VERSION ""

NS_ :

BS_:

BU_: ZCUR HDBI HDBM CID ZCUF ZCUT HDBT HDBA ZCUL

BO_ 913 ZCUR_VB1_7: 32 ZCUR
 SG_ ZCUR_HSDPowerOff1_Req : 96|24@1+ (1,0) [0|0] ""  ZCUF,HDBM,CID
 SG_ ZCUR_RRDrStpRsn_St : 68|4@1+ (1,0) [0|15] ""  HDBM
 SG_ ZCUR_FRDrLth_Err : 3|3@1+ (1,0) [0|7] ""  HDBM
 SG_ ZCUR_RExMirCtrl_Rsp : 36|1@1+ (1,0) [0|1] ""  HDBM
 SG_ ZCUR_RRDrLth_Err : 59|3@1+ (1,0) [0|7] ""  HDBM
 SG_ ZCUR_FRSeatAdj_Req : 30|2@1+ (1,0) [0|3] ""  HDBM
 SG_ ZCUR_FRSeatBackrestAdj_Req : 37|2@1+ (1,0) [0|3] ""  HDBM
 SG_ ZCUR_SFRTnLtErr_St : 80|1@1+ (1,0) [0|1] ""  HDBM
 SG_ ZCUR_FRSeatHgtAdj_Req : 28|2@1+ (1,0) [0|3] ""  HDBM
 SG_ ZCUR_FRSeatCshnAngAdj_Req : 40|2@1+ (1,0) [0|3] ""  HDBM
 SG_ ZCUR_FRHdlFrz_St : 7|1@1+ (1,0) [0|1] ""  HDBM
 SG_ ZCUR_FRWdwSw_St : 16|3@1+ (1,0) [0|7] ""  HDBM
 SG_ ZCUR_FRWdwMov_St : 24|2@1+ (1,0) [0|3] ""  HDBM
 SG_ ZCUR_RRWdwMov_St : 76|2@1+ (1,0) [0|3] ""  HDBM
 SG_ ZCUR_FRHdlStpRsn_St : 19|4@1+ (1,0) [0|15] ""  HDBM
 SG_ ZCUR_RRHdlStpRsn_St : 32|4@1+ (1,0) [0|15] ""  HDBM
 SG_ ZCUR_FRLthAjar_St : 26|1@1+ (1,0) [0|1] ""  HDBM
 SG_ ZCUR_RRLthAjar_St : 72|1@1+ (1,0) [0|1] ""  HDBM
 SG_ ZCUR_FRLthHlfLck_St : 27|1@1+ (1,0) [0|1] ""  HDBM
 SG_ ZCUR_RRLthHlfLck_St : 74|1@1+ (1,0) [0|1] ""  HDBM
 SG_ ZCUR_FRLthPawl_St : 15|1@1+ (1,0) [0|1] ""  HDBM
 SG_ ZCUR_RRLthPawl_St : 63|1@1+ (1,0) [0|1] ""  HDBM
 SG_ ZCUR_FRLthHome_St : 75|1@1+ (1,0) [0|1] ""  HDBM
 SG_ ZCUR_RRLthHome_St : 73|1@1+ (1,0) [0|1] ""  HDBM
 SG_ ZCUR_FRDrLth_St : 0|3@1+ (1,0) [0|7] ""  HDBI,HDBM
 SG_ ZCUR_FRHdlClsPstSW_St : 6|1@1+ (1,0) [0|1] ""  HDBM
 SG_ ZCUR_RRDrLth_St : 56|3@1+ (1,0) [0|7] ""  HDBI,HDBM
 SG_ ZCUR_RRHdlClsPstSW_St : 62|1@1+ (1,0) [0|1] ""  HDBM
 SG_ ZCUR_FRDrLthWrk_St : 8|3@1+ (1,0) [0|7] ""  HDBM
 SG_ ZCUR_FRHdlOpnPstSW_St : 23|1@1+ (1,0) [0|1] ""  HDBM
 SG_ ZCUR_RRDrLthWrk_St : 64|3@1+ (1,0) [0|7] ""  HDBM
 SG_ ZCUR_RRHdlOpnPstSW_St : 78|1@1+ (1,0) [0|1] ""  HDBM
 SG_ ZCUR_FRDrStpRsn_St : 11|4@1+ (1,0) [0|15] ""  HDBM
 SG_ ZCUR_RRHdlFrz_St : 79|1@1+ (1,0) [0|1] ""  HDBM
 SG_ ZCUR_FRSeatLegAngCshnExtAdj_Req : 42|2@1+ (1,0) [0|3] ""  HDBM
 SG_ ZCUR_RRWdwSw_St : 81|3@1+ (1,0) [0|7] ""  HDBM
 SG_ ZCUR_RRDrStpRsn2_St : 84|4@1+ (1,0) [0|15] ""  HDBM
 SG_ ZCUR_FRDrStpRsn2_St : 44|4@1+ (1,0) [0|15] ""  HDBM
 SG_ ZCUR_RRDrLthWrk2_St : 88|3@1+ (1,0) [0|7] ""  HDBM
 SG_ ZCUR_FRDrLthWrk2_St : 48|3@1+ (1,0) [0|7] ""  HDBM
 SG_ ZCUR_FRSunshadeSW_St : 95|1@1+ (1,0) [0|1] ""  HDBM
 SG_ ZCUR_FRLumbSuppFBAdj_Req : 93|2@1+ (1,0) [0|3] ""  HDBM
 SG_ ZCUR_FRLumbSuppUDAdj_Req : 91|2@1+ (1,0) [0|3] ""  HDBM
 SG_ ZCUR_FRDrLth2_Err : 120|3@1+ (1,0) [0|7] ""  HDBM
 SG_ ZCUR_RRDrLth2_Err : 123|3@1+ (1,0) [0|7] ""  HDBM
 SG_ ZCUR_RExMirLRMv_St : 192|2@1+ (1,0) [0|3] ""  HDBM
 SG_ ZCUR_RExMirUDStpRsn_St : 164|4@1+ (1,0) [0|15] ""  HDBM
 SG_ ZCUR_RExMirUDStp_Req : 131|3@1+ (1,0) [0|7] ""  HDBM
 SG_ ZCUR_RExMirLRStpRsn_St : 160|4@1+ (1,0) [0|15] ""  HDBM
 SG_ ZCUR_RExMirLRStp_Req : 128|3@1+ (1,0) [0|7] ""  HDBM
 SG_ ZCUR_RExMirUDMv_St : 194|2@1+ (1,0) [0|3] ""  HDBM
 SG_ ZCUR_FRSeatFBMv_St : 198|2@1+ (1,0) [0|3] ""  HDBM
 SG_ ZCUR_FRSeatBackrestMv_St : 200|2@1+ (1,0) [0|3] ""  HDBM
 SG_ ZCUR_FRSeatHgtMv_St : 202|2@1+ (1,0) [0|3] ""  HDBM
 SG_ ZCUR_FRSeatCshnAngMv_St : 204|2@1+ (1,0) [0|3] ""  HDBM
 SG_ ZCUR_FRLegAngCshnExtMv_St : 206|2@1+ (1,0) [0|3] ""  HDBM
 SG_ ZCUR_FRSeatFBStpRsn_St : 172|4@1+ (1,0) [0|15] ""  HDBM
 SG_ ZCUR_FRSeatFBStp_Req : 139|3@1+ (1,0) [0|7] ""  HDBM
 SG_ ZCUR_FRLegAngCshnExtStp_Req : 155|3@1+ (1,0) [0|7] ""  HDBM
 SG_ ZCUR_FRSeatBackrestStpRsn_St : 176|4@1+ (1,0) [0|15] ""  HDBM
 SG_ ZCUR_FRSeatBackrestStp_Req : 144|3@1+ (1,0) [0|7] ""  HDBM
 SG_ ZCUR_FRSeatHgtStpRsn_St : 180|4@1+ (1,0) [0|15] ""  HDBM
 SG_ ZCUR_FRSeatHgtStp_Req : 147|3@1+ (1,0) [0|7] ""  HDBM
 SG_ ZCUR_FRSeatCshnAngStpRsn_St : 184|4@1+ (1,0) [0|15] ""  HDBM
 SG_ ZCUR_FRSeatCshnAngStp_Req : 152|3@1+ (1,0) [0|7] ""  HDBM
 SG_ ZCUR_FRLegAngCshnExtStpRsn_St : 188|4@1+ (1,0) [0|15] ""  HDBM
 SG_ ZCUR_FRHdlDbOprt_St : 126|2@1+ (1,0) [0|3] ""  HDBM
 SG_ ZCUR_RRHdlDbOprt_St : 134|2@1+ (1,0) [0|3] ""  HDBM
 SG_ ZCUR_RExMirCtrlStp_Req : 136|3@1+ (1,0) [0|7] ""  HDBM
 SG_ ZCUR_RExMirCtrlMv_St : 196|2@1+ (1,0) [0|3] ""  HDBM
 SG_ ZCUR_RExMirCtrlStpRsn_St : 168|4@1+ (1,0) [0|15] ""  HDBM
 SG_ ZCUR_FRSeatBelt_St : 39|1@1+ (1,0) [0|1] ""  HDBM

BO_ 96 ZCUF_VB1_1: 16 ZCUF
 SG_ ZCUF_ActlGearVaild_St : 35|1@1+ (1,0) [0|1] ""  HDBI,HDBM,HDBT
 SG_ ZCUF_ActlGear_St : 32|3@1+ (1,0) [0|7] ""  ZCUT,HDBM,HDBA,HDBT
 SG_ ZCUF_VehicleSpeed_Val : 16|13@1+ (0.05625,0) [0|300] "km/h"  ZCUT,HDBM
 SG_ ZCUF_VehicleSpeedValid_St : 15|1@1+ (1,0) [0|1] ""  ZCUT,HDBM
 SG_ ZCUF_FLTnLgt_St : 81|1@1+ (1,0) [0|1] ""  HDBM
 SG_ ZCUF_FRTnLgt_St : 77|1@1+ (1,0) [0|1] ""  HDBM
 SG_ ZCUF_Checksum4 : 0|8@1+ (1,0) [0|255] ""  ZCUT,HDBI,HDBM
 SG_ ZCUF_RollingCounter4 : 8|4@1+ (1,0) [0|15] ""  ZCUT,HDBI,HDBM
 SG_ ZCUF_LimpHomeRmnd_St : 36|1@1+ (1,0) [0|1] ""  HDBI,HDBM

BO_ 1441 ZCUF_VB1_7: 8 ZCUF
 SG_ ZCUF_HSDPowerOff1_Req : 16|24@1+ (1,0) [0|16777215] ""  HDBM

BO_ 352 HDBI_VB1_1: 32 HDBI
 SG_ HDBI_LowSpdVoi_Req : 160|2@1+ (1,0) [0|3] ""  HDBM
 SG_ HDBI_LowSpdVoiTyp_Req : 162|3@1+ (1,0) [0|7] ""  HDBM
 SG_ HDBI_NFCLockUnlock_Req : 126|2@1+ (1,0) [0|3] ""  HDBM
 SG_ HDBI_RLDoorBtn_Req : 100|2@1+ (1,0) [0|3] ""  HDBM
 SG_ HDBI_RearFogBm_Req : 110|2@1+ (1,0) [0|3] ""  HDBM
 SG_ HDBI_EtnlLgt_Req : 107|3@1+ (1,0) [0|7] ""  HDBM
 SG_ HDBI_CheckSum1 : 80|8@1+ (1,0) [0|255] ""  HDBM
 SG_ HDBI_RollingCounter1 : 88|4@1+ (1,0) [0|15] ""  HDBM

BO_ 272 HDBM_VB1_1: 32 HDBM
 SG_ HDBM_FLDoor_St : 16|2@1+ (1,0) [0|3] ""  HDBI,ZCUF
 SG_ HDBM_LeftTurnLgt_Req : 40|1@1+ (1,0) [0|1] ""  ZCUT,HDBI,ZCUF,ZCUL
 SG_ HDBM_RgtTurnLgt_Req : 41|1@1+ (1,0) [0|1] ""  ZCUT,HDBI,ZCUF,ZCUR
 SG_ HDBM_PowerMode_St : 32|3@1+ (1,0) [0|7] ""  ZCUT,HDBI,ZCUL,ZCUR,HDBT,ZCUF,HDBA
 SG_ HDBM_FRDoor_St : 18|2@1+ (1,0) [0|3] ""  HDBA
 SG_ HDBM_RLDoor_St : 20|2@1+ (1,0) [0|3] ""  HDBI
 SG_ HDBM_RRDoor_St : 22|2@1+ (1,0) [0|3] ""  HDBI
 SG_ HDBM_CheckSum1 : 0|8@1+ (1,0) [0|255] ""  ZCUT,ZCUF,ZCUL,HDBA,ZCUR
 SG_ HDBM_RollingCounter1 : 8|4@1+ (1,0) [0|15] ""  ZCUT,ZCUF,ZCUL,HDBA,ZCUR
 SG_ HDBM_TargCoastRegen_Req : 104|8@1+ (0.5,0) [0|100] "％"  ZCUF
 SG_ HDBM_DMSPTModeChg_Req : 80|4@1+ (1,0) [0|15] ""  ZCUF
 SG_ HDBM_DMSEPSModeChg_Req : 84|4@1+ (1,0) [0|15] "" Vector__XXX
 SG_ HDBM_DMSESCModeChg_Req : 88|4@1+ (1,0) [0|15] "" Vector__XXX
 SG_ HDBM_ChrgCap_St : 24|2@1+ (1,0) [0|3] ""  ZCUT

BO_ 689 HDBM_VB1_2: 32 HDBM
 SG_ HDBM_TCMACSOV_Req : 0|2@1+ (1,0) [0|3] "" Vector__XXX
 SG_ HDBM_TCMHPLowPressSOV_Req : 14|2@1+ (1,0) [0|3] "" Vector__XXX
 SG_ HDBM_TCMHPHighPressSOV_Req : 12|2@1+ (1,0) [0|3] "" Vector__XXX
 SG_ HDBM_HEXVInit_Req : 3|1@1+ (1,0) [0|1] "" Vector__XXX
 SG_ HDBM_CHVHTrgtPwr_Req : 32|8@1+ (50,0) [0|12000] "" Vector__XXX
 SG_ HDBM_CHVHHvCooltHeatEn_Req : 4|1@1+ (1,0) [0|1] "" Vector__XXX
 SG_ HDBM_HEXVSet_Req : 104|16@1+ (1,0) [0|576] "" Vector__XXX
 SG_ HDBM_V3WHeatEnb_Req : 6|1@1+ (1,0) [0|1] "" Vector__XXX
 SG_ HDBM_V3WHeatTargetPst_Req : 40|8@1+ (1,0) [0|100] "" Vector__XXX
 SG_ HDBM_HeatPumpEnb_Req : 7|1@1+ (1,0) [0|1] "" Vector__XXX
 SG_ HDBM_HeatPumpTargetSpdPct_Req : 48|8@1+ (1,0) [0|100] "" Vector__XXX
 SG_ HDBM_OHXEXVMoveEn_Req : 17|1@1+ (1,0) [0|1] "" Vector__XXX
 SG_ HDBM_CHLEXVMoveEn_Req : 16|1@1+ (1,0) [0|1] "" Vector__XXX
 SG_ HDBM_OHXEXVSet_Req : 72|16@1+ (1,0) [0|576] "" Vector__XXX
 SG_ HDBM_CHLEXVSet_Req : 56|16@1+ (1,0) [0|576] "" Vector__XXX
 SG_ HDBM_ComprActlPwr_Val : 88|8@1+ (100,0) [0|13000] ""  ZCUF
 SG_ HDBM_DMSVehMode_St : 168|4@1+ (1,0) [0|15] ""  ZCUF
 SG_ HDBM_CHVHActlPwr_Val : 96|8@1+ (100,0) [0|13000] ""  ZCUF
 SG_ HDBM_ACSysTotPwr_Req : 120|10@1+ (100,0) [0|40000] ""  ZCUF
 SG_ HDBM_DMSPTMode_St : 160|3@1+ (1,0) [0|7] ""  HDBI,ZCUF
 SG_ HDBM_DMSEPSModeInfo_St : 163|3@1+ (1,0) [0|7] ""  HDBI
 SG_ HDBM_ACHVTotoaPower_Req : 130|10@1+ (100,0) [0|40000] ""  ZCUF
 SG_ HDBM_SRRSBR_Req : 147|1@1+ (1,0) [0|1] ""  HDBI
 SG_ HDBM_SBRSound_Req : 148|1@1+ (1,0) [0|1] ""  HDBI
 SG_ HDBM_FLSBR_Req : 144|1@1+ (1,0) [0|1] ""  HDBI
 SG_ HDBM_FRSBR_Req : 145|1@1+ (1,0) [0|1] ""  HDBI
 SG_ HDBM_SRLSBR_Req : 146|1@1+ (1,0) [0|1] ""  HDBI
 SG_ HDBM_SRMSBR_Req : 149|1@1+ (1,0) [0|1] ""  HDBI
 SG_ HDBM_V3WHeatCalEnb_Req : 11|1@1+ (1,0) [0|1] "" Vector__XXX
 SG_ HDBM_OHXEXVInit_Req : 8|3@1+ (1,0) [0|7] "" Vector__XXX
 SG_ HDBM_CHLEXVInit_Req : 19|3@1+ (3,0) [0|7] "" Vector__XXX
 SG_ HDBM_CHVHTrgtTemp_Req : 24|8@1+ (1,-40) [-40|215] "℃" Vector__XXX
 SG_ HDBM_HEXVMoveEnb_Req : 18|1@1+ (1,0) [0|1] "" Vector__XXX
 SG_ HDBM_ACCMPwrLmt_Req : 216|8@1+ (100,0) [0|25400] "" Vector__XXX
 SG_ HDBM_ACCMErrorClean_Req : 210|2@1+ (1,0) [0|3] "" Vector__XXX
 SG_ HDBM_ACCMEnable_Req : 212|2@1+ (1,0) [0|3] "" Vector__XXX
 SG_ HDBM_ACCMSpdCtrl_Req : 200|10@1+ (15,0) [0|1022] "" Vector__XXX
 SG_ HDBM_CmpmtInAirPmDnsty_Val : 184|10@1+ (1,0) [0|1023] ""  HDBI
 SG_ HDBM_CmpmtInAirPmAQI_St : 194|3@1+ (1,0) [0|7] ""  HDBI

BO_ 1488 HDBM_VB1_3: 32 HDBM
 SG_ HDBM_FLTpmsPress_Val : 0|8@1+ (1.373,0) [0|350] "Kpa"  HDBI,ZCUF,HDBA
 SG_ HDBM_EnvirTemp_Val : 208|8@1+ (0.5,-40) [-40|80] "℃"  HDBI,ZCUF
 SG_ HDBM_ComprWork_St : 142|2@1+ (1,0) [0|3] ""  ZCUF
 SG_ HDBM_FragChannel3Life_Val : 160|9@1+ (1,0) [0|360] "h"  HDBI
 SG_ HDBM_FLTpmsTemp_Val : 32|8@1+ (1,-40) [-40|214] "°C"  HDBI
 SG_ HDBM_FragCh1Type_Spec : 172|4@1+ (1,0) [0|15] ""  HDBI
 SG_ HDBM_EnSvLtCtrl_Req : 120|2@1+ (1,0) [0|3] ""  ZCUT,ZCUL,ZCUR
 SG_ HDBM_FragChannel2Life_Val : 176|9@1+ (1,0) [0|360] "h"  HDBI
 SG_ HDBM_FragChannel3Life_St : 192|9@1+ (1,0) [0|360] "h"  HDBI
 SG_ HDBM_FragCh2Type_Spec : 188|4@1+ (1,0) [0|15] ""  HDBI
 SG_ HDBM_FragCh3Type_Spec : 204|4@1+ (1,0) [0|15] ""  HDBI
 SG_ HDBM_RACCoolOrHeatOrVent_St : 136|2@1+ (1,0) [0|3] ""  ZCUF
 SG_ HDBM_FRTpmsPress_Val : 8|8@1+ (1.373,0) [0|350] "Kpa"  HDBI,ZCUF,HDBA
 SG_ HDBM_RLTpmsPress_Val : 16|8@1+ (1.373,0) [0|350] "Kpa"  HDBI,ZCUF,HDBA
 SG_ HDBM_RRTpmsPress_Val : 24|8@1+ (1.373,0) [0|350] "Kpa"  HDBI,ZCUF,HDBA
 SG_ HDBM_FRTpmsTemp_Val : 40|8@1+ (1,-40) [-40|214] "°C"  HDBI,HDBA
 SG_ HDBM_InFilterLifeRemind : 148|4@1+ (1,0) [0|15] ""  HDBI
 SG_ HDBM_RLTpmsTemp_Val : 48|8@1+ (1,-40) [-40|214] "°C"  HDBI,HDBA
 SG_ HDBM_RRTpmsTemp_Val : 56|8@1+ (1,-40) [-40|214] "°C"  HDBI,HDBA
 SG_ HDBM_FrtDeiceDefog_St : 140|2@1+ (1,0) [0|3] ""  HDBI,ZCUF
 SG_ HDBM_CampingMode_Rsp : 128|2@1+ (1,0) [0|3] "" Vector__XXX
 SG_ HDBM_CarMode_St : 216|3@1+ (1,0) [0|7] ""  ZCUT,HDBI,ZCUF,HDBA,HDBT
 SG_ HDBM_CHVHWork_St : 144|2@1+ (1,0) [0|3] ""  ZCUF
 SG_ HDBM_FLHdlBrkCnt_Val : 104|3@1+ (1,0) [0|7] ""  ZCUL
 SG_ HDBM_RLHdlBrkCnt_Val : 72|3@1+ (1,0) [0|7] ""  ZCUL
 SG_ HDBM_FRHdlBrkCnt_Val : 107|3@1+ (1,0) [0|7] ""  ZCUR
 SG_ HDBM_RRHdlBrkCnt_Val : 75|3@1+ (1,0) [0|7] ""  ZCUR

BO_ 421 HDBM_VB1_4: 32 HDBM
 SG_ HDBM_FLTpmsTempWarn_St : 24|1@1+ (1,0) [0|1] ""  HDBI,HDBA
 SG_ HDBM_FRTpmsTempWarn_St : 25|1@1+ (1,0) [0|1] ""  HDBI,HDBA
 SG_ HDBM_FLTpmsLeakWarn_St : 28|1@1+ (1,0) [0|1] ""  HDBI
 SG_ HDBM_FRTpmsLeakWarn_St : 29|1@1+ (1,0) [0|1] ""  HDBI
 SG_ HDBM_RLTpmsLeakWarn_St : 30|1@1+ (1,0) [0|1] ""  HDBI
 SG_ HDBM_RRTpmsLeakWarn_St : 31|1@1+ (1,0) [0|1] ""  HDBI
 SG_ HDBM_RemFDefrostTime_Rsp : 112|6@1+ (1,0) [0|40] "min"  HDBT
 SG_ HDBM_RemVentilateRefine_Rsp : 118|2@1+ (1,0) [0|3] ""  HDBT
 SG_ HDBM_RemVentilateRefineTime_Rsp : 120|6@1+ (1,0) [0|40] "min"  HDBT
 SG_ HDBM_RemAppointActive_Rsp : 128|2@1+ (1,0) [0|3] ""  HDBT
 SG_ HDBM_RemACUnavailRsn_Spec : 132|3@1+ (1,0) [0|7] ""  HDBT
 SG_ HDBM_RLTpmsTempWarn_St : 26|1@1+ (1,0) [0|1] ""  HDBI,HDBA
 SG_ HDBM_RRTpmsTempWarn_St : 27|1@1+ (1,0) [0|1] ""  HDBI,HDBA
 SG_ HDBM_RLTpmsPressWarn_St : 20|2@1+ (1,0) [0|3] ""  HDBI,HDBA
 SG_ HDBM_RRTpmsPressWarn_St : 22|2@1+ (1,0) [0|3] ""  HDBI,HDBA
 SG_ HDBM_FLTpmsPressWarn_St : 16|2@1+ (1,0) [0|3] ""  HDBI,HDBA
 SG_ HDBM_FRTpmsPressWarn_St : 18|2@1+ (1,0) [0|3] ""  HDBI,HDBA
 SG_ HDBM_CheckSum2 : 0|8@1+ (1,0) [0|255] "" Vector__XXX
 SG_ HDBM_RollingCounter2 : 8|4@1+ (1,0) [0|15] "" Vector__XXX
 SG_ HDBM_RRTpmsBattle_St : 35|1@1+ (1,0) [0|1] ""  HDBI
 SG_ HDBM_FLTpmsSensorFailure_St : 36|1@1+ (1,0) [0|1] ""  HDBI
 SG_ HDBM_FRTpmsSensorFailure_St : 37|1@1+ (1,0) [0|1] ""  HDBI
 SG_ HDBM_RLTpmsSensorFailure_St : 38|1@1+ (1,0) [0|1] ""  HDBI
 SG_ HDBM_RRTpmsSensorFailure_St : 39|1@1+ (1,0) [0|1] ""  HDBI
 SG_ HDBM_FLTpmsBattle_St : 32|1@1+ (1,0) [0|1] ""  HDBI
 SG_ HDBM_FRTpmsBattle_St : 33|1@1+ (1,0) [0|1] ""  HDBI
 SG_ HDBM_RLTpmsBattle_St : 34|1@1+ (1,0) [0|1] ""  HDBI

BO_ 816 HDBM_VB1_5: 32 HDBM
 SG_ HDBM_BckLtBrtDes_Req : 180|4@1+ (1,0) [0|15] ""  ZCUL,ZCUR
 SG_ HDBM_FLTpLtBrtDes_Req : 216|4@1+ (1,0) [0|15] ""  ZCUL
 SG_ HDBM_RLTpLtBrtDes_Req : 228|4@1+ (1,0) [0|15] ""  ZCUL
 SG_ HDBM_HoodLatch_St : 150|2@1+ (1,0) [0|3] ""  HDBI,ZCUF,HDBA
 SG_ HDBM_FRTpLtBrtDes_Req : 220|4@1+ (1,0) [0|15] ""  ZCUL
 SG_ HDBM_RRTpLtBrtDes_Req : 224|4@1+ (1,0) [0|15] ""  ZCUL
 SG_ HDBM_EtnlLgt_Rsp : 186|2@1+ (1,0) [0|3] ""  HDBI
 SG_ HDBM_CenterLock_St : 154|2@1+ (1,0) [0|3] ""  ZCUT,HDBI
 SG_ HDBM_LwLgt_Req : 119|1@1+ (1,0) [0|1] ""  HDBI,ZCUF
 SG_ HDBM_ACFaultLevel_St : 192|3@1+ (1,0) [0|7] ""  ZCUF
 SG_ HDBM_FLPstnLgt_Req : 112|1@1+ (1,0) [0|1] ""  HDBI,ZCUF
 SG_ HDBM_FRPstnLgt_Req : 113|1@1+ (1,0) [0|1] ""  HDBI,ZCUF
 SG_ HDBM_HighLgt_Req : 118|1@1+ (1,0) [0|1] ""  HDBI,ZCUF
 SG_ HDBM_OtkLgt_Req : 163|1@1+ (1,0) [0|1] ""  HDBI,ZCUF
 SG_ HDBM_FLWdwCtl_Req : 24|3@1+ (1,0) [0|7] ""  ZCUL
 SG_ HDBM_FRWdwCtl_Req : 28|3@1+ (1,0) [0|7] ""  ZCUR
 SG_ HDBM_SteerTiltAdj_Req : 40|2@1+ (1,0) [0|3] ""  ZCUL
 SG_ HDBM_RLWdwCtl_Req : 32|3@1+ (1,0) [0|7] ""  ZCUL
 SG_ HDBM_SteerTeleAdj_Req : 42|2@1+ (1,0) [0|3] ""  ZCUL
 SG_ HDBM_FWiperCtrl_Req : 92|3@1+ (1,0) [0|7] ""  ZCUF
 SG_ HDBM_FWiperWashCtrl_Req : 95|1@1+ (1,0) [0|1] ""  ZCUF
 SG_ HDBM_FLHdlCtrl_Req : 8|3@1+ (1,0) [0|7] ""  ZCUL
 SG_ HDBM_RLHdlCtrl_Req : 16|3@1+ (1,0) [0|7] ""  ZCUL
 SG_ HDBM_FRHdlCtrl_Req : 11|3@1+ (1,0) [0|7] ""  ZCUR
 SG_ HDBM_TpLtClrDes_Req : 184|2@1+ (1,0) [0|1] "" Vector__XXX
 SG_ HDBM_RRHdlCtrl_Req : 19|3@1+ (1,0) [0|7] ""  ZCUR
 SG_ HDBM_RLPstnLgt_Req : 114|1@1+ (1,0) [0|1] ""  ZCUT,HDBI
 SG_ HDBM_RRPstnLgt_Req : 115|1@1+ (1,0) [0|1] ""  ZCUT,HDBI
 SG_ HDBM_RearFogBm_Req : 177|1@1+ (1,0) [0|1] ""  ZCUT
 SG_ HDBM_RRWdwCtl_Req : 36|3@1+ (1,0) [0|7] ""  ZCUR
 SG_ HDBM_RsLgt_Req : 195|1@1+ (1,0) [0|1] ""  ZCUT
 SG_ HDBM_TrkLtCtrl_Req : 161|2@1+ (1,0) [0|3] ""  ZCUT
 SG_ HDBM_RollingCounter3 : 72|4@1+ (1,0) [0|15] ""  ZCUT
 SG_ HDBM_CheckSum3 : 64|8@1+ (1,0) [0|255] ""  ZCUT
 SG_ HDBM_FRHdlLearn_Req : 234|2@1+ (1,0) [0|3] ""  ZCUR
 SG_ HDBM_RRHdlLearn_Req : 238|2@1+ (1,0) [0|3] ""  ZCUR
 SG_ HDBM_FLHdlLearn_Req : 232|2@1+ (1,0) [0|3] ""  ZCUL
 SG_ HDBM_RLHdlLearn_Req : 236|2@1+ (1,0) [0|3] ""  ZCUL
 SG_ HDBM_FLTpLtClrDes_Req : 188|2@1+ (1,0) [0|3] ""  ZCUL
 SG_ HDBM_RLTpLtClrDes_Req : 196|2@1+ (1,0) [0|3] ""  ZCUL
 SG_ HDBM_FRTpLtClrDes_Req : 190|2@1+ (1,0) [0|3] ""  ZCUL
 SG_ HDBM_RRTpLtClrDes_Req : 198|2@1+ (1,0) [0|3] ""  ZCUL
 SG_ HDBM_SteerTiltSpd_Req : 59|5@1+ (5,0) [0|100] ""  ZCUL
 SG_ HDBM_SteerTeleSpd_Req : 51|5@1+ (5,0) [0|100] ""  ZCUL
 SG_ HDBM_SteerLn_Req : 50|1@1+ (1,0) [0|1] ""  ZCUL
 SG_ HDBM_ParkingSwitch_Req : 88|2@1+ (1,0) [0|3] "" Vector__XXX
 SG_ HDBM_EHBMBrkModeSet_Req : 104|3@1+ (1,0) [0|7] "" Vector__XXX
 SG_ HDBM_TCSSw_Req : 90|2@1+ (1,0) [0|3] "" Vector__XXX
 SG_ HDBM_AVHSw_Req : 96|2@1+ (1,0) [0|3] "" Vector__XXX
 SG_ HDBM_HDCSw_Req : 98|2@1+ (1,0) [0|3] "" Vector__XXX
 SG_ HDBM_CSTSw_Req : 100|2@1+ (1,0) [0|3] "" Vector__XXX
 SG_ HDBM_ESCSw_Req : 102|2@1+ (1,0) [0|3] "" Vector__XXX

BO_ 1489 HDBM_VB1_6: 32 HDBM
 SG_ HDBM_FragSwitchEn_Rsp : 16|2@1+ (1,0) [0|3] ""  HDBI
 SG_ HDBM_FragCh1Sw_St : 18|2@1+ (1,0) [0|3] ""  HDBI
 SG_ HDBM_FragCh2Sw_St : 20|2@1+ (1,0) [0|3] ""  HDBI
 SG_ HDBM_FragCh3Sw_St : 22|2@1+ (1,0) [0|3] ""  HDBI
 SG_ HDBM_FragConcLvl_Rsp : 24|3@1+ (1,0) [0|7] ""  HDBI
 SG_ HDBM_AQSAirQuality_Val : 28|4@1+ (1,0) [0|15] ""  HDBI
 SG_ HDBM_PM25Set_St : 40|2@1+ (1,0) [0|3] ""  HDBI
 SG_ HDBM_PM25Trigger_St : 42|2@1+ (1,0) [0|3] ""  HDBI
 SG_ HDBM_FDeiceDefrost_Rsp : 44|2@1+ (1,0) [0|3] ""  HDBI,ZCUF,HDBT
 SG_ HDBM_AutoDefogSensDectect_St : 46|2@1+ (1,0) [0|3] ""  HDBI
 SG_ HDBM_AutoDefrostSet_St : 48|2@1+ (1,0) [0|3] ""  HDBI
 SG_ HDBM_AutoDefrostTrigger_St : 50|2@1+ (1,0) [0|3] ""  HDBI
 SG_ HDBM_IONSet_St : 52|2@1+ (1,0) [0|3] ""  HDBI
 SG_ HDBM_ACSwtich_St : 64|2@1+ (1,0) [0|3] ""  HDBI
 SG_ HDBM_FACSwitch_Rsp : 66|2@1+ (1,0) [0|3] ""  HDBI,HDBT
 SG_ HDBM_FACAirFlowLevel_St : 68|4@1+ (1,0) [0|15] ""  HDBI
 SG_ HDBM_FAcCoolOrHeatOrVent_St : 72|2@1+ (1,0) [0|3] ""  HDBI,ZCUF
 SG_ HDBM_FLeftTempSet_St : 74|6@1+ (1,0) [0|63] ""  HDBI
 SG_ HDBM_FRightTempSet_St : 88|6@1+ (1,0) [0|63] ""  HDBI
 SG_ HDBM_FTempAreaSync_St : 94|2@1+ (1,0) [0|3] ""  HDBI
 SG_ HDBM_HvOnACM_Req : 96|1@1+ (1,0) [0|1] ""  ZCUF
 SG_ HDBM_HVWork_Req : 97|1@1+ (1,0) [0|1] ""  ZCUF
 SG_ HDBM_RESSCoolFault_St : 98|2@1+ (1,0) [0|3] ""  ZCUF
 SG_ HDBM_FACAirFlowLevelAuto_St : 100|2@1+ (1,0) [0|3] ""  HDBI
 SG_ HDBM_FACAirFlowModeAuto_St : 102|2@1+ (1,0) [0|3] ""  HDBI
 SG_ HDBM_FACCoolOrHeatOrVentAuto_St : 104|2@1+ (1,0) [0|3] ""  HDBI
 SG_ HDBM_TDrDegDes_Req : 160|8@1+ (0.5,0) [0|100] ""  ZCUT
 SG_ HDBM_TDrDegSet_Rsp : 168|8@1+ (0.5,0) [0|100] "" Vector__XXX
 SG_ HDBM_LDRLgt_Req : 216|1@1+ (1,0) [0|1] ""  ZCUF
 SG_ HDBM_RDRLgt_Req : 217|1@1+ (1,0) [0|0] ""  ZCUF
 SG_ HDBM_FLDrPdlLtCtrl_Req : 224|2@1+ (1,0) [3|3] ""  ZCUL
 SG_ HDBM_FRDrPdlLtCtrl_Req : 226|2@1+ (1,0) [0|3] ""  ZCUR
 SG_ HDBM_RLDrPdlLtCtrl_Req : 228|2@1+ (1,0) [0|3] ""  ZCUL
 SG_ HDBM_RRDrPdlLtCtrl_Req : 230|2@1+ (1,0) [0|3] ""  ZCUR
 SG_ HDBM_FLDrCtrl_Req : 192|2@1+ (1,0) [0|3] ""  ZCUL
 SG_ HDBM_FRDrCtrl_Req : 194|2@1+ (1,0) [0|3] ""  ZCUR
 SG_ HDBM_RLDrCtrl_Req : 196|2@1+ (1,0) [0|3] ""  ZCUL
 SG_ HDBM_RRDrCtrl_Req : 198|2@1+ (1,0) [0|3] ""  ZCUR
 SG_ HDBM_FLDrLthCinch_Req : 200|3@1+ (1,0) [0|7] ""  ZCUL
 SG_ HDBM_TDrSpdDes_Req : 235|3@1+ (1,0) [0|7] ""  ZCUT
 SG_ HDBM_TDrCtrl_Req : 232|3@1+ (1,0) [0|7] ""  ZCUT
 SG_ HDBM_TDrLthCinch_Req : 218|3@1+ (1,0) [0|7] ""  ZCUT
 SG_ HDBM_RLDrLthCinch_Req : 208|3@1+ (1,0) [0|7] ""  ZCUL
 SG_ HDBM_FRDrLthCinch_Req : 203|3@1+ (1,0) [0|7] ""  ZCUR
 SG_ HDBM_RRDrLthCinch_Req : 211|3@1+ (1,0) [0|7] ""  ZCUR
 SG_ HDBM_RLDrLthRls_Req : 120|3@1+ (1,0) [0|7] ""  ZCUL
 SG_ HDBM_FRDrLthRls_Req : 115|3@1+ (1,0) [0|7] ""  ZCUR
 SG_ HDBM_RRDrLthRls_Req : 123|3@1+ (1,0) [0|7] ""  ZCUR
 SG_ HDBM_FLDrLthRls_Req : 112|3@1+ (1,0) [0|7] ""  ZCUL
 SG_ HDBM_RESSCoolPwrLim_St : 111|1@1+ (1,0) [0|1] ""  ZCUF
 SG_ HDBM_RESSHeatFault_St : 106|2@1+ (1,0) [0|3] ""  ZCUF
 SG_ HDBM_ACMWork_St : 80|2@1+ (1,0) [0|3] ""  ZCUF
 SG_ HDBM_HeatRecycle_Req : 32|1@1+ (1,0) [0|1] ""  ZCUF
 SG_ HDBM_DeiceDefog_Req : 34|2@1+ (1,0) [0|3] ""  ZCUF
 SG_ HDBM_HeatRecycleDisable_St : 33|1@1+ (1,0) [0|1] ""  ZCUF
 SG_ HDBM_ChrgCapCtrl_Req : 238|2@1+ (1,0) [0|3] ""  ZCUT
 SG_ HDBM_TDrLthRls_Req : 240|3@1+ (1,0) [0|7] ""  ZCUT
 SG_ HDBM_RRDrLthCinchFbd_Req : 254|2@1+ (1,0) [0|3] ""  ZCUR
 SG_ HDBM_FLDrLthCinchFbd_Req : 248|2@1+ (1,0) [0|3] ""  ZCUL
 SG_ HDBM_RLDrLthCinchFbd_Req : 252|2@1+ (1,0) [0|3] ""  ZCUL
 SG_ HDBM_FRDrLthCinchFbd_Req : 250|2@1+ (1,0) [0|3] ""  ZCUR
 SG_ HDBM_ChrgCapLearn_Req : 246|2@1+ (1,0) [0|3] ""  ZCUT
 SG_ HDBM_IONSwitch_Req : 36|2@1+ (1,0) [0|3] ""  ZCUR
 SG_ HDBM_InPm25SnsrActn_Req : 38|2@1+ (1,0) [0|3] ""  ZCUR
 SG_ HDBM_TDrLthCinchFbd_Req : 244|2@1+ (1,0) [0|3] ""  ZCUT

BO_ 210 EGSM_MCAN1_1: 8 HDBM

BO_ 1500 HDBM_VB1_NMIndication: 32 HDBM
 SG_ HDBM_VB1_NetworkReqCondition0 : 0|8@1+ (1,0) [0|255] "" Vector__XXX
 SG_ HDBM_VB1_NetworkReqCondition1 : 8|8@1+ (1,0) [0|255] "" Vector__XXX
 SG_ HDBM_VB1_NetworkReqCondition2 : 16|8@1+ (1,0) [0|255] "" Vector__XXX
 SG_ HDBM_VB1_NetworkReqCondition3 : 24|8@1+ (1,0) [0|255] "" Vector__XXX
 SG_ HDBM_VB1_NetworkReqCondition4 : 32|8@1+ (1,0) [0|255] "" Vector__XXX
 SG_ HDBM_VB1_NetworkReqCondition5 : 40|8@1+ (1,0) [0|255] "" Vector__XXX
 SG_ HDBM_VB1_NetworkReqCondition6 : 48|8@1+ (1,0) [0|255] "" Vector__XXX
 SG_ HDBM_VB1_NetworkReqCondition7 : 56|8@1+ (1,0) [0|255] "" Vector__XXX
 SG_ HDBM_VB1_NetworkReqCondition8 : 64|8@1+ (1,0) [0|255] "" Vector__XXX
 SG_ HDBM_VB1_NetworkReqCondition9 : 72|8@1+ (1,0) [0|255] "" Vector__XXX
 SG_ HDBM_VB1_NetworkReqCondition10 : 80|8@1+ (1,0) [0|255] "" Vector__XXX
 SG_ HDBM_VB1_NetworkReqCondition11 : 88|8@1+ (1,0) [0|255] "" Vector__XXX
 SG_ HDBM_VB1_NetworkReqCondition12 : 96|8@1+ (1,0) [0|255] "" Vector__XXX
 SG_ HDBM_VB1_NetworkReqCondition13 : 104|8@1+ (1,0) [0|255] "" Vector__XXX
 SG_ HDBM_VB1_NetworkReqCondition14 : 112|8@1+ (1,0) [0|255] "" Vector__XXX
 SG_ HDBM_VB1_NetworkReqCondition15 : 120|8@1+ (1,0) [0|255] "" Vector__XXX
 SG_ HDBM_VB1_NetworkReqCondition16 : 128|8@1+ (1,0) [0|255] "" Vector__XXX
 SG_ HDBM_VB1_NetworkReqCondition17 : 136|8@1+ (1,0) [0|255] "" Vector__XXX
 SG_ HDBM_VB1_NetworkReqCondition18 : 144|8@1+ (1,0) [0|255] "" Vector__XXX
 SG_ HDBM_VB1_NetworkReqCondition19 : 152|8@1+ (1,0) [0|255] "" Vector__XXX
 SG_ HDBM_VB1_NetworkReqCondition20 : 160|8@1+ (1,0) [0|255] "" Vector__XXX
 SG_ HDBM_VB1_NetworkReqCondition21 : 168|8@1+ (1,0) [0|255] "" Vector__XXX
 SG_ HDBM_VB1_NetworkReqCondition22 : 176|8@1+ (1,0) [0|255] "" Vector__XXX
 SG_ HDBM_VB1_NetworkReqCondition23 : 184|8@1+ (1,0) [0|255] "" Vector__XXX
 SG_ HDBM_VB1_NetworkReqCondition24 : 192|8@1+ (1,0) [0|255] "" Vector__XXX
 SG_ HDBM_VB1_NetworkReqCondition25 : 200|8@1+ (1,0) [0|255] "" Vector__XXX
 SG_ HDBM_VB1_NetworkReqCondition26 : 208|8@1+ (1,0) [0|255] "" Vector__XXX
 SG_ HDBM_VB1_NetworkReqCondition27 : 216|8@1+ (1,0) [0|255] "" Vector__XXX
 SG_ HDBM_VB1_NetworkReqCondition28 : 224|8@1+ (1,0) [0|255] "" Vector__XXX
 SG_ HDBM_VB1_NetworkReqCondition29 : 232|8@1+ (1,0) [0|255] "" Vector__XXX
 SG_ HDBM_VB1_NetworkReqCondition30 : 240|8@1+ (1,0) [0|255] "" Vector__XXX
 SG_ HDBM_VB1_NetworkReqCondition31 : 248|8@1+ (1,0) [0|255] "" Vector__XXX

BO_ 1409 HDBM_NMWakeup: 32 HDBM
 SG_ HDBM_WakeupReq_HDBT : 0|1@1+ (1,0) [0|1] ""  HDBT
 SG_ HDBM_WakeupReq_HDBI : 8|8@1+ (1,0) [0|255] ""  HDBI
 SG_ HDBM_WakeupReq_HDBA : 16|8@1+ (1,0) [0|255] ""  HDBA
 SG_ HDBM_WakeupReq_HDBM : 24|8@1+ (1,0) [0|255] "" Vector__XXX
 SG_ HDBM_WakeupReq_ZCUF : 32|56@1+ (1,0) [0|0] ""  ZCUF
 SG_ HDBM_WakeupReq_ZCUL : 88|56@1+ (1,0) [0|0] ""  ZCUL
 SG_ HDBM_WakeupReq_ZCUR : 144|56@1+ (1,0) [0|0] ""  ZCUR
 SG_ HDBM_WakeupReq_ZCUT : 200|56@1+ (1,0) [0|0] ""  ZCUT

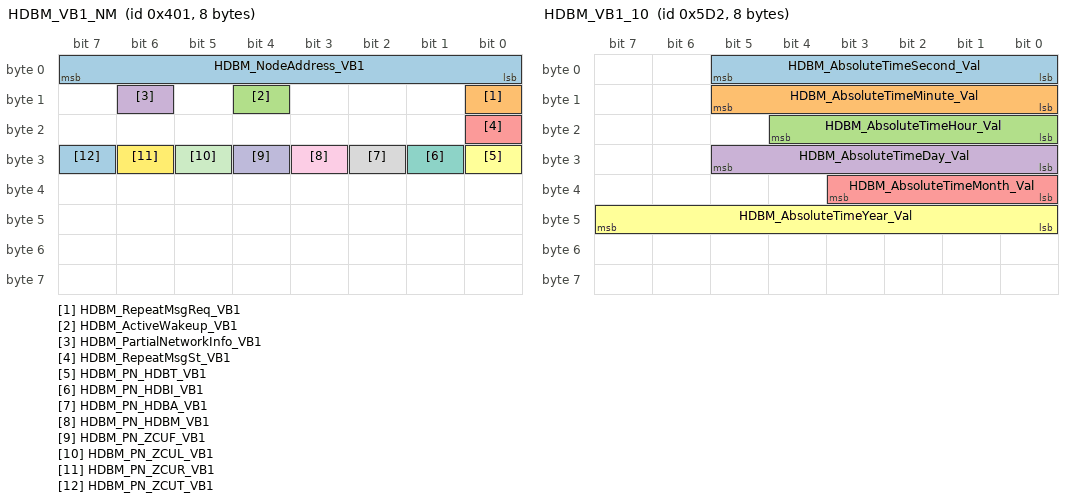
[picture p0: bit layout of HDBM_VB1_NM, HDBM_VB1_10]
BO_ 1025 HDBM_VB1_NM: 8 HDBM
 SG_ HDBM_NodeAddress_VB1 : 0|8@1+ (1,0) [0|255] ""  HDBI,ZCUF,ZCUL,HDBA,HDBT,ZCUR
 SG_ HDBM_RepeatMsgReq_VB1 : 8|1@1+ (1,0) [0|1] ""  ZCUT,HDBI,ZCUF,ZCUL,HDBA,HDBT,ZCUR
 SG_ HDBM_ActiveWakeup_VB1 : 12|1@1+ (1,0) [0|1] ""  ZCUT,HDBI,ZCUF,ZCUL,HDBA,HDBT,ZCUR
 SG_ HDBM_PartialNetworkInfo_VB1 : 14|1@1+ (1,0) [0|1] ""  ZCUT,HDBI,ZCUF,ZCUL,HDBA,HDBT,ZCUR
 SG_ HDBM_RepeatMsgSt_VB1 : 16|1@1+ (1,0) [0|1] ""  ZCUT,HDBI,ZCUF,ZCUL,HDBA,HDBT,ZCUR
 SG_ HDBM_PN_HDBT_VB1 : 24|1@1+ (1,0) [0|1] ""  ZCUT,HDBI,ZCUF,ZCUL,HDBA,HDBT,ZCUR
 SG_ HDBM_PN_HDBI_VB1 : 25|1@1+ (1,0) [0|1] ""  ZCUT,HDBI,ZCUF,ZCUL,HDBA,HDBT,ZCUR
 SG_ HDBM_PN_HDBA_VB1 : 26|1@1+ (1,0) [0|1] ""  ZCUT,HDBI,ZCUF,ZCUL,HDBA,HDBT,ZCUR
 SG_ HDBM_PN_HDBM_VB1 : 27|1@1+ (1,0) [0|1] ""  ZCUT,HDBI,ZCUF,ZCUL,HDBA,HDBT,ZCUR
 SG_ HDBM_PN_ZCUF_VB1 : 28|1@1+ (1,0) [0|1] ""  ZCUT,HDBI,ZCUF,ZCUL,HDBA,HDBT,ZCUR
 SG_ HDBM_PN_ZCUL_VB1 : 29|1@1+ (1,0) [0|1] ""  ZCUT,HDBI,ZCUF,ZCUL,HDBA,HDBT,ZCUR
 SG_ HDBM_PN_ZCUR_VB1 : 30|1@1+ (1,0) [0|1] ""  ZCUT,HDBI,ZCUF,ZCUL,HDBA,ZCUR,HDBT
 SG_ HDBM_PN_ZCUT_VB1 : 31|1@1+ (1,0) [0|1] ""  ZCUT,HDBI,ZCUF,ZCUL,HDBA,HDBT,ZCUR

BO_ 690 HDBM_VB1_7: 32 HDBM
 SG_ HDBM_BrkLgt_Req : 16|1@1+ (1,0) [0|1] ""  ZCUT
 SG_ HDBM_Horn_Req : 17|1@1+ (1,0) [0|1] ""  ZCUF
 SG_ HDBM_KeyResearch_Req : 18|2@1+ (1,0) [0|3] ""  HDBI
 SG_ HDBM_HHChrgPileRecognize_St : 72|1@1+ (1,0) [0|1] ""  ZCUT
 SG_ HDBM_AGSEn_Req : 152|1@1+ (1,0) [0|1] ""  ZCUF
 SG_ HDBM_AGSPosition_Req : 160|8@1+ (1,0) [0|255] ""  ZCUF
 SG_ HDBM_ECFEn_Req : 153|1@1+ (1,0) [0|1] ""  ZCUF
 SG_ HDBM_ECFSpdPercent_Req : 168|8@1+ (1,0) [0|100] ""  ZCUF
 SG_ HDBM_FHVACLeftMixPos_Req : 80|10@1+ (1,0) [0|1000] "千分比" Vector__XXX
 SG_ HDBM_FHVACRigtMixPos_Req : 90|10@1+ (1,0) [0|1000] "千分比"  ZCUR
 SG_ HDBM_FHVACModePos_Req : 100|10@1+ (1,0) [0|1000] "千分比" Vector__XXX
 SG_ HDBM_FHVACCyclePos_Req : 110|10@1+ (1,0) [0|1000] ""  ZCUR
 SG_ HDBM_FHVACBypassPos_Req : 130|10@1+ (1,0) [0|1000] "千分比"  ZCUR
 SG_ HDBM_FHVACDefrostPos_Req : 140|10@1+ (1,0) [0|1000] "千分比"  ZCUR
 SG_ HDBM_FHVACBLWPWM_Req : 120|10@1+ (1,0) [0|1000] "千分比" Vector__XXX
 SG_ HDBM_FHVACBLWRelay_Req : 40|2@1+ (1,0) [0|3] ""  ZCUR
 SG_ HDBM_OTAMode_St : 42|3@1+ (1,0) [0|7] ""  ZCUF

BO_ 422 HDBM_VB1_8: 32 HDBM
 SG_ HDBM_FRSeatMsgStrth_Req : 109|3@1+ (1,0) [0|7] ""  ZCUR
 SG_ HDBM_SRLSeatHt_Req : 128|5@1+ (5,0) [0|100] ""  ZCUT
 SG_ HDBM_SRLSeatVtlt_Req : 136|5@1+ (5,0) [0|100] ""  ZCUT
 SG_ HDBM_SRRSeatHt_Req : 144|5@1+ (5,0) [0|100] ""  ZCUT
 SG_ HDBM_SRRSeatVtlt_Req : 152|5@1+ (5,0) [0|100] ""  ZCUT
 SG_ HDBM_SteerHt_Req : 160|5@1+ (5,0) [0|100] ""  ZCUL
 SG_ HDBM_ExMirHt_Req : 168|5@1+ (5,0) [0|100] ""  ZCUL,ZCUR
 SG_ HDBM_FLSeatHt_Req : 80|5@1+ (5,0) [0|100] ""  ZCUL
 SG_ HDBM_FLSeatVtlt_Req : 88|5@1+ (5,0) [0|100] ""  ZCUL
 SG_ HDBM_FLSeatMsg_Req : 96|2@1+ (1,0) [0|3] ""  ZCUL
 SG_ HDBM_FLSeatMsgMode_Req : 98|4@1+ (1,0) [0|15] ""  ZCUL
 SG_ HDBM_FLSeatMsgStrth_Req : 85|3@1+ (1,0) [0|7] ""  ZCUL
 SG_ HDBM_FRSeatHt_Req : 104|5@1+ (5,0) [0|100] ""  ZCUR
 SG_ HDBM_FRSeatVtlt_Req : 112|5@1+ (5,0) [0|100] ""  ZCUR
 SG_ HDBM_FRSeatMsg_Req : 120|2@1+ (1,0) [0|3] ""  ZCUR
 SG_ HDBM_FRSeatMsgMode_Req : 122|4@1+ (1,0) [0|15] ""  ZCUR

BO_ 423 HDBM_VB1_9: 32 HDBM
 SG_ HDBM_FLSeatHgtAdj_Req : 46|2@1+ (1,0) [0|3] ""  ZCUL
 SG_ HDBM_FRLegAngCshnExtAdj_Req : 78|2@1+ (1,0) [0|3] ""  ZCUR
 SG_ HDBM_FLSeatFBAdjSpd_Req : 16|5@1+ (5,0) [0|100] ""  ZCUL
 SG_ HDBM_FLLegAngCshnExtAdj_Req : 38|2@1+ (1,0) [0|3] ""  ZCUL
 SG_ HDBM_FLSeatBackrestAdjSpd_Req : 24|5@1+ (5,0) [0|100] ""  ZCUL
 SG_ HDBM_FLSeatHgtAdjSpd_Req : 32|5@1+ (5,0) [0|100] ""  ZCUL
 SG_ HDBM_FLSeatCshnAngAdjSpd_Req : 40|5@1+ (5,0) [0|100] ""  ZCUL
 SG_ HDBM_FLLegAngCshnExtAdjSpd_Req : 48|5@1+ (5,0) [0|100] ""  ZCUL
 SG_ HDBM_FRSeatFBAdjSpd_Req : 56|5@1+ (5,0) [0|100] ""  ZCUR
 SG_ HDBM_FRSeatBackrestAdjSpd_Req : 64|5@1+ (5,0) [0|100] ""  ZCUR
 SG_ HDBM_FRSeatHgtAdjSpd_Req : 72|5@1+ (5,0) [0|100] ""  ZCUR
 SG_ HDBM_FRSeatCshnAngAdjSpd_Req : 80|5@1+ (5,0) [0|100] ""  ZCUR
 SG_ HDBM_FRLegAngCshnExtAdjSpd_Req : 88|5@1+ (5,0) [0|100] ""  ZCUR
 SG_ HDBM_FLLumbSuppFBAdj_Req : 22|2@1+ (1,0) [0|3] ""  ZCUL
 SG_ HDBM_FLLumbSuppUDAdj_Req : 30|2@1+ (1,0) [0|3] ""  ZCUL
 SG_ HDBM_FRLumbSuppFBAdj_Req : 70|2@1+ (1,0) [0|3] ""  ZCUR
 SG_ HDBM_FRLumbSuppUDAdj_Req : 62|2@1+ (1,0) [0|3] ""  ZCUR
 SG_ HDBM_FLSeatCshnAngAdj_Req : 144|2@1+ (1,0) [0|3] ""  ZCUL
 SG_ HDBM_FLSeatFBAdj_Req : 146|2@1+ (1,0) [0|3] ""  ZCUL
 SG_ HDBM_FLSeatBackrestAdj_Req : 148|2@1+ (1,0) [0|3] ""  ZCUL
 SG_ HDBM_FRSeatHgtAdj_Req : 86|2@1+ (1,0) [0|3] ""  ZCUR
 SG_ HDBM_FRSeatFBAdj_Req : 98|2@1+ (1,0) [0|3] ""  ZCUR
 SG_ HDBM_FRSeatBackrestAdj_Req : 100|2@1+ (1,0) [0|3] ""  ZCUR
 SG_ HDBM_FRSeatCshnAngAdj_Req : 96|2@1+ (1,0) [0|3] ""  ZCUR
 SG_ HDBM_RExMirUDAdj_Req : 124|2@1+ (1,0) [0|3] ""  ZCUR
 SG_ HDBM_RExMirLRAdj_Req : 126|2@1+ (1,0) [0|3] ""  ZCUR
 SG_ HDBM_LExMirUDAdj_Req : 120|2@1+ (1,0) [0|3] ""  ZCUL
 SG_ HDBM_LExMirLRAdj_Req : 122|2@1+ (1,0) [0|3] ""  ZCUL
 SG_ HDBM_RollingCounter4 : 136|4@1+ (1,0) [0|15] ""  ZCUL,ZCUR
 SG_ HDBM_CheckSum4 : 128|8@1+ (1,0) [0|255] ""  ZCUL,ZCUR
 SG_ HDBM_LExMirCtrl_Req : 109|2@1+ (1,0) [0|3] ""  ZCUL
 SG_ HDBM_RExMirCtrl_Req : 117|2@1+ (1,0) [0|3] ""  ZCUR
 SG_ HDBM_LExMirCtrlSpd_Req : 104|5@1+ (5,0) [0|100] ""  ZCUL
 SG_ HDBM_RExMirCtrlSpd_Req : 112|5@1+ (5,0) [0|100] ""  ZCUR
 SG_ HDBM_RExMirLRAdjSpd_Req : 200|5@1+ (5,0) [0|100] ""  ZCUR
 SG_ HDBM_LExMirUDAdjSpd_Req : 192|5@1+ (5,0) [0|100] ""  ZCUL
 SG_ HDBM_LExMirLRAdjSpd_Req : 184|5@1+ (5,0) [0|100] ""  ZCUL
 SG_ HDBM_RExMirUDAdjSpd_Req : 208|5@1+ (5,0) [0|100] ""  ZCUR

BO_ 1490 HDBM_VB1_10: 8 HDBM
 SG_ HDBM_AbsoluteTimeSecond_Val : 0|6@1+ (1,0) [0|59] "Second"  ZCUT,ZCUF
 SG_ HDBM_AbsoluteTimeMinute_Val : 8|6@1+ (1,0) [0|59] "Minute"  ZCUT,ZCUF
 SG_ HDBM_AbsoluteTimeHour_Val : 16|5@1+ (1,0) [0|23] "Hour"  ZCUT,ZCUF
 SG_ HDBM_AbsoluteTimeDay_Val : 24|6@1+ (1,0) [1|31] "Day"  ZCUT
 SG_ HDBM_AbsoluteTimeMonth_Val : 32|4@1+ (1,0) [1|12] "Month"  ZCUT,ZCUF
 SG_ HDBM_AbsoluteTimeYear_Val : 40|8@1+ (1,1970) [1970|2100] "Year"  ZCUT,ZCUF

BO_ 817 HDBM_VB1_11: 32 HDBM
 SG_ HDBM_RemCtrlACDuration_Req : 16|6@1+ (1,0) [0|40] "min" Vector__XXX
 SG_ HDBM_RemCtrlACRevnActive_Req : 22|2@1+ (1,0) [0|3] "" Vector__XXX
 SG_ HDBM_RemCtrlThmlMag_Req : 26|2@1+ (1,0) [0|3] ""  ZCUF
 SG_ HDBM_RemCtrlFACAuto_Req : 28|2@1+ (1,0) [0|3] "" Vector__XXX
 SG_ HDBM_RemCtrlThmlMagDurn_Req : 32|10@1+ (1,0) [0|1000] "min" Vector__XXX
 SG_ HDBM_RemCtrlFACDfrDef_Req : 42|2@1+ (1,0) [0|3] "" Vector__XXX
 SG_ HDBM_RemCtrlAirClean_Req : 44|2@1+ (1,0) [0|3] "" Vector__XXX
 SG_ HDBM_RemCtrlAirCleanDurn_Req : 48|6@1+ (1,0) [0|40] "min" Vector__XXX
 SG_ HDBM_FLBckupDoorCtrl_Req : 136|2@1+ (1,0) [0|3] "" Vector__XXX
 SG_ HDBM_FRBckupDoorCtrl_Req : 138|2@1+ (1,0) [0|3] "" Vector__XXX
 SG_ HDBM_RLBckupDoorCtrl_Req : 140|2@1+ (1,0) [0|3] "" Vector__XXX
 SG_ HDBM_RRBckupDoorCtrl_Req : 142|2@1+ (1,0) [0|3] "" Vector__XXX
 SG_ HDBM_Whitelistsync_Req : 64|4@1+ (1,0) [0|7] ""  HDBI
 SG_ HDBM_RollingCounter6 : 128|4@1+ (1,0) [0|15] "" Vector__XXX
 SG_ HDBM_CheckSum6 : 120|8@1+ (1,0) [0|255] "" Vector__XXX

BO_ 353 HDBM_VB1_12: 32 HDBM
 SG_ HDBM_PowertrainRestrict_Req : 80|2@1+ (1,0) [0|3] ""  ZCUF
 SG_ HDBM_ChargeCutOffSOC_Req : 24|8@1+ (0.5,0) [0|100] ""  ZCUT

BO_ 128 HBDM_VB1_13: 32 HDBM
 SG_ HDBM_AmLtTarget1_Req : 0|8@1+ (1,0) [0|255] ""  ZCUL
 SG_ HDBM_AmLtTarget2_Req : 8|8@1+ (1,0) [0|255] ""  ZCUR
 SG_ HDBM_AmLtTarget3_Req : 16|8@1+ (1,0) [0|255] ""  ZCUL
 SG_ HDBM_AmLtBrt_Req : 32|8@1+ (1,0) [0|255] ""  ZCUL,ZCUR
 SG_ HDBM_AmLtRedVal_Req : 40|8@1+ (1,0) [0|255] ""  ZCUL,ZCUR
 SG_ HDBM_AmLtGreenVal_Req : 48|8@1+ (1,0) [0|255] ""  ZCUL,ZCUR
 SG_ HDBM_AmLtBlueVal_Req : 56|8@1+ (1,0) [0|255] ""  ZCUL,ZCUR
 SG_ HDBM_AmLtSpd_Req : 64|4@1+ (1,0) [0|15] ""  ZCUL,ZCUR
 SG_ HDBM_AmLtHornClrMd_Req : 68|2@1+ (1,0) [0|3] ""  ZCUL,ZCUR
 SG_ HDBM_AmLtHornWrkMd_Req : 70|2@1+ (1,0) [0|3] ""  ZCUL,ZCUR

BO_ 80 ZCUT_VB1_1: 32 ZCUT
 SG_ ZCUT_BatteryVolt_Val : 154|12@1+ (0.25,0) [0|1023.25] "V"  HDBI,ZCUF,HDBM

BO_ 81 ZCUT_VB1_2: 32 ZCUT
 SG_ ZCUT_DCCharge_St : 200|4@1+ (1,0) [0|15] ""  HDBI,ZCUF,HDBM
 SG_ ZCUT_ACCharge_St : 204|4@1+ (1,0) [0|15] ""  HDBI,ZCUF,HDBM
 SG_ ZCUT_CellOverTemp_St : 38|1@1+ (1,0) [0|1] ""  HDBI,ZCUF,HDBM
 SG_ ZCUT_RLBrkLgt_St : 128|1@1+ (1,0) [0|1] ""  HDBM
 SG_ ZCUT_HighBrkLgt_St : 129|1@1+ (1,0) [0|1] ""  HDBM
 SG_ ZCUT_RRBrkLgt_St : 130|1@1+ (1,0) [0|1] ""  HDBM
 SG_ ZCUT_State_St : 208|4@1+ (1,0) [0|15] ""  ZCUF,HDBM
 SG_ ZCUT_FastChrgCnctor_St : 22|2@1+ (1,0) [0|3] ""  HDBI,ZCUF,HDBM
 SG_ ZCUT_Current_Val : 168|16@1+ (0.1,-1500) [-1500|2500] "A"  HDBI,ZCUF,HDBM
 SG_ ZCUT_SOCDisplay_Val : 136|10@1+ (0.1,0) [0|100] "%"  HDBI,ZCUF,HDBM
 SG_ ZCUT_FaultLevel_Err : 24|4@1+ (1,0) [0|15] ""  ZCUF,HDBM

BO_ 208 ZCUT_VB1_3: 16 ZCUT
 SG_ ZCUT_RLTnLgt_St : 16|1@1+ (1,0) [0|1] ""  HDBM
 SG_ ZCUT_RRTnLgt_St : 17|1@1+ (1,0) [0|1] ""  HDBM
 SG_ ZCUT_ChrgCapSW_St : 32|3@1+ (1,0) [0|7] ""  HDBM

BO_ 544 ZCUT_VB1_4: 32 ZCUT
 SG_ ZCUT_ChrgDischrgCnct_St : 12|3@1+ (1,0) [0|7] ""  HDBI,ZCUF,HDBM,CID
 SG_ ZCUT_TrkLtWrk_St : 67|2@1+ (1,0) [0|3] ""  HDBM
 SG_ ZCUT_RLPstnLgt_St : 69|1@1+ (1,0) [0|1] ""  HDBM
 SG_ ZCUT_RRPstnLgt_St : 65|1@1+ (1,0) [0|1] ""  HDBM
 SG_ ZCUT_RLTnLgtErr_St : 24|1@1+ (1,0) [0|1] ""  HDBM
 SG_ ZCUT_RRTnLgtErr_St : 25|1@1+ (1,0) [0|1] ""  HDBM
 SG_ ZCUT_SRLSeatOcp_St : 26|2@1+ (1,0) [0|3] ""  HDBM
 SG_ ZCUT_SRRSeatOcp_St : 28|2@1+ (1,0) [0|3] ""  HDBM
 SG_ ZCUT_SRMSeatOcp_St : 30|2@1+ (1,0) [0|3] ""  HDBM
 SG_ ZCUT_TempModuMax_Val : 16|8@1+ (1,-40) [-40|120] "℃"  ZCUF,HDBM
 SG_ ZCUT_TRLSeatOcp_St : 74|2@1+ (1,0) [0|3] ""  HDBM
 SG_ ZCUT_TRRSeatOcp_St : 72|2@1+ (1,0) [0|3] ""  HDBM
 SG_ ZCUT_TempModuMin_Val : 88|8@1+ (1,-40) [-40|120] "℃"  ZCUF,HDBM
 SG_ ZCUT_SOCReal_Val : 160|10@1+ (0.1,0) [0|100] "%"  ZCUF,HDBM
 SG_ ZCUT_Checksum4 : 0|8@1+ (1,0) [0|255] ""  ZCUF,HDBM
 SG_ ZCUT_RollingCounter4 : 8|4@1+ (1,0) [0|15] ""  ZCUF,HDBM
 SG_ ZCUT_RearMirLtWrk_St : 40|2@1+ (1,0) [0|3] ""  HDBM
 SG_ ZCUT_RLRsLgt_St : 85|1@1+ (1,0) [0|1] ""  HDBM
 SG_ ZCUT_RRRsLgt_St : 84|1@1+ (1,0) [0|1] ""  HDBM
 SG_ ZCUT_ChrgCutOffSOCSetVal_Rsp : 208|8@1+ (0.5,0) [0|100] ""  HDBI,ZCUF,HDBM,HDBT
 SG_ ZCUT_HHchrgPileCnct_St : 111|1@1+ (1,0) [0|1] ""  HDBI,HDBM
 SG_ ZCUT_TRLSeatBelt_St : 70|1@1+ (1,0) [0|1] ""  HDBM
 SG_ ZCUT_TRRSeatBelt_St : 71|1@1+ (1,0) [0|1] ""  HDBM
 SG_ ZCUT_SRLSeatBelt_St : 76|1@1+ (1,0) [0|1] ""  HDBM
 SG_ ZCUT_SRMSeatBelt_St : 77|1@1+ (1,0) [0|1] ""  HDBM
 SG_ ZCUT_SRRSeatBelt_St : 78|1@1+ (1,0) [0|1] ""  HDBM
 SG_ ZCUT_DisplayCharge_St : 156|4@1+ (1,0) [0|15] ""  HDBI,HDBM

BO_ 548 ZCUT_VB1_5: 32 ZCUT
 SG_ ZCUT_HSDLVPower_St : 72|48@1+ (1,0) [0|0] ""  HDBM
 SG_ ZCUT_PERMLVPower_St : 136|16@1+ (1,0) [0|65535] ""  HDBM
 SG_ ZCUT_HSDLVPower_Err : 24|48@1+ (1,0) [0|0] ""  HDBM
 SG_ ZCUT_PERMLVPower_Err : 120|16@1+ (1,0) [0|65535] ""  HDBM

BO_ 929 ZCUT_VB1_7: 32 ZCUT
 SG_ ZCUT_TempModuMaxID_Dat : 104|8@1+ (1,0) [0|254] ""  HDBM
 SG_ ZCUT_TempModuMinID_Dat : 96|8@1+ (1,0) [0|254] ""  HDBM
 SG_ ZCUT_OverCharge_St : 13|1@1+ (1,0) [0|1] ""  HDBM
 SG_ ZCUT_TempProbeNum_Val : 24|6@1+ (1,0) [0|63] ""  HDBM
 SG_ ZCUT_VoltCellMaxID_Dat : 88|8@1+ (1,0) [0|254] ""  HDBM
 SG_ ZCUT_SubTempHighID_Dat : 40|8@1+ (1,0) [0|254] ""  HDBM
 SG_ ZCUT_VoltCellMax_Val : 64|16@1+ (1,0) [0|5000] "mV"  HDBM
 SG_ ZCUT_SubTempLowID_Dat : 32|8@1+ (1,0) [0|254] ""  HDBM
 SG_ ZCUT_VoltCellMinID_Dat : 80|8@1+ (1,0) [0|254] ""  HDBM
 SG_ ZCUT_SubRESSNum_Val : 120|8@1+ (1,0) [0|254] ""  HDBM
 SG_ ZCUT_VoltCellMin_Val : 48|16@1+ (1,0) [0|5000] "mV"  HDBM
 SG_ ZCUT_SubRESSID_Dat : 112|8@1+ (1,0) [0|254] ""  HDBM
 SG_ ZCUT_SOE_Val : 128|12@1+ (0.1,0) [0|408] "kwh"  ZCUF,HDBM
 SG_ ZCUT_CellUnderVolt_St : 17|1@1+ (1,0) [0|1] ""  ZCUF,HDBM
 SG_ ZCUT_PackOverVolt_St : 19|1@1+ (1,0) [0|1] ""  HDBM
 SG_ ZCUT_PackUnderVolt_St : 20|1@1+ (1,0) [0|1] ""  HDBM
 SG_ ZCUT_CellOverVolt_St : 21|1@1+ (1,0) [0|1] ""  ZCUF,HDBM
 SG_ ZCUT_SOCLow_St : 23|1@1+ (1,0) [0|1] ""  HDBM
 SG_ ZCUT_SOCHigh_St : 22|1@1+ (1,0) [0|1] ""  HDBM
 SG_ ZCUT_SOCSkip_St : 16|1@1+ (1,0) [0|1] ""  HDBM
 SG_ ZCUT_Mismatch_St : 18|1@1+ (1,0) [0|1] ""  HDBM
 SG_ ZCUT_CellVoltDeviation_St : 8|1@1+ (1,0) [0|1] ""  HDBM
 SG_ ZCUT_CellTempDeviation_St : 9|1@1+ (1,0) [0|1] ""  HDBM
 SG_ ZCUT_BatVolHighID_Dat : 144|8@1+ (1,0) [0|254] ""  HDBM
 SG_ ZCUT_BatVolLowID_Dat : 152|8@1+ (1,0) [0|254] ""  HDBM

BO_ 82 PCU_TCAN2_1: 8 ZCUT
 SG_ PCU_DCDCMode_St : 12|3@1+ (1,0) [0|7] ""  ZCUT,ZCUF,HDBM

BO_ 209 PCU_TCAN2_3: 8 ZCUT
 SG_ PCU_OBCACChrgCnctor_St : 12|2@1+ (1,0) [0|3] ""  ZCUT,HDBI,ZCUF,HDBM

BO_ 402 ZCUT_FD_RT_1: 32 ZCUT
 SG_ CCM_ChrgCapPst_St : 16|8@1+ (1,0) [0|127] ""  HDBI,HDBM
 SG_ CCM_ChrgCapMv_St : 24|2@1+ (1,0) [0|3] ""  HDBM
 SG_ ZCUT_FD_RT_1_CCMAvailable_St : 248|2@1+ (1,0) [0|3] ""  HDBI,HDBM
 SG_ CCM_ChrgCapLearn_St : 40|2@1+ (1,0) [0|3] ""  HDBM
 SG_ CCM_ChrgCapStpRsn_St : 44|4@1+ (1,0) [0|15] ""  HDBM
 SG_ CCM_ChrgCapStp_Req : 42|2@1+ (1,0) [0|3] ""  HDBM

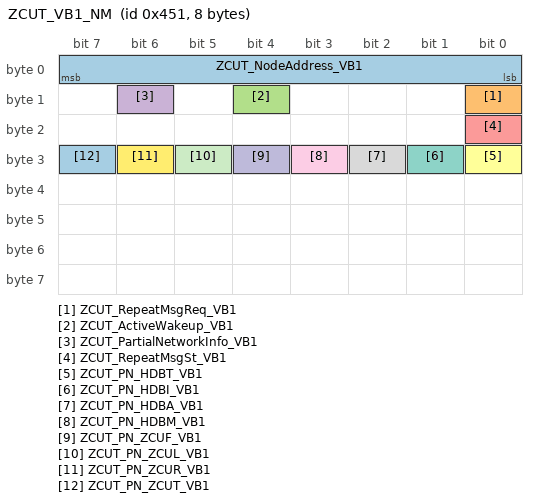
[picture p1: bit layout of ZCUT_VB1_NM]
BO_ 1105 ZCUT_VB1_NM: 8 ZCUT
 SG_ ZCUT_NodeAddress_VB1 : 0|8@1+ (1,0) [0|255] ""  HDBI,ZCUF,HDBM,ZCUL,HDBA,ZCUR,HDBT
 SG_ ZCUT_RepeatMsgReq_VB1 : 8|1@1+ (1,0) [0|1] ""  HDBI,ZCUF,HDBM,ZCUL,HDBA,ZCUR,HDBT
 SG_ ZCUT_ActiveWakeup_VB1 : 12|1@1+ (1,0) [0|1] ""  HDBI,ZCUF,HDBM,ZCUL,HDBA,ZCUR,HDBT
 SG_ ZCUT_PartialNetworkInfo_VB1 : 14|1@1+ (1,0) [0|1] ""  HDBI,ZCUF,HDBM,ZCUL,HDBA,ZCUR,HDBT
 SG_ ZCUT_RepeatMsgSt_VB1 : 16|1@1+ (1,0) [0|1] ""  HDBI,ZCUF,HDBM,ZCUL,HDBA,ZCUR,HDBT
 SG_ ZCUT_PN_HDBT_VB1 : 24|1@1+ (1,0) [0|1] ""  HDBI,ZCUF,HDBM,ZCUL,HDBA,ZCUR,HDBT
 SG_ ZCUT_PN_HDBI_VB1 : 25|1@1+ (1,0) [0|1] ""  HDBI,ZCUF,HDBM,ZCUL,HDBA,ZCUR,HDBT
 SG_ ZCUT_PN_HDBA_VB1 : 26|1@1+ (1,0) [0|1] ""  HDBI,ZCUF,HDBM,ZCUL,HDBA,ZCUR,HDBT
 SG_ ZCUT_PN_HDBM_VB1 : 27|1@1+ (1,0) [0|1] ""  HDBI,ZCUF,HDBM,ZCUL,HDBA,ZCUR,HDBT
 SG_ ZCUT_PN_ZCUF_VB1 : 28|1@1+ (1,0) [0|1] ""  HDBI,ZCUF,HDBM,ZCUL,HDBA,ZCUR,HDBT
 SG_ ZCUT_PN_ZCUL_VB1 : 29|1@1+ (1,0) [0|1] ""  HDBI,ZCUF,HDBM,ZCUL,HDBA,ZCUR,HDBT
 SG_ ZCUT_PN_ZCUR_VB1 : 30|1@1+ (1,0) [0|1] ""  HDBI,ZCUF,HDBM,ZCUL,HDBA,ZCUR,HDBT
 SG_ ZCUT_PN_ZCUT_VB1 : 31|1@1+ (1,0) [0|1] ""  HDBI,ZCUF,HDBM,ZCUL,HDBA,ZCUR,HDBT

BO_ 1413 ZCUT_NMWakeup: 32 ZCUT
 SG_ ZCUT_WakeupReq_HDBT : 0|1@1+ (1,0) [0|1] ""  HDBM,HDBT
 SG_ ZCUT_WakeupReq_HDBI : 8|8@1+ (1,0) [0|255] ""  HDBI,HDBM
 SG_ ZCUT_WakeupReq_HDBA : 16|8@1+ (1,0) [0|255] ""  HDBM,HDBA
 SG_ ZCUT_WakeupReq_HDBM : 24|8@1+ (1,0) [0|255] ""  HDBM
 SG_ ZCUT_WakeupReq_ZCUF : 32|56@1+ (1,0) [0|0] ""  ZCUF,HDBM
 SG_ ZCUT_WakeupReq_ZCUL : 88|56@1+ (1,0) [0|0] ""  HDBM,ZCUL
 SG_ ZCUT_WakeupReq_ZCUR : 144|56@1+ (1,0) [0|0] ""  HDBM,ZCUR
 SG_ ZCUT_WakeupReq_ZCUT : 200|56@1+ (1,0) [0|0] ""  HDBM

BO_ 1492 ZCUT_VB1_NMIndication: 32 ZCUT
 SG_ ZCUT_VB1_NetworkReqCondition0 : 0|8@1+ (1,0) [0|255] ""  HDBM
 SG_ ZCUT_VB1_NetworkReqCondition1 : 8|8@1+ (1,0) [0|255] ""  HDBM
 SG_ ZCUT_VB1_NetworkReqCondition2 : 16|8@1+ (1,0) [0|255] ""  HDBM
 SG_ ZCUT_VB1_NetworkReqCondition3 : 24|8@1+ (1,0) [0|255] ""  HDBM
 SG_ ZCUT_VB1_NetworkReqCondition4 : 32|8@1+ (1,0) [0|255] ""  HDBM
 SG_ ZCUT_VB1_NetworkReqCondition5 : 40|8@1+ (1,0) [0|255] ""  HDBM
 SG_ ZCUT_VB1_NetworkReqCondition6 : 48|8@1+ (1,0) [0|255] ""  HDBM
 SG_ ZCUT_VB1_NetworkReqCondition7 : 56|8@1+ (1,0) [0|255] ""  HDBM
 SG_ ZCUT_VB1_NetworkReqCondition8 : 64|8@1+ (1,0) [0|255] ""  HDBM
 SG_ ZCUT_VB1_NetworkReqCondition9 : 72|8@1+ (1,0) [0|255] ""  HDBM
 SG_ ZCUT_VB1_NetworkReqCondition10 : 80|8@1+ (1,0) [0|255] ""  HDBM
 SG_ ZCUT_VB1_NetworkReqCondition11 : 88|8@1+ (1,0) [0|255] ""  HDBM
 SG_ ZCUT_VB1_NetworkReqCondition12 : 96|8@1+ (1,0) [0|255] ""  HDBM
 SG_ ZCUT_VB1_NetworkReqCondition13 : 104|8@1+ (1,0) [0|255] ""  HDBM
 SG_ ZCUT_VB1_NetworkReqCondition14 : 112|8@1+ (1,0) [0|255] ""  HDBM
 SG_ ZCUT_VB1_NetworkReqCondition15 : 120|8@1+ (1,0) [0|255] ""  HDBM
 SG_ ZCUT_VB1_NetworkReqCondition16 : 128|8@1+ (1,0) [0|255] ""  HDBM
 SG_ ZCUT_VB1_NetworkReqCondition17 : 136|8@1+ (1,0) [0|255] ""  HDBM
 SG_ ZCUT_VB1_NetworkReqCondition18 : 144|8@1+ (1,0) [0|255] ""  HDBM
 SG_ ZCUT_VB1_NetworkReqCondition19 : 152|8@1+ (1,0) [0|255] ""  HDBM
 SG_ ZCUT_VB1_NetworkReqCondition20 : 160|8@1+ (1,0) [0|255] ""  HDBM
 SG_ ZCUT_VB1_NetworkReqCondition21 : 168|8@1+ (1,0) [0|255] ""  HDBM
 SG_ ZCUT_VB1_NetworkReqCondition22 : 176|8@1+ (1,0) [0|255] ""  HDBM
 SG_ ZCUT_VB1_NetworkReqCondition23 : 184|8@1+ (1,0) [0|255] ""  HDBM
 SG_ ZCUT_VB1_NetworkReqCondition24 : 192|8@1+ (1,0) [0|255] ""  HDBM
 SG_ ZCUT_VB1_NetworkReqCondition25 : 200|8@1+ (1,0) [0|255] ""  HDBM
 SG_ ZCUT_VB1_NetworkReqCondition26 : 208|8@1+ (1,0) [0|255] ""  HDBM
 SG_ ZCUT_VB1_NetworkReqCondition27 : 216|8@1+ (1,0) [0|255] ""  HDBM
 SG_ ZCUT_VB1_NetworkReqCondition28 : 224|8@1+ (1,0) [0|255] ""  HDBM
 SG_ ZCUT_VB1_NetworkReqCondition29 : 232|8@1+ (1,0) [0|255] ""  HDBM
 SG_ ZCUT_VB1_NetworkReqCondition30 : 240|8@1+ (1,0) [0|255] ""  HDBM
 SG_ ZCUT_VB1_NetworkReqCondition31 : 248|8@1+ (1,0) [0|255] ""  HDBM

BO_ 546 PCU_TCAN2_5: 8 ZCUT
 SG_ PCU_OBCACSocketLock_St : 27|3@1+ (1,0) [0|7] ""  ZCUT,HDBI,HDBM

BO_ 1328 PLGM_TCAN1_1: 8 ZCUT
 SG_ PLGM_TLthNeutral_St : 28|1@1+ (1,0) [0|1] ""  HDBM
 SG_ PLGM_TLthHlfLck_St : 27|1@1+ (1,0) [0|1] ""  HDBM
 SG_ PLGM_TLthAjar_St : 26|1@1+ (1,0) [0|1] ""  HDBM
 SG_ PLGM_TDrWrk_St : 21|3@1+ (1,0) [0|7] ""  HDBI,HDBM
 SG_ PLGM_TDrTripPst_Val : 13|8@1+ (0.5,0) [0|100] ""  HDBI,HDBM
 SG_ PLGM_TDrTchpadSW_St : 36|2@1+ (1,0) [0|3] ""  HDBM
 SG_ PLGM_TDrStpRsn_St : 8|5@1+ (1,0) [0|31] ""  HDBM
 SG_ PLGM_TDrLthWrk_St : 32|3@1+ (1,0) [0|7] ""  HDBM
 SG_ PLGM_TDrLth_St : 29|3@1+ (1,0) [0|7] ""  HDBI,HDBM
 SG_ PLGM_TDrLth_Err : 5|3@1+ (1,0) [0|7] ""  HDBM
 SG_ PLGM_TDrIntSW_St : 24|2@1+ (1,0) [0|3] ""  HDBM
 SG_ PLGM_SpdlStallEvt_St : 35|1@1+ (1,0) [0|1] ""  HDBM
 SG_ PLGM_PinchEvt_St : 2|3@1+ (1,0) [0|7] ""  HDBM
 SG_ PLGM_Followup_Req : 0|2@1+ (1,0) [0|3] ""  HDBM
 SG_ PLGM_TDrLSpdl_Err : 43|3@1+ (1,0) [0|7] ""  HDBM
 SG_ PLGM_TDrRSpdl_Err : 40|3@1+ (1,0) [0|7] ""  HDBM
 SG_ PLGM_InitLearn_St : 48|2@1+ (1,0) [0|3] ""  HDBM
 SG_ PLGM_MaxPstLn_St : 38|2@1+ (1,0) [0|3] ""  HDBM

BO_ 897 ZCUT_VB1_9: 32 ZCUT
 SG_ ZCUT_ChargeHVPower_Val : 16|14@1+ (0.1,0) [0|1000] "kW"  HDBI,HDBM
 SG_ ZCUT_RemainChrgTime_Val : 56|12@1+ (1,0) [0|1440] "min"  HDBI,ZCUF,HDBM
 SG_ ZCUT_SRRSeatVtlt_Rsp : 152|5@1+ (5,0) [0|100] "%"  HDBM
 SG_ ZCUT_SRRSeatVtltStpRsn_St : 120|4@1+ (1,0) [0|15] ""  HDBM
 SG_ ZCUT_SRLSeatHt_Rsp : 136|5@1+ (5,0) [0|100] "%"  HDBM
 SG_ ZCUT_SRLSeatHtStpRsn_St : 116|4@1+ (1,0) [0|15] ""  HDBM
 SG_ ZCUT_SRLSeatVtlt_Rsp : 128|5@1+ (5,0) [0|100] "%"  HDBM
 SG_ ZCUT_SRLSeatVtltStpRsn_St : 112|4@1+ (1,0) [0|15] ""  HDBM
 SG_ ZCUT_SRRSeatHt_Rsp : 144|5@1+ (5,0) [0|100] "%"  HDBM
 SG_ ZCUT_SRRSeatHtStpRsn_St : 124|4@1+ (1,0) [0|15] ""  HDBM

BO_ 1454 ZCUT_VB1_10: 32 ZCUT
 SG_ ZCUT_BattSerialNum_Dat : 0|16@1+ (1,0) [0|9999] ""  HDBM
 SG_ ZCUT_BattManuYear_Val : 16|8@1+ (1,0) [0|99] ""  HDBM
 SG_ ZCUT_BattManuMonth_Val : 24|8@1+ (1,0) [1|12] ""  HDBM
 SG_ ZCUT_BattManuDay_Val : 32|8@1+ (1,0) [1|31] ""  HDBM
 SG_ ZCUT_PackageTotalNum_Val : 48|2@1+ (1,0) [0|3] ""  HDBM
 SG_ ZCUT_CellTotalNum_Val : 40|8@1+ (1,0) [0|255] ""  HDBM

BO_ 256 ZCUR_VB1_1: 16 ZCUR
 SG_ ZCUR_FRHdlOprt_St : 16|2@1+ (1,0) [0|3] ""  HDBM
 SG_ ZCUR_RRHdlOprt_St : 18|2@1+ (1,0) [0|3] ""  HDBM
 SG_ ZCUR_FRDrIntSW_St : 12|2@1+ (1,0) [0|3] ""  HDBM
 SG_ ZCUR_RRDrIntSW_St : 14|2@1+ (1,0) [0|3] ""  HDBM
 SG_ ZCUR_SFRTnLt_St : 24|1@1+ (1,0) [0|1] ""  HDBM
 SG_ ZCUR_Checksum1 : 0|8@1+ (1,0) [0|255] ""  HDBM
 SG_ ZCUR_RollingCounter1 : 8|4@1+ (1,0) [0|15] ""  HDBM
 SG_ ZCUR_FRSeatOcp_St : 27|2@1+ (1,0) [0|3] ""  HDBM,HDBA
 SG_ ZCUR_FRWinPst_Rsp : 72|8@1+ (1,0) [0|255] ""  HDBM
 SG_ ZCUR_RRWinPst_Rsp : 80|8@1+ (1,0) [0|255] ""  HDBM

CM_ SG_ 913 ZCUR_HSDPowerOff1_Req "





ZCUR Power Off Notification
 ZCUR对域下被供电节点的下电通知信号，每个Bit位代表一个ECU。






";
CM_ SG_ 913 ZCUR_RRDrStpRsn_St "
右后门停止原因



";
CM_ SG_ 913 ZCUR_FRDrLth_Err "

右前门锁故障信号

";
CM_ SG_ 913 ZCUR_RExMirCtrl_Rsp "

右前外后视镜展开折叠状态反馈

";
CM_ SG_ 913 ZCUR_RRDrLth_Err "

右后门锁故障信号

";
CM_ SG_ 913 ZCUR_FRSeatAdj_Req "

副驾座椅前后调节请求

";
CM_ SG_ 913 ZCUR_FRSeatBackrestAdj_Req "

副驾座椅靠背调节请求

";
CM_ SG_ 913 ZCUR_SFRTnLtErr_St "


Side Right Turn Light State 右侧后视镜转向故障状态


";
CM_ SG_ 913 ZCUR_FRSeatHgtAdj_Req "


副驾座椅高低调节请求


";
CM_ SG_ 913 ZCUR_FRSeatCshnAngAdj_Req "

副驾座椅坐垫角度调节请求

";
CM_ SG_ 913 ZCUR_FRHdlFrz_St "

右前把手结冰状态

";
CM_ SG_ 913 ZCUR_FRWdwSw_St "


右前车窗开关状态


";
CM_ SG_ 913 ZCUR_FRWdwMov_St "

右前车窗运动状态

";
CM_ SG_ 913 ZCUR_RRWdwMov_St "

右后车窗运动状态

";
CM_ SG_ 913 ZCUR_FRHdlStpRsn_St "




右前把手停止原因




";
CM_ SG_ 913 ZCUR_RRHdlStpRsn_St "



 右后把手停止原因



";
CM_ SG_ 913 ZCUR_FRLthAjar_St "

右前门锁Ajar状态

";
CM_ SG_ 913 ZCUR_RRLthAjar_St "

右后门锁Ajar状态

";
CM_ SG_ 913 ZCUR_FRLthHlfLck_St "

右前门锁HalfLock状态

";
CM_ SG_ 913 ZCUR_RRLthHlfLck_St "

右后门锁HalfLock状态

";
CM_ SG_ 913 ZCUR_FRLthPawl_St "

右前门锁Pawl状态

";
CM_ SG_ 913 ZCUR_RRLthPawl_St "

右后门锁Pawl状态

";
CM_ SG_ 913 ZCUR_FRLthHome_St "

右前门锁Home状态

";
CM_ SG_ 913 ZCUR_RRLthHome_St "

右后门锁Home状态

";
CM_ SG_ 913 ZCUR_FRDrLth_St "

右前门锁状态

";
CM_ SG_ 913 ZCUR_FRHdlClsPstSW_St "

右前把手关闭位置开关状态

";
CM_ SG_ 913 ZCUR_RRDrLth_St " 右后门锁状态";
CM_ SG_ 913 ZCUR_RRHdlClsPstSW_St "

右后把手关闭位置开关状态

";
CM_ SG_ 913 ZCUR_FRDrLthWrk_St "

右前门锁工作状态

";
CM_ SG_ 913 ZCUR_FRHdlOpnPstSW_St "

右前把手打开位置开关状态

";
CM_ SG_ 913 ZCUR_RRDrLthWrk_St "

右前门锁工作状态

";
CM_ SG_ 913 ZCUR_RRHdlOpnPstSW_St "

右后把手打开位置开关状态

";
CM_ SG_ 913 ZCUR_FRDrStpRsn_St "
右前门停止原因


";
CM_ SG_ 913 ZCUR_RRHdlFrz_St "

右后把手结冰状态

";
CM_ SG_ 913 ZCUR_FRSeatLegAngCshnExtAdj_Req "
 副驾座椅腿托角度/坐垫延伸调节请求

";
CM_ SG_ 913 ZCUR_RRWdwSw_St "


右后车窗开关状态


";
CM_ SG_ 913 ZCUR_RRDrStpRsn2_St "
右后门停止原因2

";
CM_ SG_ 913 ZCUR_FRDrStpRsn2_St "
右前门停止原因2

";
CM_ SG_ 913 ZCUR_RRDrLthWrk2_St "
 右前门锁工作状态
";
CM_ SG_ 913 ZCUR_FRDrLthWrk2_St "
 右前门锁工作状态2
";
CM_ SG_ 913 ZCUR_FRSunshadeSW_St "

右前遮阳板开关状态

";
CM_ SG_ 913 ZCUR_FRLumbSuppFBAdj_Req "

副驾座椅腰托前后调节请求

";
CM_ SG_ 913 ZCUR_FRLumbSuppUDAdj_Req "

副驾座椅腰托上下调节请求

";
CM_ SG_ 913 ZCUR_FRDrLth2_Err "
右前门锁故障信号2

";
CM_ SG_ 913 ZCUR_RRDrLth2_Err "
右后门锁故障信号2

";
CM_ SG_ 913 ZCUR_RExMirLRMv_St "

右外后视镜左右运动状态

";
CM_ SG_ 913 ZCUR_RExMirUDStpRsn_St "


右外后视镜上下停止原因


";
CM_ SG_ 913 ZCUR_RExMirUDStp_Req "


右外后视镜上下停止请求


";
CM_ SG_ 913 ZCUR_RExMirLRStpRsn_St "


右外后视镜左右停止原因


";
CM_ SG_ 913 ZCUR_RExMirLRStp_Req "
右外后视镜左右停止请求


";
CM_ SG_ 913 ZCUR_RExMirUDMv_St "

右外后视镜上下运动状态

";
CM_ SG_ 913 ZCUR_FRSeatFBMv_St "


副驾座椅前后运动状态


";
CM_ SG_ 913 ZCUR_FRSeatBackrestMv_St "


副驾座椅靠背运动状态


";
CM_ SG_ 913 ZCUR_FRSeatHgtMv_St "

副驾座椅高低运动状态

";
CM_ SG_ 913 ZCUR_FRSeatCshnAngMv_St "

副驾座椅坐垫角度运动状态

";
CM_ SG_ 913 ZCUR_FRLegAngCshnExtMv_St "

副驾座椅腿托角度/坐垫延伸运动状态

";
CM_ SG_ 913 ZCUR_FRSeatFBStpRsn_St "


副驾座椅前后停止原因


";
CM_ SG_ 913 ZCUR_FRSeatFBStp_Req "
副驾座椅前后停止请求


";
CM_ SG_ 913 ZCUR_FRLegAngCshnExtStp_Req "


副驾座椅腿托角度/坐垫延伸停止请求


";
CM_ SG_ 913 ZCUR_FRSeatBackrestStpRsn_St "


副驾座椅靠背停止原因


";
CM_ SG_ 913 ZCUR_FRSeatBackrestStp_Req "


副驾座椅靠背停止请求


";
CM_ SG_ 913 ZCUR_FRSeatHgtStpRsn_St "


副驾座椅高低停止原因


";
CM_ SG_ 913 ZCUR_FRSeatHgtStp_Req "


副驾座椅高低停止请求


";
CM_ SG_ 913 ZCUR_FRSeatCshnAngStpRsn_St "


副驾座椅坐垫角度停止原因


";
CM_ SG_ 913 ZCUR_FRSeatCshnAngStp_Req "


副驾座椅坐垫角度停止请求


";
CM_ SG_ 913 ZCUR_FRLegAngCshnExtStpRsn_St "


副驾座椅腿托角度/坐垫延伸停止原因


";
CM_ SG_ 913 ZCUR_FRHdlDbOprt_St "

右前把手双拉操作

";
CM_ SG_ 913 ZCUR_RRHdlDbOprt_St "

右后把手双拉操作

";
CM_ SG_ 913 ZCUR_RExMirCtrlStp_Req "
右外后视镜展开折叠停止请求


";
CM_ SG_ 913 ZCUR_RExMirCtrlMv_St "

右外后视镜展开折叠运动状态

";
CM_ SG_ 913 ZCUR_RExMirCtrlStpRsn_St "


右外后视镜展开折叠停止原因


";
CM_ SG_ 913 ZCUR_FRSeatBelt_St "


副驾安全带状态


";
CM_ SG_ 96 ZCUF_ActlGearVaild_St "





Actual gear valid
 实际档位有效性





";
CM_ SG_ 96 ZCUF_ActlGear_St "





Actual gear
 实际档位





";
CM_ SG_ 96 ZCUF_VehicleSpeed_Val "


The vehicle speed calculated by ZCUF
ZCUF综合算出的车速


";
CM_ SG_ 96 ZCUF_VehicleSpeedValid_St "


Status of the vehicle speed calculated by ZCUF
ZCUF综合算出的车速有效标志位


";
CM_ SG_ 96 ZCUF_FLTnLgt_St "
 Front Left Turn Light左前转向灯状态
";
CM_ SG_ 96 ZCUF_FRTnLgt_St "
 Front Right Turn Light 右前转向灯状态
";
CM_ SG_ 96 ZCUF_Checksum4 "



E2E Signal Group Checksum
Checksum is the actual value after calculation. 
E2E信号组校验和
Checksum为计算后实际值



";
CM_ SG_ 96 ZCUF_RollingCounter4 "




E2E Signal Group Counter
Counter value is automatically accumulated, added from 0 to 14 and then looped to the initial value of 0. Every time a message is sent, counter adds 1.
E2E信号组计数器
Counter值为自动累加，从0加到14，然后循环至初始值0，每次报文发送，Counter加1




";
CM_ SG_ 96 ZCUF_LimpHomeRmnd_St "




Limp Home Remainder
跛行提示




";
CM_ SG_ 1441 ZCUF_HSDPowerOff1_Req "



 ZCUF Power Off Notification  ZCUF对域下被供电CAN节点的下电通知信号，每个Bit位代表一个ECU。



";
CM_ SG_ 352 HDBI_LowSpdVoi_Req "




低速提示音请求




";
CM_ SG_ 352 HDBI_LowSpdVoiTyp_Req " 低速提示音类型请求";
CM_ SG_ 352 HDBI_NFCLockUnlock_Req "


HDBI NFC钥匙解/闭锁请求


";
CM_ SG_ 352 HDBI_RLDoorBtn_Req " 左后门大屏按键控制请求";
CM_ SG_ 352 HDBI_RearFogBm_Req "

Direct Fog Lamp Control Command
雾灯控制

";
CM_ SG_ 352 HDBI_EtnlLgt_Req " 位置灯-近光灯灯光设置信号 ";
CM_ SG_ 272 HDBM_FLDoor_St "



左前门开关状态



";
CM_ SG_ 272 HDBM_LeftTurnLgt_Req "
Side Left Turn Light Command
左侧转向灯控制命令
";
CM_ SG_ 272 HDBM_RgtTurnLgt_Req "
Side Right Turn Light Command
右侧转向灯控制命令
";
CM_ SG_ 272 HDBM_PowerMode_St "





电源模式





";
CM_ SG_ 272 HDBM_FRDoor_St "

右前门开关状态


";
CM_ SG_ 272 HDBM_RLDoor_St "

左后门开关状态

";
CM_ SG_ 272 HDBM_RRDoor_St "

右后门开关状态

";
CM_ SG_ 272 HDBM_TargCoastRegen_Req "


Coast Regen Strength Set滑行能量回收强度


";
CM_ SG_ 272 HDBM_DMSPTModeChg_Req "



PT目标模式



";
CM_ SG_ 272 HDBM_DMSEPSModeChg_Req "



EPS 目标模式



";
CM_ SG_ 272 HDBM_DMSESCModeChg_Req "



EHBM目标模式



";
CM_ SG_ 272 HDBM_ChrgCap_St "

充电口盖状态反馈

";
CM_ SG_ 689 HDBM_TCMACSOV_Req "

制冷回路截止阀开关请求

";
CM_ SG_ 689 HDBM_TCMHPLowPressSOV_Req "

热泵回路低压截止阀开关请求

";
CM_ SG_ 689 HDBM_TCMHPHighPressSOV_Req "

热泵回路高压截止阀开关请求

";
CM_ SG_ 689 HDBM_HEXVInit_Req "


Master ECU request EXV to initialization                                          主节点ECU请求EXV初始化


";
CM_ SG_ 689 HDBM_CHVHTrgtPwr_Req "

CHVH功率限制（不限或者限制）

";
CM_ SG_ 689 HDBM_CHVHHvCooltHeatEn_Req "

CHVH使能信号

";
CM_ SG_ 689 HDBM_HEXVSet_Req "
Master ECU request the position
主节点ECU请求位置




";
CM_ SG_ 689 HDBM_V3WHeatEnb_Req "

3-way valve open request of heat circuit
加热回路三通阀开启请求

";
CM_ SG_ 689 HDBM_V3WHeatTargetPst_Req "

Heat circuit 3-way position request
加热回路三通阀位置请求

";
CM_ SG_ 689 HDBM_HeatPumpEnb_Req "

Heat pump open request
加热水泵开启请求

";
CM_ SG_ 689 HDBM_HeatPumpTargetSpdPct_Req "


Heat pump speed request
加热水泵转速请求


";
CM_ SG_ 689 HDBM_OHXEXVMoveEn_Req "

OHX EXV MoveEnable

";
CM_ SG_ 689 HDBM_CHLEXVMoveEn_Req "

Chiller EXV MoveEnable

";
CM_ SG_ 689 HDBM_OHXEXVSet_Req "

OHX EXV目标步数开度请求

";
CM_ SG_ 689 HDBM_CHLEXVSet_Req "
Chiller EXV目标步数开度请求
";
CM_ SG_ 689 HDBM_ComprActlPwr_Val "


Compressor actual power
压缩机实际功率


";
CM_ SG_ 689 HDBM_DMSVehMode_St "



整车当前驾驶模式



";
CM_ SG_ 689 HDBM_CHVHActlPwr_Val "


Coolant High Voltage Heater Power
水加热器实际功率


";
CM_ SG_ 689 HDBM_ACSysTotPwr_Req "
AC system total power request 空调系统总请求功率
";
CM_ SG_ 689 HDBM_DMSPTMode_St "


仪表显示-PT 当前模式


";
CM_ SG_ 689 HDBM_DMSEPSModeInfo_St "

仪表显示-EPS 当前模式

";
CM_ SG_ 689 HDBM_ACHVTotoaPower_Req "

AC system total power _Req
空调系统总请求功率

";
CM_ SG_ 689 HDBM_SRRSBR_Req "
二排右安全带未系提醒请求
";
CM_ SG_ 689 HDBM_SBRSound_Req "
安全带未系声音提醒请求
";
CM_ SG_ 689 HDBM_FLSBR_Req "
主驾安全带未系提醒请求
";
CM_ SG_ 689 HDBM_FRSBR_Req "
副驾安全带未系提醒请求
";
CM_ SG_ 689 HDBM_SRLSBR_Req "
二排左安全带未系提醒请求
";
CM_ SG_ 689 HDBM_SRMSBR_Req "
二排中安全带未系提醒请求
";
CM_ SG_ 689 HDBM_V3WHeatCalEnb_Req "
TCM暖芯三通阀自标定使能
";
CM_ SG_ 689 HDBM_OHXEXVInit_Req "
OHXEXV Initialization Request
";
CM_ SG_ 689 HDBM_CHLEXVInit_Req "
CHLEXV Initialization Request
";
CM_ SG_ 689 HDBM_CHVHTrgtTemp_Req "

CHVH_目标温度

";
CM_ SG_ 689 HDBM_HEXVMoveEnb_Req "
HVAC EXV MoveEnable
";
CM_ SG_ 689 HDBM_ACCMPwrLmt_Req "

输入功率限制

";
CM_ SG_ 689 HDBM_ACCMErrorClean_Req "

故障清除状态

";
CM_ SG_ 689 HDBM_ACCMEnable_Req "

压缩机使能信号

";
CM_ SG_ 689 HDBM_ACCMSpdCtrl_Req "

控制压缩机转速

";
CM_ SG_ 689 HDBM_CmpmtInAirPmAQI_St " AQI值";
CM_ SG_ 1488 HDBM_FLTpmsPress_Val "
左前轮胎压
";
CM_ SG_ 1488 HDBM_EnvirTemp_Val "



Environment temperature
环境温度



";
CM_ SG_ 1488 HDBM_ComprWork_St "

Compressor work state
压缩机工作状态

";
CM_ SG_ 1488 HDBM_FragChannel3Life_Val "
Fragrance remaining life of channel 1
1通道香氛剩余寿命
";
CM_ SG_ 1488 HDBM_FLTpmsTemp_Val "


左前轮胎温


";
CM_ SG_ 1488 HDBM_FragCh1Type_Spec "

Fragrance type of channel 1
1通道香氛种类信息

";
CM_ SG_ 1488 HDBM_EnSvLtCtrl_Req "
节能灯控制指令(化妆镜灯/扶手箱灯)
";
CM_ SG_ 1488 HDBM_FragChannel2Life_Val "
Fragrance remaining life of channel 2
2通道香氛剩余寿命
";
CM_ SG_ 1488 HDBM_FragChannel3Life_St "
Fragrance remaining life of channel 3
3通道香氛剩余寿命
";
CM_ SG_ 1488 HDBM_FragCh2Type_Spec "

Fragrance type of channel 2
2通道香氛种类信息

";
CM_ SG_ 1488 HDBM_FragCh3Type_Spec "

Fragrance type of channel 3
3通道香氛种类信息

";
CM_ SG_ 1488 HDBM_RACCoolOrHeatOrVent_St "

Rear air conditioner refrigeration heating ventilation state
后空调制冷制热通风状态

";
CM_ SG_ 1488 HDBM_FRTpmsPress_Val "
右前轮胎压
";
CM_ SG_ 1488 HDBM_RLTpmsPress_Val "
左后轮胎压
";
CM_ SG_ 1488 HDBM_RRTpmsPress_Val "
右后轮胎压
";
CM_ SG_ 1488 HDBM_FRTpmsTemp_Val "
右前轮胎温
";
CM_ SG_ 1488 HDBM_InFilterLifeRemind "
Filter remaining life remind in the vehicle
车内滤芯寿命提醒
";
CM_ SG_ 1488 HDBM_RLTpmsTemp_Val "
左后轮胎温
";
CM_ SG_ 1488 HDBM_RRTpmsTemp_Val "
右后轮胎温
";
CM_ SG_ 1488 HDBM_FrtDeiceDefog_St "
Front  Windows Defog and deice state
除霜除雾状态
";
CM_ SG_ 1488 HDBM_CampingMode_Rsp "

露营模式反馈

";
CM_ SG_ 1488 HDBM_CarMode_St "




车辆模式




";
CM_ SG_ 1488 HDBM_CHVHWork_St "

Coolant High Voltage Heater work state
水加热器工作状态

";
CM_ SG_ 1488 HDBM_FLHdlBrkCnt_Val "
左前把手破冰尝试次数
";
CM_ SG_ 1488 HDBM_RLHdlBrkCnt_Val "
左后把手破冰尝试次数
";
CM_ SG_ 1488 HDBM_FRHdlBrkCnt_Val "
右前把手破冰尝试次数
";
CM_ SG_ 1488 HDBM_RRHdlBrkCnt_Val "
右后把手破冰尝试次数
";
CM_ SG_ 421 HDBM_FLTpmsTempWarn_St "


左前轮胎温报警状态


";
CM_ SG_ 421 HDBM_FRTpmsTempWarn_St "


右前轮胎温报警状态


";
CM_ SG_ 421 HDBM_FLTpmsLeakWarn_St "

左前快速漏气报警信号

";
CM_ SG_ 421 HDBM_FRTpmsLeakWarn_St "

右前快速漏气报警信号

";
CM_ SG_ 421 HDBM_RLTpmsLeakWarn_St "

左后快速漏气报警信号

";
CM_ SG_ 421 HDBM_RRTpmsLeakWarn_St "


右后快速漏气报警信号


";
CM_ SG_ 421 HDBM_RemFDefrostTime_Rsp "


The reception state of remoted front deice opening time of which range is between1minutes and 40 mininutes.
远程前除霜开启时长接收状态反馈，时间范围为1~40分钟


";
CM_ SG_ 421 HDBM_RemVentilateRefine_Rsp "


Remoted ventilate and refine response
远程通风净化反馈


";
CM_ SG_ 421 HDBM_RemVentilateRefineTime_Rsp "


The reception state of remoted ventilate and refine opening time of which range is between1minutes and 40 mininutes.
远程通风净化开启时长接收状态反馈，时间范围为1~40分钟


";
CM_ SG_ 421 HDBM_RemAppointActive_Rsp "


AC remoted appoint active state response
空调远程预约激活状态反馈


";
CM_ SG_ 421 HDBM_RemACUnavailRsn_Spec "



Remote AC Unavailable Reason
远程空调无法启动原因



";
CM_ SG_ 421 HDBM_RLTpmsTempWarn_St "

左后轮胎温报警状态

";
CM_ SG_ 421 HDBM_RRTpmsTempWarn_St "

右后轮胎温报警状态

";
CM_ SG_ 421 HDBM_RLTpmsPressWarn_St "


左后轮胎压报警状态


";
CM_ SG_ 421 HDBM_RRTpmsPressWarn_St "


右后轮胎压报警状态


";
CM_ SG_ 421 HDBM_FLTpmsPressWarn_St "


左前轮胎压报警状态


";
CM_ SG_ 421 HDBM_FRTpmsPressWarn_St "


右前轮胎压报警状态


";
CM_ SG_ 421 HDBM_RRTpmsBattle_St "

Rear Right TPMS Battle State
 右后轮胎压传感器电池状态

";
CM_ SG_ 421 HDBM_FLTpmsSensorFailure_St "

Front Left TPMS Sensor Failure State
 左前轮胎压传感器信号状态

";
CM_ SG_ 421 HDBM_FRTpmsSensorFailure_St "

Front Right TPMS Sensor Failure State
 右前轮胎压传感器信号状态

";
CM_ SG_ 421 HDBM_RLTpmsSensorFailure_St "

Rear Left TPMS Sensor Failure State
 左后轮胎压传感器信号状态

";
CM_ SG_ 421 HDBM_RRTpmsSensorFailure_St "

Rear Right TPMS Sensor Failure State
 右后轮胎压传感器信号状态

";
CM_ SG_ 421 HDBM_FLTpmsBattle_St "

Front Left TPMS Battle State
 左前轮胎压传感器电池状态

";
CM_ SG_ 421 HDBM_FRTpmsBattle_St "

Front Right TPMS Battle State
 右前轮胎压传感器电池状态

";
CM_ SG_ 421 HDBM_RLTpmsBattle_St "

Rear Left TPMS Battle State
 左后轮胎压传感器电池状态

";
CM_ SG_ 816 HDBM_BckLtBrtDes_Req "

背光灯目标亮度指令

";
CM_ SG_ 816 HDBM_FLTpLtBrtDes_Req "

左前顶灯亮度目标指令

";
CM_ SG_ 816 HDBM_RLTpLtBrtDes_Req "

左后顶灯亮度目标指令

";
CM_ SG_ 816 HDBM_HoodLatch_St " 前舱盖开闭状态反馈";
CM_ SG_ 816 HDBM_FRTpLtBrtDes_Req "

右前顶灯亮度目标指令

";
CM_ SG_ 816 HDBM_RRTpLtBrtDes_Req "

右后顶灯亮度目标指令

";
CM_ SG_ 816 HDBM_EtnlLgt_Rsp "
 外部灯光设置反馈
";
CM_ SG_ 816 HDBM_CenterLock_St "
中控解闭锁状态
";
CM_ SG_ 816 HDBM_LwLgt_Req "


近光灯请求


";
CM_ SG_ 816 HDBM_ACFaultLevel_St "



AC system fault level 空调系统故障等级



";
CM_ SG_ 816 HDBM_FLPstnLgt_Req "
Front Left Position Light Command
左前位置灯控制命令
";
CM_ SG_ 816 HDBM_FRPstnLgt_Req "
Front Right Position Light Command
右前位置灯控制命令
";
CM_ SG_ 816 HDBM_HighLgt_Req " High Beam Light Command
 远光控制命令";
CM_ SG_ 816 HDBM_OtkLgt_Req "
Hight Beam Flash Command
超车灯控制命令
";
CM_ SG_ 816 HDBM_FLWdwCtl_Req "
左前车窗控制指令
";
CM_ SG_ 816 HDBM_FRWdwCtl_Req "
右前车窗控制指令
";
CM_ SG_ 816 HDBM_SteerTiltAdj_Req "


方向盘Tilt(上下)调节指令


";
CM_ SG_ 816 HDBM_RLWdwCtl_Req "
左后车窗控制指令
";
CM_ SG_ 816 HDBM_SteerTeleAdj_Req "


方向盘Telescope(伸缩)调节指令


";
CM_ SG_ 816 HDBM_FWiperCtrl_Req "

前雨刮控制命令

";
CM_ SG_ 816 HDBM_FWiperWashCtrl_Req "

前雨刮洗涤控制命令

";
CM_ SG_ 816 HDBM_FLHdlCtrl_Req "


左前把手控制指令


";
CM_ SG_ 816 HDBM_RLHdlCtrl_Req "


左后把手控制指令


";
CM_ SG_ 816 HDBM_FRHdlCtrl_Req "


右前把手控制指令


";
CM_ SG_ 816 HDBM_TpLtClrDes_Req "


顶灯目标色温指令


";
CM_ SG_ 816 HDBM_RRHdlCtrl_Req "



右后把手控制指令



";
CM_ SG_ 816 HDBM_RLPstnLgt_Req "


左后位置灯请求


";
CM_ SG_ 816 HDBM_RRPstnLgt_Req "


右后位置灯请求


";
CM_ SG_ 816 HDBM_RearFogBm_Req "
后雾灯请求



";
CM_ SG_ 816 HDBM_RRWdwCtl_Req "

右后车窗控制指令

";
CM_ SG_ 816 HDBM_RsLgt_Req "



倒车灯请求
Reverse Light Request



";
CM_ SG_ 816 HDBM_TrkLtCtrl_Req "
 后备箱灯控制指令
";
CM_ SG_ 816 HDBM_FRHdlLearn_Req "

右前把手学习请求

";
CM_ SG_ 816 HDBM_RRHdlLearn_Req "

右后把手学习请求

";
CM_ SG_ 816 HDBM_FLHdlLearn_Req "

左前把手学习请求

";
CM_ SG_ 816 HDBM_RLHdlLearn_Req "

左后把手学习请求

";
CM_ SG_ 816 HDBM_FLTpLtClrDes_Req "
左前顶灯色温指令
";
CM_ SG_ 816 HDBM_RLTpLtClrDes_Req "
左后顶灯色温指令
";
CM_ SG_ 816 HDBM_FRTpLtClrDes_Req "
右前顶灯色温指令
";
CM_ SG_ 816 HDBM_RRTpLtClrDes_Req "
右后顶灯色温指令
";
CM_ SG_ 816 HDBM_SteerTiltSpd_Req "

方向盘Tilt（上下）调节速度指令

";
CM_ SG_ 816 HDBM_SteerTeleSpd_Req "

方向盘Telescope（伸缩）调节速度指令

";
CM_ SG_ 816 HDBM_SteerLn_Req "

长行程管柱学习指令

";
CM_ SG_ 816 HDBM_ParkingSwitch_Req "


 Parking Switch Request
驻车开关请求


";
CM_ SG_ 816 HDBM_EHBMBrkModeSet_Req "




EHBM Brake Mode Set踏板感觉




";
CM_ SG_ 816 HDBM_TCSSw_Req "



TCS Switch
TCS开启关闭设置信号



";
CM_ SG_ 816 HDBM_AVHSw_Req "


AVH Switch
AVH开启关闭设置信号








";
CM_ SG_ 816 HDBM_HDCSw_Req "


HDC开启关闭设置信号






";
CM_ SG_ 816 HDBM_CSTSw_Req "


HDC Switch
HDC开启关闭设置信号








";
CM_ SG_ 816 HDBM_ESCSw_Req "

 ESC Switch
ESC开启关闭设置信号


";
CM_ SG_ 1489 HDBM_FragSwitchEn_Rsp "

Fragrance switch enable responce
香氛开关使能请求反馈

";
CM_ SG_ 1489 HDBM_FragCh1Sw_St "

Channel 1 Switch state
1通道切换状态

";
CM_ SG_ 1489 HDBM_FragCh2Sw_St "

Channel 2 Switch state
2通道切换状态

";
CM_ SG_ 1489 HDBM_FragCh3Sw_St "

Channel 3 Switch state
3通道切换状态

";
CM_ SG_ 1489 HDBM_FragConcLvl_Rsp "

Density response level
浓度响应等级

";
CM_ SG_ 1489 HDBM_AQSAirQuality_Val "
Environment air quality state
车外空气质量状态
";
CM_ SG_ 1489 HDBM_PM25Set_St "
PM2.5 switch state
PM2.5开关状态
";
CM_ SG_ 1489 HDBM_PM25Trigger_St "
PM2.5 Trigger Status
PM2.5通风净化触发状态
";
CM_ SG_ 1489 HDBM_FDeiceDefrost_Rsp "

Front deice and defrost response
前除霜除雾反馈

";
CM_ SG_ 1489 HDBM_AutoDefogSensDectect_St "

Auto Defog Sensor Dectect Status
空调传感器自动除雾条件检测结果

";
CM_ SG_ 1489 HDBM_AutoDefrostSet_St "
Auto defrost state
自动除雾状态
";
CM_ SG_ 1489 HDBM_AutoDefrostTrigger_St "
Auto Defrost Trigger Status
自动除雾触发状态
";
CM_ SG_ 1489 HDBM_IONSet_St "
ION state
离子发生器设置状态
";
CM_ SG_ 1489 HDBM_ACSwtich_St "
Air Conditioner Swtich State
A/C开关状态
";
CM_ SG_ 1489 HDBM_FACSwitch_Rsp "

Front AC switch response
前空调开关反馈

";
CM_ SG_ 1489 HDBM_FACAirFlowLevel_St "

Front AC air flow state
前空调风量状态

";
CM_ SG_ 1489 HDBM_FAcCoolOrHeatOrVent_St "




Front air conditioner refrigeration heating ventilation state
前空调制冷制热通风状态




";
CM_ SG_ 1489 HDBM_FLeftTempSet_St "

Front Left Set temperature state
前排左侧温度状态

";
CM_ SG_ 1489 HDBM_FRightTempSet_St "

Front Right Set temperature state
前排右侧设置温度状态

";
CM_ SG_ 1489 HDBM_FTempAreaSync_St "

Front Temperature area synchronization state response
前排温区同步状态反馈

";
CM_ SG_ 1489 HDBM_HvOnACM_Req "

High voltage on request
高压上电请求

";
CM_ SG_ 1489 HDBM_HVWork_Req "
AC system high voltage work request
空调系统高压工作请求
";
CM_ SG_ 1489 HDBM_RESSCoolFault_St "
Battery cooling fault state
电池制冷故障状态
";
CM_ SG_ 1489 HDBM_FACAirFlowLevelAuto_St "

Front AC Air Flow Level Auto State
前空调风量自动状态

";
CM_ SG_ 1489 HDBM_FACAirFlowModeAuto_St "

Front AC Air Flow Mode Auto State
前空调出风模式自动状态

";
CM_ SG_ 1489 HDBM_FACCoolOrHeatOrVentAuto_St "

Front Ac Cool Or Heat Or Vent Auto State
前空调制冷制热通风自动状态

";
CM_ SG_ 1489 HDBM_TDrDegDes_Req "




尾门目标角度指令




";
CM_ SG_ 1489 HDBM_TDrDegSet_Rsp "


尾门开启角度设置反馈


";
CM_ SG_ 1489 HDBM_LDRLgt_Req "


左侧日行灯请求


";
CM_ SG_ 1489 HDBM_RDRLgt_Req "


右侧日行灯请求


";
CM_ SG_ 1489 HDBM_FLDrPdlLtCtrl_Req "

左前门踏板灯控制指令

";
CM_ SG_ 1489 HDBM_FRDrPdlLtCtrl_Req "

右前门踏板灯控制指令

";
CM_ SG_ 1489 HDBM_RLDrPdlLtCtrl_Req "

左后门踏板灯控制指令

";
CM_ SG_ 1489 HDBM_RRDrPdlLtCtrl_Req "

右后门踏板灯控制指令

";
CM_ SG_ 1489 HDBM_FLDrCtrl_Req "

左前门控制指令

";
CM_ SG_ 1489 HDBM_FRDrCtrl_Req "

右前门控制指令

";
CM_ SG_ 1489 HDBM_RLDrCtrl_Req "

左后门控制指令

";
CM_ SG_ 1489 HDBM_RRDrCtrl_Req "

右后门控制指令

";
CM_ SG_ 1489 HDBM_FLDrLthCinch_Req "

左前门锁吸合指令

";
CM_ SG_ 1489 HDBM_TDrSpdDes_Req "






尾门目标速度指令






";
CM_ SG_ 1489 HDBM_TDrCtrl_Req "




尾门控制指令




";
CM_ SG_ 1489 HDBM_TDrLthCinch_Req "

 尾门锁吸合指令

";
CM_ SG_ 1489 HDBM_RLDrLthCinch_Req "


左后门锁吸合指令


";
CM_ SG_ 1489 HDBM_FRDrLthCinch_Req "

右前门锁吸合指令

";
CM_ SG_ 1489 HDBM_RRDrLthCinch_Req "

右后门锁吸合指令

";
CM_ SG_ 1489 HDBM_RLDrLthRls_Req "

左后门锁释放指令

";
CM_ SG_ 1489 HDBM_FRDrLthRls_Req "


右前门锁释放指令


";
CM_ SG_ 1489 HDBM_RRDrLthRls_Req "

右后门锁释放指令

";
CM_ SG_ 1489 HDBM_FLDrLthRls_Req "

左前门锁释放指令

";
CM_ SG_ 1489 HDBM_RESSCoolPwrLim_St "

AC system active limited battery cooling power flag
空调系统主动限制电池冷却功率标识

";
CM_ SG_ 1489 HDBM_RESSHeatFault_St "

Battery heating fault state
电池加热故障状态

";
CM_ SG_ 1489 HDBM_ACMWork_St "

HDBM ACM 应用软件运行状态

";
CM_ SG_ 1489 HDBM_HeatRecycle_Req "

Waste heat recovery _Req
余热回收请求

";
CM_ SG_ 1489 HDBM_DeiceDefog_Req "

HDBM除霜除雾请求

";
CM_ SG_ 1489 HDBM_HeatRecycleDisable_St "

余热回收禁止标识

";
CM_ SG_ 1489 HDBM_ChrgCapCtrl_Req "

充电口盖控制命令

";
CM_ SG_ 1489 HDBM_TDrLthRls_Req "


 尾门锁释放指令


";
CM_ SG_ 1489 HDBM_RRDrLthCinchFbd_Req "
右后门锁吸合禁止指令
";
CM_ SG_ 1489 HDBM_FLDrLthCinchFbd_Req "
左前门锁吸合禁止指令
";
CM_ SG_ 1489 HDBM_RLDrLthCinchFbd_Req "
左后门锁吸合禁止指令
";
CM_ SG_ 1489 HDBM_FRDrLthCinchFbd_Req "
右前门锁吸合禁止指令
";
CM_ SG_ 1489 HDBM_ChrgCapLearn_Req "

充电口盖学习请求

";
CM_ SG_ 1489 HDBM_IONSwitch_Req " 离子发生器开关请求";
CM_ SG_ 1489 HDBM_InPm25SnsrActn_Req " PM2.5开关请求 ";
CM_ SG_ 1489 HDBM_TDrLthCinchFbd_Req "


后尾门锁吸合禁止指令


";
CM_ SG_ 1500 HDBM_VB1_NetworkReqCondition0 " Wakeup or Request or Keep Network Condition0 唤醒或请求或保持网络条件1 ";
CM_ SG_ 1500 HDBM_VB1_NetworkReqCondition1 " Wakeup or Request or Keep Network Condition1 唤醒或请求或保持网络条件1 ";
CM_ SG_ 1500 HDBM_VB1_NetworkReqCondition2 " Wakeup or Request or Keep Network Condition2 唤醒或请求或保持网络条件2 ";
CM_ SG_ 1500 HDBM_VB1_NetworkReqCondition3 " Wakeup or Request or Keep Network Condition3 唤醒或请求或保持网络条件3 ";
CM_ SG_ 1500 HDBM_VB1_NetworkReqCondition4 " Wakeup or Request or Keep Network Condition4 唤醒或请求或保持网络条件4 ";
CM_ SG_ 1500 HDBM_VB1_NetworkReqCondition5 " Wakeup or Request or Keep Network Condition5 唤醒或请求或保持网络条件5 ";
CM_ SG_ 1500 HDBM_VB1_NetworkReqCondition6 " Wakeup or Request or Keep Network Condition6 唤醒或请求或保持网络条件6 ";
CM_ SG_ 1500 HDBM_VB1_NetworkReqCondition7 " Wakeup or Request or Keep Network Condition7 唤醒或请求或保持网络条件7 ";
CM_ SG_ 1500 HDBM_VB1_NetworkReqCondition8 " Wakeup or Request or Keep Network Condition8 唤醒或请求或保持网络条件8 ";
CM_ SG_ 1500 HDBM_VB1_NetworkReqCondition9 " Wakeup or Request or Keep Network Condition9 唤醒或请求或保持网络条件9 ";
CM_ SG_ 1500 HDBM_VB1_NetworkReqCondition10 " Wakeup or Request or Keep Network Condition10 唤醒或请求或保持网络条件10 ";
CM_ SG_ 1500 HDBM_VB1_NetworkReqCondition11 " Wakeup or Request or Keep Network Condition11 唤醒或请求或保持网络条件11 ";
CM_ SG_ 1500 HDBM_VB1_NetworkReqCondition12 " Wakeup or Request or Keep Network Condition12 唤醒或请求或保持网络条件12 ";
CM_ SG_ 1500 HDBM_VB1_NetworkReqCondition13 " Wakeup or Request or Keep Network Condition13 唤醒或请求或保持网络条件13 ";
CM_ SG_ 1500 HDBM_VB1_NetworkReqCondition14 " Wakeup or Request or Keep Network Condition14 唤醒或请求或保持网络条件14 ";
CM_ SG_ 1500 HDBM_VB1_NetworkReqCondition15 " Wakeup or Request or Keep Network Condition15 唤醒或请求或保持网络条件15 ";
CM_ SG_ 1500 HDBM_VB1_NetworkReqCondition16 " Wakeup or Request or Keep Network Condition16 唤醒或请求或保持网络条件16 ";
CM_ SG_ 1500 HDBM_VB1_NetworkReqCondition17 " Wakeup or Request or Keep Network Condition17 唤醒或请求或保持网络条件17 ";
CM_ SG_ 1500 HDBM_VB1_NetworkReqCondition18 " Wakeup or Request or Keep Network Condition18 唤醒或请求或保持网络条件18 ";
CM_ SG_ 1500 HDBM_VB1_NetworkReqCondition19 " Wakeup or Request or Keep Network Condition19 唤醒或请求或保持网络条件19 ";
CM_ SG_ 1500 HDBM_VB1_NetworkReqCondition20 " Wakeup or Request or Keep Network Condition20 唤醒或请求或保持网络条件20 ";
CM_ SG_ 1500 HDBM_VB1_NetworkReqCondition21 " Wakeup or Request or Keep Network Condition20 唤醒或请求或保持网络条件21 ";
CM_ SG_ 1500 HDBM_VB1_NetworkReqCondition22 " Wakeup or Request or Keep Network Condition20 唤醒或请求或保持网络条件22 ";
CM_ SG_ 1500 HDBM_VB1_NetworkReqCondition23 " Wakeup or Request or Keep Network Condition20 唤醒或请求或保持网络条件23 ";
CM_ SG_ 1500 HDBM_VB1_NetworkReqCondition24 " Wakeup or Request or Keep Network Condition20 唤醒或请求或保持网络条件24 ";
CM_ SG_ 1500 HDBM_VB1_NetworkReqCondition25 " Wakeup or Request or Keep Network Condition20 唤醒或请求或保持网络条件25 ";
CM_ SG_ 1500 HDBM_VB1_NetworkReqCondition26 " Wakeup or Request or Keep Network Condition20 唤醒或请求或保持网络条件26 ";
CM_ SG_ 1500 HDBM_VB1_NetworkReqCondition27 " Wakeup or Request or Keep Network Condition20 唤醒或请求或保持网络条件27 ";
CM_ SG_ 1500 HDBM_VB1_NetworkReqCondition28 " Wakeup or Request or Keep Network Condition20 唤醒或请求或保持网络条件28 ";
CM_ SG_ 1500 HDBM_VB1_NetworkReqCondition29 " Wakeup or Request or Keep Network Condition20 唤醒或请求或保持网络条件29 ";
CM_ SG_ 1500 HDBM_VB1_NetworkReqCondition30 " Wakeup or Request or Keep Network Condition20 唤醒或请求或保持网络条件30 ";
CM_ SG_ 1500 HDBM_VB1_NetworkReqCondition31 " Wakeup or Request or Keep Network Condition20 唤醒或请求或保持网络条件31 ";
CM_ SG_ 1409 HDBM_WakeupReq_HDBT "
Wakeup HDBT domain requirement flag
唤醒HDBT域需求标志
";
CM_ SG_ 1409 HDBM_WakeupReq_HDBI "
Wakeup HDBI domain requirement flag
唤醒HDBI域需求标志
";
CM_ SG_ 1409 HDBM_WakeupReq_HDBA "
Wakeup HDBA domain requirement flag
唤醒HDBA域需求标志
";
CM_ SG_ 1409 HDBM_WakeupReq_HDBM "
Wakeup HDBM domain requirement flag
唤醒HDBM域需求标志
";
CM_ SG_ 1409 HDBM_WakeupReq_ZCUF "
Wakeup ZCUF domain requirement flag
唤醒ZCUF域需求标志
";
CM_ SG_ 1409 HDBM_WakeupReq_ZCUL "
Wakeup ZCUL domain requirement flag
唤醒ZCUL域需求标志
";
CM_ SG_ 1409 HDBM_WakeupReq_ZCUR "
Wakeup ZCUR domain requirement flag
唤醒ZCUR域需求标志
";
CM_ SG_ 1409 HDBM_WakeupReq_ZCUT "
Wakeup ZCUT domain requirement flag
唤醒ZCUT域需求标志
";
CM_ SG_ 1025 HDBM_NodeAddress_VB1 "
Node source address
节点源地址
";
CM_ SG_ 1025 HDBM_RepeatMsgReq_VB1 "
Repeat Message Request Bit
重复报文请求位
";
CM_ SG_ 1025 HDBM_ActiveWakeup_VB1 "
Active Wakeup Bit
主动唤醒指示位
";
CM_ SG_ 1025 HDBM_PartialNetworkInfo_VB1 "
Partial Network Information Bit
部分网络管理信息指示位
";
CM_ SG_ 1025 HDBM_RepeatMsgSt_VB1 "
Repeat Message State indication
节点处在重复报文状态指示位
";
CM_ SG_ 1025 HDBM_PN_HDBT_VB1 "
Wakeup Target ECU requirement flag
唤醒目标ECU需求标志
";
CM_ SG_ 1025 HDBM_PN_HDBI_VB1 "
Wakeup Target ECU requirement flag
唤醒目标ECU需求标志
";
CM_ SG_ 1025 HDBM_PN_HDBA_VB1 "
Wakeup Target ECU requirement flag
唤醒目标ECU需求标志
";
CM_ SG_ 1025 HDBM_PN_HDBM_VB1 "
Wakeup Target ECU requirement flag
唤醒目标ECU需求标志
";
CM_ SG_ 1025 HDBM_PN_ZCUF_VB1 "
Wakeup Target ECU requirement flag
唤醒目标ECU需求标志
";
CM_ SG_ 1025 HDBM_PN_ZCUL_VB1 "
Wakeup Target ECU requirement flag
唤醒目标ECU需求标志
";
CM_ SG_ 1025 HDBM_PN_ZCUR_VB1 "
Wakeup Target ECU requirement flag
唤醒目标ECU需求标志
";
CM_ SG_ 1025 HDBM_PN_ZCUT_VB1 "
Wakeup Target ECU requirement flag
唤醒目标ECU需求标志
";
CM_ SG_ 690 HDBM_BrkLgt_Req "
制动灯请求
";
CM_ SG_ 690 HDBM_Horn_Req "
喇叭指令
";
CM_ SG_ 690 HDBM_HHChrgPileRecognize_St "
专属交流充电枪识别状态
";
CM_ SG_ 690 HDBM_AGSEn_Req "

AGS open _Req
AGS开启请求

";
CM_ SG_ 690 HDBM_AGSPosition_Req "
AGS open position _Req
AGS开启的位置请求
";
CM_ SG_ 690 HDBM_ECFEn_Req "

ECF open _Req
风扇开启请求

";
CM_ SG_ 690 HDBM_ECFSpdPercent_Req "

ECF open speed _Req 
风扇开启的转速请求

";
CM_ SG_ 690 HDBM_FHVACLeftMixPos_Req "

前左冷暖风门位置请求

";
CM_ SG_ 690 HDBM_FHVACRigtMixPos_Req "

前右冷暖风门位置请求

";
CM_ SG_ 690 HDBM_FHVACModePos_Req "

前出风模式风门位置请求

";
CM_ SG_ 690 HDBM_FHVACCyclePos_Req "

前内外循环风门位置请求

";
CM_ SG_ 690 HDBM_FHVACBypassPos_Req "



前Bypass模式风门位置请求



";
CM_ SG_ 690 HDBM_FHVACDefrostPos_Req "

前除雾风门位置请求

";
CM_ SG_ 690 HDBM_FHVACBLWPWM_Req "
前鼓风机控制转速占空比请求

";
CM_ SG_ 690 HDBM_FHVACBLWRelay_Req "

前鼓风机继电器开关请求

";
CM_ SG_ 690 HDBM_OTAMode_St "

整车OTA升级模式

";
CM_ SG_ 422 HDBM_FRSeatMsgStrth_Req "

副驾座椅按摩力度指令

";
CM_ SG_ 422 HDBM_SRLSeatHt_Req "

二排左座椅加热指令

";
CM_ SG_ 422 HDBM_SRLSeatVtlt_Req "

二排左座椅通风指令

";
CM_ SG_ 422 HDBM_SRRSeatHt_Req "

二排右座椅加热指令

";
CM_ SG_ 422 HDBM_SRRSeatVtlt_Req "

二排右座椅通风指令

";
CM_ SG_ 422 HDBM_SteerHt_Req "

方向盘加热指令

";
CM_ SG_ 422 HDBM_ExMirHt_Req "

外后视镜加热指令

";
CM_ SG_ 422 HDBM_FLSeatHt_Req "

主驾座椅加热指令

";
CM_ SG_ 422 HDBM_FLSeatVtlt_Req "

主驾座椅通风指令

";
CM_ SG_ 422 HDBM_FLSeatMsg_Req "

主驾座椅按摩指令

";
CM_ SG_ 422 HDBM_FLSeatMsgMode_Req "

主驾座椅按摩模式指令

";
CM_ SG_ 422 HDBM_FLSeatMsgStrth_Req "

主驾座椅按摩力度指令

";
CM_ SG_ 422 HDBM_FRSeatHt_Req "

副驾座椅加热指令

";
CM_ SG_ 422 HDBM_FRSeatVtlt_Req "

副驾座椅通风指令

";
CM_ SG_ 422 HDBM_FRSeatMsg_Req "

副驾座椅按摩指令

";
CM_ SG_ 422 HDBM_FRSeatMsgMode_Req "

副驾座椅按摩模式指令

";
CM_ SG_ 423 HDBM_FLSeatHgtAdj_Req "


主驾座椅高低调节指令


";
CM_ SG_ 423 HDBM_FRLegAngCshnExtAdj_Req "


副驾座椅腿托角度/坐垫延伸调节指令


";
CM_ SG_ 423 HDBM_FLSeatFBAdjSpd_Req "

 主驾座椅前后调节速度指令

";
CM_ SG_ 423 HDBM_FLLegAngCshnExtAdj_Req "


主驾座椅腿托角度/坐垫延伸调节指令


";
CM_ SG_ 423 HDBM_FLSeatBackrestAdjSpd_Req "


主驾座椅靠背调节速度指令


";
CM_ SG_ 423 HDBM_FLSeatHgtAdjSpd_Req "


主驾座椅高低调节速度指令


";
CM_ SG_ 423 HDBM_FLSeatCshnAngAdjSpd_Req "


主驾座椅坐垫角度调节速度指令


";
CM_ SG_ 423 HDBM_FLLegAngCshnExtAdjSpd_Req "


主驾座椅腿托角度/坐垫延伸调节速度指令


";
CM_ SG_ 423 HDBM_FRSeatFBAdjSpd_Req "


副驾座椅前后调节速度指令


";
CM_ SG_ 423 HDBM_FRSeatBackrestAdjSpd_Req "


副驾座椅靠背调节速度指令


";
CM_ SG_ 423 HDBM_FRSeatHgtAdjSpd_Req "


副驾座椅高低调节速度指令


";
CM_ SG_ 423 HDBM_FRSeatCshnAngAdjSpd_Req "


副驾座椅坐垫角度调节速度指令


";
CM_ SG_ 423 HDBM_FRLegAngCshnExtAdjSpd_Req "


副驾座椅腿托角度/坐垫延伸调节速度指令


";
CM_ SG_ 423 HDBM_FLLumbSuppFBAdj_Req "
主驾座椅腰托前后调节指令
";
CM_ SG_ 423 HDBM_FLLumbSuppUDAdj_Req "
主驾座椅腰托上下调节指令
";
CM_ SG_ 423 HDBM_FRLumbSuppFBAdj_Req "
副驾座椅腰托前后调节指令
";
CM_ SG_ 423 HDBM_FRLumbSuppUDAdj_Req "
副驾座椅腰托上下调节指令
";
CM_ SG_ 423 HDBM_FLSeatCshnAngAdj_Req "




主驾座椅腿托/坐垫角度调节请求




";
CM_ SG_ 423 HDBM_FLSeatFBAdj_Req "




主驾座椅前后调节指令




";
CM_ SG_ 423 HDBM_FLSeatBackrestAdj_Req "



主驾座椅靠背调节指令



";
CM_ SG_ 423 HDBM_FRSeatHgtAdj_Req "



副驾座椅高低调节指令



";
CM_ SG_ 423 HDBM_FRSeatFBAdj_Req "




副驾座椅前后调节指令




";
CM_ SG_ 423 HDBM_FRSeatBackrestAdj_Req "



副驾座椅靠背调节指令



";
CM_ SG_ 423 HDBM_FRSeatCshnAngAdj_Req "




副驾座椅腿托/坐垫角度调节请求




";
CM_ SG_ 423 HDBM_RExMirUDAdj_Req "


右外后视镜上下调节指令


";
CM_ SG_ 423 HDBM_RExMirLRAdj_Req "


右外后视镜左右调节指令


";
CM_ SG_ 423 HDBM_LExMirUDAdj_Req "


左外后视镜上下调节指令


";
CM_ SG_ 423 HDBM_LExMirLRAdj_Req "


左外后视镜左右调节指令


";
CM_ SG_ 423 HDBM_LExMirCtrl_Req "




左外后视镜展开折叠指令




";
CM_ SG_ 423 HDBM_RExMirCtrl_Req "




右外后视镜展开折叠指令




";
CM_ SG_ 423 HDBM_LExMirCtrlSpd_Req "

左外后视镜展开折叠速度指令

";
CM_ SG_ 423 HDBM_RExMirCtrlSpd_Req "

右外后视镜展开折叠速度指令

";
CM_ SG_ 423 HDBM_RExMirLRAdjSpd_Req "


右外后视镜左右调节速度指令


";
CM_ SG_ 423 HDBM_LExMirUDAdjSpd_Req "

左外后视镜上下调节速度指令

";
CM_ SG_ 423 HDBM_LExMirLRAdjSpd_Req "

左外后视镜左右调节速度指令

";
CM_ SG_ 423 HDBM_RExMirUDAdjSpd_Req "


右外后视镜上下调节速度指令


";
CM_ SG_ 1490 HDBM_AbsoluteTimeSecond_Val "

AbsoluteTime_Second 绝对时间 - 秒

";
CM_ SG_ 1490 HDBM_AbsoluteTimeMinute_Val "


AbsoluteTime - Minute 绝对时间 - 分


";
CM_ SG_ 1490 HDBM_AbsoluteTimeHour_Val "

AbsoluteTime - Hour 绝对时间 - 时

";
CM_ SG_ 1490 HDBM_AbsoluteTimeDay_Val "


AbsoluteTime - Day 绝对时间 - 日


";
CM_ SG_ 1490 HDBM_AbsoluteTimeMonth_Val "


AbsoluteTime - Month 绝对时间 - 月


";
CM_ SG_ 1490 HDBM_AbsoluteTimeYear_Val "


AbsoluteTime - Year 绝对时间 - 年


";
CM_ SG_ 817 HDBM_FLBckupDoorCtrl_Req "


左前门备用控制指令


";
CM_ SG_ 817 HDBM_FRBckupDoorCtrl_Req "


右前门备用控制指令


";
CM_ SG_ 817 HDBM_RLBckupDoorCtrl_Req "


左后门备用控制指令


";
CM_ SG_ 817 HDBM_RRBckupDoorCtrl_Req "


右后门备用控制指令


";
CM_ SG_ 817 HDBM_Whitelistsync_Req "

白名单同步指令

";
CM_ SG_ 353 HDBM_PowertrainRestrict_Req "

 Powertrain Restrict 限制动力执行信号

";
CM_ SG_ 128 HDBM_AmLtTarget1_Req "
氛围灯目标指令1
";
CM_ SG_ 128 HDBM_AmLtTarget2_Req "
氛围灯目标指令2
";
CM_ SG_ 128 HDBM_AmLtTarget3_Req "
氛围灯目标指令3
";
CM_ SG_ 128 HDBM_AmLtBrt_Req "
氛围灯亮度指令
";
CM_ SG_ 128 HDBM_AmLtRedVal_Req "
氛围灯Red值指令
";
CM_ SG_ 128 HDBM_AmLtGreenVal_Req "
氛围灯Green值指令
";
CM_ SG_ 128 HDBM_AmLtBlueVal_Req "
氛围灯Blue值指令
";
CM_ SG_ 128 HDBM_AmLtSpd_Req "
氛围灯速度指令
";
CM_ SG_ 128 HDBM_AmLtHornClrMd_Req "
氛围灯喇叭颜色模式指令
";
CM_ SG_ 128 HDBM_AmLtHornWrkMd_Req "
氛围灯喇叭工作模式指令
";
CM_ SG_ 80 ZCUT_BatteryVolt_Val "
Battery voltage
电池内侧电压
";
CM_ SG_ 81 ZCUT_DCCharge_St "


DC charging state
直流充电状态


";
CM_ SG_ 81 ZCUT_ACCharge_St "


AC charging state
交流充电状态


";
CM_ SG_ 81 ZCUT_CellOverTemp_St "
Cell over temperature
温度过高
";
CM_ SG_ 81 ZCUT_RLBrkLgt_St "
左后制动灯状态

";
CM_ SG_ 81 ZCUT_HighBrkLgt_St "
 高位制动灯状态

";
CM_ SG_ 81 ZCUT_RRBrkLgt_St "
右后制动灯状态

";
CM_ SG_ 81 ZCUT_State_St "
BMS State
电池BMS状态
";
CM_ SG_ 81 ZCUT_FastChrgCnctor_St "
Fast charging connector state
快充接头插接状态
";
CM_ SG_ 81 ZCUT_Current_Val "
Battery current
电池电流
";
CM_ SG_ 81 ZCUT_SOCDisplay_Val "
Displayed SOC
电池显示SOC
";
CM_ SG_ 81 ZCUT_FaultLevel_Err "
System fault Level
电池系统故障等级
";
CM_ SG_ 208 ZCUT_RLTnLgt_St "


Rear Left Turn Light State 左后转向灯状态


";
CM_ SG_ 208 ZCUT_RRTnLgt_St "


Rear Right Turn Light State 右后转向灯状态


";
CM_ SG_ 208 ZCUT_ChrgCapSW_St "



充电口盖物理按键开关



";
CM_ SG_ 544 ZCUT_ChrgDischrgCnct_St "


充放电枪连接状态信号


";
CM_ SG_ 544 ZCUT_TrkLtWrk_St "

后备箱灯工作状态


";
CM_ SG_ 544 ZCUT_RLPstnLgt_St " Rear Left Position Light State 左后位置灯状态";
CM_ SG_ 544 ZCUT_RRPstnLgt_St " Rear Right Position Light State 右后位置光灯点亮状态";
CM_ SG_ 544 ZCUT_RLTnLgtErr_St " Rear Left Turn Light Error 左后转向灯故障状态 ";
CM_ SG_ 544 ZCUT_RRTnLgtErr_St " Rear Right Turn Light Error 右后转向灯故障状态";
CM_ SG_ 544 ZCUT_SRLSeatOcp_St "



二排左座椅占位状态



";
CM_ SG_ 544 ZCUT_SRRSeatOcp_St "



二排右座椅占位状态



";
CM_ SG_ 544 ZCUT_SRMSeatOcp_St "



二排中座椅占位状态



";
CM_ SG_ 544 ZCUT_TempModuMax_Val "
Battery module maxmun temperature 
电池最高温度
";
CM_ SG_ 544 ZCUT_TRLSeatOcp_St "


三排左座椅占位状态


";
CM_ SG_ 544 ZCUT_TRRSeatOcp_St "


三排右座椅占位状态


";
CM_ SG_ 544 ZCUT_TempModuMin_Val "
Battery module minimun temperature 
电池最低温度
";
CM_ SG_ 544 ZCUT_SOCReal_Val "
Real SOC
电池实际SOC
";
CM_ SG_ 544 ZCUT_Checksum4 "


E2E Signal Group Checksum
Checksum is the actual value after calculation. 
E2E信号组校验和
Checksum为计算后实际值


";
CM_ SG_ 544 ZCUT_RollingCounter4 "



E2E Signal Group Counter
Counter value is automatically accumulated, added from 0 to 14 and then looped to the initial value of 0. Every time a message is sent, counter adds 1.
E2E信号组计数器
Counter值为自动累加，从0加到14，然后循环至初始值0，每次报文发送，Counter加1



";
CM_ SG_ 544 ZCUT_RearMirLtWrk_St "



后排化妆镜灯工作状态



";
CM_ SG_ 544 ZCUT_RLRsLgt_St " Reversing Light State 左后倒车灯状态";
CM_ SG_ 544 ZCUT_RRRsLgt_St "
 右后倒车灯状态
";
CM_ SG_ 544 ZCUT_ChrgCutOffSOCSetVal_Rsp "

ZCUT充电截止SOC仲裁值

";
CM_ SG_ 544 ZCUT_HHchrgPileCnct_St "
 
专属桩连接状态

";
CM_ SG_ 544 ZCUT_TRLSeatBelt_St "

三排左座椅安全带状态

";
CM_ SG_ 544 ZCUT_TRRSeatBelt_St "

三排右座椅安全带状态

";
CM_ SG_ 544 ZCUT_SRLSeatBelt_St "

二排左座椅安全带状态

";
CM_ SG_ 544 ZCUT_SRMSeatBelt_St "

二排中座椅安全带状态

";
CM_ SG_ 544 ZCUT_SRRSeatBelt_St "

二排右座椅安全带状态

";
CM_ SG_ 544 ZCUT_DisplayCharge_St "

Charging Status for Display  显示端充电状态

";
CM_ SG_ 548 ZCUT_HSDLVPower_St "

 ZCUT二级配电HSD供电状态， 每个Bit位代表一个控制器电源状态 0;Power Off 1:Power On

";
CM_ SG_ 548 ZCUT_PERMLVPower_St "

ZCUT二级配电eFuse常电供电状态

每个Bit位代表一个控制器电源状态 0;Power Off 1:Power On
";
CM_ SG_ 548 ZCUT_HSDLVPower_Err "



ZCUT二级配电HSD供电故障
每个Bit位代表一个控制器电源故障状态 0:No Fault 1:Fault

";
CM_ SG_ 548 ZCUT_PERMLVPower_Err "


ZCUT二级配电eFuse常电供电故障
每个Bit位代表一个控制器电源故障状态 0:No Fault 1:Fault

";
CM_ SG_ 929 ZCUT_TempModuMaxID_Dat "
Battery module maxmun temperature ID
电池最高温度编号
";
CM_ SG_ 929 ZCUT_TempModuMinID_Dat "
Battery module minimun temperature ID
电池最低温度编号
";
CM_ SG_ 929 ZCUT_OverCharge_St "
Battery overcharge
电池过充
";
CM_ SG_ 929 ZCUT_TempProbeNum_Val "
Battery cell temperature probe total number
动力蓄电池温度探针总数
";
CM_ SG_ 929 ZCUT_VoltCellMaxID_Dat "
Battery maximum cell voltage ID
电池最高单体电压编号
";
CM_ SG_ 929 ZCUT_SubTempHighID_Dat "
maximum temperature subsystem ID
最高温度子系统号
";
CM_ SG_ 929 ZCUT_VoltCellMax_Val "
Battery maximum cell voltage value
电池最高单体电压
";
CM_ SG_ 929 ZCUT_SubTempLowID_Dat "
Minimum temperature subsystem ID
最低温度子系统号
";
CM_ SG_ 929 ZCUT_VoltCellMinID_Dat "
Battery minimum cell voltage ID
电池最低单体电压编号
";
CM_ SG_ 929 ZCUT_SubRESSNum_Val "
Number of rechargeable energy storage subsystems
可充电储能子系统个数
";
CM_ SG_ 929 ZCUT_VoltCellMin_Val "
Battery minimum cell voltage value
电池最低单体电压
";
CM_ SG_ 929 ZCUT_SubRESSID_Dat "
ID of rechargeable energy storage subsystems
可充电储能子系统号
";
CM_ SG_ 929 ZCUT_SOE_Val "

SOC available energy
电池可用能量（SOE）

";
CM_ SG_ 929 ZCUT_CellUnderVolt_St "

Cell under voltage
单体欠压

";
CM_ SG_ 929 ZCUT_PackOverVolt_St "

Vehicle energy storage device over voltage warn
车载储能装置类型过压报警

";
CM_ SG_ 929 ZCUT_PackUnderVolt_St "

Vehicle energy storage device under voltage warn
车载储能装置类型欠压报警

";
CM_ SG_ 929 ZCUT_CellOverVolt_St "

Cell over voltage
单体过压

";
CM_ SG_ 929 ZCUT_SOCLow_St "

SOC low warn
SOC过低报警

";
CM_ SG_ 929 ZCUT_SOCHigh_St "

SOC high warn
SOC过高报警

";
CM_ SG_ 929 ZCUT_SOCSkip_St "

SOC skip
SOC跳变

";
CM_ SG_ 929 ZCUT_Mismatch_St "

Battery package mismatch warn
动力蓄电池包不匹配报警

";
CM_ SG_ 929 ZCUT_CellVoltDeviation_St "

Cell voltage consistency difference is too large
单体电压一致性差异过大

";
CM_ SG_ 929 ZCUT_CellTempDeviation_St "

Cell temperature consistency difference is too large
单体温差一致性差异过大

";
CM_ SG_ 929 ZCUT_BatVolHighID_Dat "

maximum voltage battery subsystem ID
最高电压电池子系统号

";
CM_ SG_ 929 ZCUT_BatVolLowID_Dat "

Minimum voltage battery subsystem ID
最低电压电池子系统号

";
CM_ SG_ 82 PCU_DCDCMode_St "

DCDC工作模式

";
CM_ SG_ 209 PCU_OBCACChrgCnctor_St "
AC charger connection state
交流充电枪连接状态
";
CM_ SG_ 402 CCM_ChrgCapPst_St "

充电口盖位置反馈




";
CM_ SG_ 402 CCM_ChrgCapMv_St "

充电口运动状态反馈


";
CM_ SG_ 402 ZCUT_FD_RT_1_CCMAvailable_St "
If signals which route from CCM in message ZCUT_FD_RT_1 are available
报文ZCUT_FD_RT_1中路由的CCM节点的信号是否可信



";
CM_ SG_ 402 CCM_ChrgCapLearn_St "

充电口盖学习状态反馈

";
CM_ SG_ 402 CCM_ChrgCapStpRsn_St "

充电口盖停止原因

";
CM_ SG_ 402 CCM_ChrgCapStp_Req "

充电口盖停止请求

";
CM_ SG_ 1105 ZCUT_NodeAddress_VB1 "

Node source address
节点源地址

";
CM_ SG_ 1105 ZCUT_RepeatMsgReq_VB1 "

Repeat Message Request Bit
重复报文请求位

";
CM_ SG_ 1105 ZCUT_ActiveWakeup_VB1 "

Active Wakeup Bit
主动唤醒指示位

";
CM_ SG_ 1105 ZCUT_PartialNetworkInfo_VB1 "

Partial Network Information Bit
部分网络管理信息指示位

";
CM_ SG_ 1105 ZCUT_RepeatMsgSt_VB1 "

Repeat Message State indication
节点处在重复报文状态指示位

";
CM_ SG_ 1105 ZCUT_PN_HDBT_VB1 "

Wakeup Target ECU requirement flag
唤醒目标ECU需求标志

";
CM_ SG_ 1105 ZCUT_PN_HDBI_VB1 "

Wakeup Target ECU requirement flag
唤醒目标ECU需求标志

";
CM_ SG_ 1105 ZCUT_PN_HDBA_VB1 "

Wakeup Target ECU requirement flag
唤醒目标ECU需求标志

";
CM_ SG_ 1105 ZCUT_PN_HDBM_VB1 "

Wakeup Target ECU requirement flag
唤醒目标ECU需求标志

";
CM_ SG_ 1105 ZCUT_PN_ZCUF_VB1 "

Wakeup Target ECU requirement flag
唤醒目标ECU需求标志

";
CM_ SG_ 1105 ZCUT_PN_ZCUL_VB1 "

Wakeup Target ECU requirement flag
唤醒目标ECU需求标志

";
CM_ SG_ 1105 ZCUT_PN_ZCUR_VB1 "

Wakeup Target ECU requirement flag
唤醒目标ECU需求标志

";
CM_ SG_ 1105 ZCUT_PN_ZCUT_VB1 "

Wakeup Target ECU requirement flag
唤醒目标ECU需求标志

";
CM_ SG_ 1413 ZCUT_WakeupReq_HDBT " Wakeup HDBT domain-related ECU flag bits, each bit represents an ECU, the correspondence between bit and ECU refers to Sleep Wakeup List 唤醒HDBT域相关ECU标志位，每一bit位代表一个ECU，具体bit与ECU的对应关系见休眠唤醒列表。 ";
CM_ SG_ 1413 ZCUT_WakeupReq_HDBI " Wakeup HDBI domain-related ECU flag bits, each bit represents an ECU, the correspondence between bit and ECU refers to Sleep Wakeup List 唤醒HDBI域相关ECU标志位，每一bit位代表一个ECU，具体bit与ECU的对应关系见休眠唤醒列表。 ";
CM_ SG_ 1413 ZCUT_WakeupReq_HDBA " Wakeup HDBA domain-related ECU flag bits, each bit represents an ECU, the correspondence between bit and ECU refers to Sleep Wakeup List 唤醒HDBA域相关ECU标志位，每一bit位代表一个ECU，具体bit与ECU的对应关系见休眠唤醒列表。 ";
CM_ SG_ 1413 ZCUT_WakeupReq_HDBM " Wakeup HDBM domain-related ECU flag bits, each bit represents an ECU, the correspondence between bit and ECU refers to Sleep Wakeup List 唤醒HDBM域相关ECU标志位，每一bit位代表一个ECU，具体bit与ECU的对应关系见休眠唤醒列表。 ";
CM_ SG_ 1413 ZCUT_WakeupReq_ZCUF " Wakeup ZCUF domain-related ECU flag bits, each bit represents an ECU, the correspondence between bit and ECU refers to Sleep Wakeup List 唤醒ZCUF域相关ECU标志位，每一bit位代表一个ECU，具体bit与ECU的对应关系见休眠唤醒列表。 ";
CM_ SG_ 1413 ZCUT_WakeupReq_ZCUL " Wakeup ZCUL domain-related ECU flag bits, each bit represents an ECU, the correspondence between bit and ECU refers to Sleep Wakeup List 唤醒ZCUL域相关ECU标志位，每一bit位代表一个ECU，具体bit与ECU的对应关系见休眠唤醒列表。 ";
CM_ SG_ 1413 ZCUT_WakeupReq_ZCUR " Wakeup ZCUR domain-related ECU flag bits, each bit represents an ECU, the correspondence between bit and ECU refers to Sleep Wakeup List 唤醒ZCUR域相关ECU标志位，每一bit位代表一个ECU，具体bit与ECU的对应关系见休眠唤醒列表。 ";
CM_ SG_ 1413 ZCUT_WakeupReq_ZCUT " Wakeup ZCUT domain-related ECU flag bits, each bit represents an ECU, the correspondence between bit and ECU refers to Sleep Wakeup List 唤醒ZCUT域相关ECU标志位，每一bit位代表一个ECU，具体bit与ECU的对应关系见休眠唤醒列表。 ";
CM_ SG_ 1492 ZCUT_VB1_NetworkReqCondition0 "
Wakeup or Request or Keep Network Condition0
唤醒或请求或保持网络条件1
";
CM_ SG_ 1492 ZCUT_VB1_NetworkReqCondition1 "
Wakeup or Request or Keep Network Condition1
唤醒或请求或保持网络条件1
";
CM_ SG_ 1492 ZCUT_VB1_NetworkReqCondition2 "
Wakeup or Request or Keep Network Condition2
唤醒或请求或保持网络条件2
";
CM_ SG_ 1492 ZCUT_VB1_NetworkReqCondition3 "
Wakeup or Request or Keep Network Condition3
唤醒或请求或保持网络条件3
";
CM_ SG_ 1492 ZCUT_VB1_NetworkReqCondition4 "
Wakeup or Request or Keep Network Condition4
唤醒或请求或保持网络条件4
";
CM_ SG_ 1492 ZCUT_VB1_NetworkReqCondition5 "
Wakeup or Request or Keep Network Condition5
唤醒或请求或保持网络条件5
";
CM_ SG_ 1492 ZCUT_VB1_NetworkReqCondition6 "
Wakeup or Request or Keep Network Condition6
唤醒或请求或保持网络条件6
";
CM_ SG_ 1492 ZCUT_VB1_NetworkReqCondition7 "
Wakeup or Request or Keep Network Condition7
唤醒或请求或保持网络条件7
";
CM_ SG_ 1492 ZCUT_VB1_NetworkReqCondition8 "
Wakeup or Request or Keep Network Condition8
唤醒或请求或保持网络条件8
";
CM_ SG_ 1492 ZCUT_VB1_NetworkReqCondition9 "
Wakeup or Request or Keep Network Condition9
唤醒或请求或保持网络条件9
";
CM_ SG_ 1492 ZCUT_VB1_NetworkReqCondition10 "
Wakeup or Request or Keep Network Condition10
唤醒或请求或保持网络条件10
";
CM_ SG_ 1492 ZCUT_VB1_NetworkReqCondition11 "
Wakeup or Request or Keep Network Condition11
唤醒或请求或保持网络条件11
";
CM_ SG_ 1492 ZCUT_VB1_NetworkReqCondition12 "
Wakeup or Request or Keep Network Condition12
唤醒或请求或保持网络条件12
";
CM_ SG_ 1492 ZCUT_VB1_NetworkReqCondition13 "
Wakeup or Request or Keep Network Condition13
唤醒或请求或保持网络条件13
";
CM_ SG_ 1492 ZCUT_VB1_NetworkReqCondition14 "
Wakeup or Request or Keep Network Condition14
唤醒或请求或保持网络条件14
";
CM_ SG_ 1492 ZCUT_VB1_NetworkReqCondition15 "
Wakeup or Request or Keep Network Condition15
唤醒或请求或保持网络条件15
";
CM_ SG_ 1492 ZCUT_VB1_NetworkReqCondition16 "
Wakeup or Request or Keep Network Condition16
唤醒或请求或保持网络条件16
";
CM_ SG_ 1492 ZCUT_VB1_NetworkReqCondition17 "
Wakeup or Request or Keep Network Condition17
唤醒或请求或保持网络条件17
";
CM_ SG_ 1492 ZCUT_VB1_NetworkReqCondition18 "
Wakeup or Request or Keep Network Condition18
唤醒或请求或保持网络条件18
";
CM_ SG_ 1492 ZCUT_VB1_NetworkReqCondition19 "
Wakeup or Request or Keep Network Condition19
唤醒或请求或保持网络条件19
";
CM_ SG_ 1492 ZCUT_VB1_NetworkReqCondition20 "
Wakeup or Request or Keep Network Condition20
唤醒或请求或保持网络条件20
";
CM_ SG_ 1492 ZCUT_VB1_NetworkReqCondition21 "
Wakeup or Request or Keep Network Condition20
唤醒或请求或保持网络条件21
";
CM_ SG_ 1492 ZCUT_VB1_NetworkReqCondition22 "
Wakeup or Request or Keep Network Condition20
唤醒或请求或保持网络条件22
";
CM_ SG_ 1492 ZCUT_VB1_NetworkReqCondition23 "
Wakeup or Request or Keep Network Condition20
唤醒或请求或保持网络条件23
";
CM_ SG_ 1492 ZCUT_VB1_NetworkReqCondition24 "
Wakeup or Request or Keep Network Condition20
唤醒或请求或保持网络条件24
";
CM_ SG_ 1492 ZCUT_VB1_NetworkReqCondition25 "
Wakeup or Request or Keep Network Condition20
唤醒或请求或保持网络条件25
";
CM_ SG_ 1492 ZCUT_VB1_NetworkReqCondition26 "
Wakeup or Request or Keep Network Condition20
唤醒或请求或保持网络条件26
";
CM_ SG_ 1492 ZCUT_VB1_NetworkReqCondition27 "
Wakeup or Request or Keep Network Condition20
唤醒或请求或保持网络条件27
";
CM_ SG_ 1492 ZCUT_VB1_NetworkReqCondition28 "
Wakeup or Request or Keep Network Condition20
唤醒或请求或保持网络条件28
";
CM_ SG_ 1492 ZCUT_VB1_NetworkReqCondition29 "
Wakeup or Request or Keep Network Condition20
唤醒或请求或保持网络条件29
";
CM_ SG_ 1492 ZCUT_VB1_NetworkReqCondition30 "
Wakeup or Request or Keep Network Condition20
唤醒或请求或保持网络条件30
";
CM_ SG_ 1492 ZCUT_VB1_NetworkReqCondition31 "
Wakeup or Request or Keep Network Condition20
唤醒或请求或保持网络条件31
";
CM_ SG_ 546 PCU_OBCACSocketLock_St "
AC charging stand electronic lock state
交流充电座电子锁状态
";
CM_ SG_ 1328 PLGM_TLthNeutral_St "

尾门锁Neutral状态

";
CM_ SG_ 1328 PLGM_TLthHlfLck_St "

尾门锁halflock状态

";
CM_ SG_ 1328 PLGM_TLthAjar_St "

尾门锁Ajar状态

";
CM_ SG_ 1328 PLGM_TDrWrk_St "
 尾门工作状态
";
CM_ SG_ 1328 PLGM_TDrTripPst_Val "

尾门开度值

";
CM_ SG_ 1328 PLGM_TDrTchpadSW_St "
尾门touchpad按键状态


";
CM_ SG_ 1328 PLGM_TDrStpRsn_St "

 尾门停止原因

";
CM_ SG_ 1328 PLGM_TDrLthWrk_St "
尾门锁工作状态
";
CM_ SG_ 1328 PLGM_TDrLth_St "
尾门锁状态
";
CM_ SG_ 1328 PLGM_TDrLth_Err "
尾门锁故障信号
";
CM_ SG_ 1328 PLGM_TDrIntSW_St "

尾门内饰板按键状态

";
CM_ SG_ 1328 PLGM_SpdlStallEvt_St "
尾门堵转事件状态
";
CM_ SG_ 1328 PLGM_PinchEvt_St "
尾门防夹事件状态
";
CM_ SG_ 1328 PLGM_Followup_Req "

尾门随动请求

";
CM_ SG_ 1328 PLGM_TDrLSpdl_Err "

尾门左撑杆故障信号

";
CM_ SG_ 1328 PLGM_TDrRSpdl_Err "

尾门右撑杆故障信号

";
CM_ SG_ 1328 PLGM_InitLearn_St "

尾门初始化学习状态

";
CM_ SG_ 1328 PLGM_MaxPstLn_St "

尾门最大位置学习状态

";
CM_ SG_ 897 ZCUT_ChargeHVPower_Val "


Charging HVPower 充电功率


";
CM_ SG_ 897 ZCUT_RemainChrgTime_Val "


Remain charging time
剩余充电时间


";
CM_ SG_ 897 ZCUT_SRRSeatVtlt_Rsp "

二排右座椅通风状态反馈

";
CM_ SG_ 897 ZCUT_SRRSeatVtltStpRsn_St "

二排右座椅通风停止原因

";
CM_ SG_ 897 ZCUT_SRLSeatHt_Rsp "

二排左座椅加热状态反馈

";
CM_ SG_ 897 ZCUT_SRLSeatHtStpRsn_St "

二排左座椅加热停止原因

";
CM_ SG_ 897 ZCUT_SRLSeatVtlt_Rsp "

二排左座椅通风状态反馈

";
CM_ SG_ 897 ZCUT_SRLSeatVtltStpRsn_St "

二排左座椅通风停止原因

";
CM_ SG_ 897 ZCUT_SRRSeatHt_Rsp "

二排右座椅加热状态反馈

";
CM_ SG_ 897 ZCUT_SRRSeatHtStpRsn_St "

二排右座椅加热停止原因

";
CM_ SG_ 1454 ZCUT_BattSerialNum_Dat "

Battery serial number
电池流水号

";
CM_ SG_ 1454 ZCUT_BattManuYear_Val "

Battery manufacture year
电池生产年

";
CM_ SG_ 1454 ZCUT_BattManuMonth_Val "

Battery manufacture month
电池生产月

";
CM_ SG_ 1454 ZCUT_BattManuDay_Val "

Battery manufacture day
电池生产日

";
CM_ SG_ 1454 ZCUT_PackageTotalNum_Val "

Battery package total number
电池包总数

";
CM_ SG_ 1454 ZCUT_CellTotalNum_Val "

Battery cell total number
动力蓄电池总数

";
CM_ SG_ 256 ZCUR_FRHdlOprt_St "
右前把手操作状态


";
CM_ SG_ 256 ZCUR_RRHdlOprt_St "
右后把手操作状态


";
CM_ SG_ 256 ZCUR_FRDrIntSW_St "
右前门内部按键状态


";
CM_ SG_ 256 ZCUR_RRDrIntSW_St "
右后门内部按键状态


";
CM_ SG_ 256 ZCUR_SFRTnLt_St "
Side Right Turn Light Error State 右侧后视镜转向灯状态



";
CM_ SG_ 256 ZCUR_Checksum1 "

E2E Signal Group Checksum
Checksum is the actual value after calculation. 
E2E信号组校验和
Checksum为计算后实际值

";
CM_ SG_ 256 ZCUR_RollingCounter1 "


E2E Signal Group Counter
Counter value is automatically accumulated, added from 0 to 14 and then looped to the initial value of 0. Every time a message is sent, counter adds 1.
E2E信号组计数器
Counter值为自动累加，从0加到14，然后循环至初始值0，每次报文发送，Counter加1


";
CM_ SG_ 256 ZCUR_FRSeatOcp_St "
Front Left Seat Occupied State 副驾座椅占位











";
CM_ SG_ 256 ZCUR_FRWinPst_Rsp "
右前车窗位置反馈




";
CM_ SG_ 256 ZCUR_RRWinPst_Rsp "
右后车窗位置反馈





";
BA_DEF_  "DBName" STRING ;
BA_DEF_  "BusType" STRING ;
BA_DEF_ BU_  "NodeLayerModules" STRING ;
BA_DEF_ BU_  "NmAsrNode" ENUM  "No","Yes";
BA_DEF_ BO_  "MessageIdType" ENUM  "Normal","NM","DiagRequest","DiagResponse","DiagState";
BA_DEF_ BO_  "GenMsgSendType" ENUM  "Cyclic","NotUsed","NotUsed","NotUsed","NotUsed","NotUsed","NotUsed","NotUsed","NoMsgSendType","CA","CE","Event","IfActive";
BA_DEF_ BO_  "VFrameFormat" ENUM  "StandardCAN","ExtendedCAN","reserved","reserved","reserved","reserved","reserved","reserved","reserved","reserved","reserved","reserved","reserved","reserved","StandardCAN_FD","ExtendedCAN_FD";
BA_DEF_ BO_  "GenMsgCycleTime" INT 0 0;
BA_DEF_ BO_  "GenMsgCycleTimeFast" INT 0 0;
BA_DEF_ BO_  "CANFD_BRS" ENUM  "0","1";
BA_DEF_ BO_  "GenMsgNrOfRepetition" INT 0 0;
BA_DEF_ BO_  "GenMsgDelayTime" INT 0 0;
BA_DEF_ BO_  "GenMsgILSupport" ENUM  "No","Yes";
BA_DEF_ BO_  "GenMsgStartDelayTime" INT 0 0;
BA_DEF_ BO_  "NmAsrMessage" ENUM  "No","Yes";
BA_DEF_ SG_  "GenSigSendType" ENUM  "Cyclic","OnWrite","OnWriteWithRepetition","OnChange","OnChangeWithRepetition","NotUsed","NotUsed","NoSigSendType","IfActive","IfActiveWithRepetition","OnChangeAndIfActive","OnChangeAndIfActiveWithRepetition","CA","CE","Event";
BA_DEF_ SG_  "GenSigStartValue" INT 0 0;
BA_DEF_ SG_  "GenSigInactiveValue" INT 0 0;
BA_DEF_DEF_  "DBName" "";
BA_DEF_DEF_  "BusType" "";
BA_DEF_DEF_  "NodeLayerModules" "CANoeILNLVector.dll";
BA_DEF_DEF_  "NmAsrNode" "No";
BA_DEF_DEF_  "MessageIdType" "Normal";
BA_DEF_DEF_  "GenMsgSendType" "";
BA_DEF_DEF_  "VFrameFormat" "StandardCAN";
BA_DEF_DEF_  "GenMsgCycleTime" 0;
BA_DEF_DEF_  "GenMsgCycleTimeFast" 0;
BA_DEF_DEF_  "CANFD_BRS" "0";
BA_DEF_DEF_  "GenMsgNrOfRepetition" 0;
BA_DEF_DEF_  "GenMsgDelayTime" 0;
BA_DEF_DEF_  "GenMsgILSupport" "No";
BA_DEF_DEF_  "GenMsgStartDelayTime" 0;
BA_DEF_DEF_  "NmAsrMessage" "No";
BA_DEF_DEF_  "GenSigSendType" "";
BA_DEF_DEF_  "GenSigStartValue" 0;
BA_DEF_DEF_  "GenSigInactiveValue" 0;
BA_ "BusType" "CAN FD";
BA_ "DBName" "V_BackboneCANFD1";
BA_ "NmAsrNode" BU_ ZCUR 1;
BA_ "NmAsrNode" BU_ HDBI 1;
BA_ "NmAsrNode" BU_ HDBM 1;
BA_ "NmAsrNode" BU_ ZCUF 1;
BA_ "NmAsrNode" BU_ ZCUT 1;
BA_ "NmAsrNode" BU_ ZCUL 1;
BA_ "GenMsgDelayTime" BO_ 913 10;
BA_ "GenMsgNrOfRepetition" BO_ 913 3;
BA_ "GenMsgCycleTimeFast" BO_ 913 20;
BA_ "CANFD_BRS" BO_ 913 1;
BA_ "GenMsgCycleTime" BO_ 913 100;
BA_ "GenMsgSendType" BO_ 913 10;
BA_ "GenMsgILSupport" BO_ 913 1;
BA_ "VFrameFormat" BO_ 913 14;
BA_ "CANFD_BRS" BO_ 96 1;
BA_ "GenMsgCycleTime" BO_ 96 10;
BA_ "GenMsgSendType" BO_ 96 0;
BA_ "GenMsgILSupport" BO_ 96 1;
BA_ "VFrameFormat" BO_ 96 14;
BA_ "GenMsgDelayTime" BO_ 1441 20;
BA_ "GenMsgNrOfRepetition" BO_ 1441 3;
BA_ "GenMsgCycleTimeFast" BO_ 1441 100;
BA_ "CANFD_BRS" BO_ 1441 1;
BA_ "GenMsgCycleTime" BO_ 1441 1000;
BA_ "GenMsgSendType" BO_ 1441 10;
BA_ "GenMsgILSupport" BO_ 1441 1;
BA_ "VFrameFormat" BO_ 1441 14;
BA_ "GenMsgNrOfRepetition" BO_ 352 3;
BA_ "GenMsgCycleTimeFast" BO_ 352 50;
BA_ "CANFD_BRS" BO_ 352 1;
BA_ "GenMsgSendType" BO_ 352 11;
BA_ "GenMsgILSupport" BO_ 352 1;
BA_ "VFrameFormat" BO_ 352 14;
BA_ "CANFD_BRS" BO_ 272 1;
BA_ "GenMsgCycleTime" BO_ 272 20;
BA_ "GenMsgSendType" BO_ 272 0;
BA_ "GenMsgILSupport" BO_ 272 1;
BA_ "VFrameFormat" BO_ 272 14;
BA_ "CANFD_BRS" BO_ 689 1;
BA_ "GenMsgCycleTime" BO_ 689 100;
BA_ "GenMsgSendType" BO_ 689 0;
BA_ "GenMsgILSupport" BO_ 689 1;
BA_ "VFrameFormat" BO_ 689 14;
BA_ "CANFD_BRS" BO_ 1488 1;
BA_ "GenMsgCycleTime" BO_ 1488 500;
BA_ "GenMsgSendType" BO_ 1488 0;
BA_ "GenMsgILSupport" BO_ 1488 1;
BA_ "VFrameFormat" BO_ 1488 14;
BA_ "GenMsgNrOfRepetition" BO_ 421 3;
BA_ "GenMsgCycleTimeFast" BO_ 421 50;
BA_ "CANFD_BRS" BO_ 421 1;
BA_ "GenMsgCycleTime" BO_ 421 200;
BA_ "GenMsgSendType" BO_ 421 10;
BA_ "GenMsgILSupport" BO_ 421 1;
BA_ "VFrameFormat" BO_ 421 14;
BA_ "GenMsgNrOfRepetition" BO_ 816 3;
BA_ "GenMsgCycleTimeFast" BO_ 816 50;
BA_ "CANFD_BRS" BO_ 816 1;
BA_ "GenMsgCycleTime" BO_ 816 200;
BA_ "GenMsgSendType" BO_ 816 10;
BA_ "GenMsgILSupport" BO_ 816 1;
BA_ "VFrameFormat" BO_ 816 14;
BA_ "GenMsgNrOfRepetition" BO_ 1489 3;
BA_ "GenMsgCycleTimeFast" BO_ 1489 100;
BA_ "CANFD_BRS" BO_ 1489 1;
BA_ "GenMsgCycleTime" BO_ 1489 500;
BA_ "GenMsgSendType" BO_ 1489 10;
BA_ "GenMsgILSupport" BO_ 1489 1;
BA_ "VFrameFormat" BO_ 1489 14;
BA_ "CANFD_BRS" BO_ 210 1;
BA_ "GenMsgCycleTime" BO_ 210 20;
BA_ "GenMsgSendType" BO_ 210 8;
BA_ "CANFD_BRS" BO_ 1500 1;
BA_ "GenMsgCycleTime" BO_ 1500 1000;
BA_ "GenMsgSendType" BO_ 1500 0;
BA_ "GenMsgILSupport" BO_ 1500 1;
BA_ "VFrameFormat" BO_ 1500 14;
BA_ "GenMsgDelayTime" BO_ 1409 5;
BA_ "GenMsgNrOfRepetition" BO_ 1409 15;
BA_ "GenMsgCycleTimeFast" BO_ 1409 20;
BA_ "CANFD_BRS" BO_ 1409 1;
BA_ "GenMsgCycleTime" BO_ 1409 500;
BA_ "GenMsgSendType" BO_ 1409 10;
BA_ "GenMsgILSupport" BO_ 1409 1;
BA_ "VFrameFormat" BO_ 1409 14;
BA_ "GenMsgCycleTime" BO_ 1025 500;
BA_ "GenMsgSendType" BO_ 1025 0;
BA_ "NmAsrMessage" BO_ 1025 1;
BA_ "GenMsgILSupport" BO_ 1025 1;
BA_ "MessageIdType" BO_ 1025 1;
BA_ "GenMsgNrOfRepetition" BO_ 690 3;
BA_ "GenMsgCycleTimeFast" BO_ 690 10;
BA_ "CANFD_BRS" BO_ 690 1;
BA_ "GenMsgCycleTime" BO_ 690 100;
BA_ "GenMsgSendType" BO_ 690 10;
BA_ "GenMsgILSupport" BO_ 690 1;
BA_ "VFrameFormat" BO_ 690 14;
BA_ "GenMsgNrOfRepetition" BO_ 422 3;
BA_ "GenMsgCycleTimeFast" BO_ 422 50;
BA_ "CANFD_BRS" BO_ 422 1;
BA_ "GenMsgCycleTime" BO_ 422 200;
BA_ "GenMsgSendType" BO_ 422 10;
BA_ "GenMsgILSupport" BO_ 422 1;
BA_ "VFrameFormat" BO_ 422 14;
BA_ "GenMsgNrOfRepetition" BO_ 423 3;
BA_ "GenMsgCycleTimeFast" BO_ 423 50;
BA_ "CANFD_BRS" BO_ 423 1;
BA_ "GenMsgCycleTime" BO_ 423 200;
BA_ "GenMsgSendType" BO_ 423 10;
BA_ "GenMsgILSupport" BO_ 423 1;
BA_ "VFrameFormat" BO_ 423 14;
BA_ "CANFD_BRS" BO_ 1490 1;
BA_ "GenMsgCycleTime" BO_ 1490 500;
BA_ "GenMsgSendType" BO_ 1490 0;
BA_ "GenMsgILSupport" BO_ 1490 1;
BA_ "VFrameFormat" BO_ 1490 14;
BA_ "GenMsgNrOfRepetition" BO_ 817 3;
BA_ "GenMsgCycleTimeFast" BO_ 817 50;
BA_ "CANFD_BRS" BO_ 817 1;
BA_ "GenMsgSendType" BO_ 817 11;
BA_ "GenMsgILSupport" BO_ 817 1;
BA_ "VFrameFormat" BO_ 817 14;
BA_ "GenMsgNrOfRepetition" BO_ 353 3;
BA_ "GenMsgCycleTimeFast" BO_ 353 50;
BA_ "CANFD_BRS" BO_ 353 1;
BA_ "GenMsgCycleTime" BO_ 353 200;
BA_ "GenMsgSendType" BO_ 353 10;
BA_ "GenMsgILSupport" BO_ 353 1;
BA_ "VFrameFormat" BO_ 353 14;
BA_ "CANFD_BRS" BO_ 128 1;
BA_ "GenMsgCycleTime" BO_ 128 10;
BA_ "GenMsgSendType" BO_ 128 0;
BA_ "GenMsgILSupport" BO_ 128 1;
BA_ "VFrameFormat" BO_ 128 14;
BA_ "CANFD_BRS" BO_ 80 1;
BA_ "GenMsgCycleTime" BO_ 80 10;
BA_ "GenMsgSendType" BO_ 80 0;
BA_ "GenMsgILSupport" BO_ 80 1;
BA_ "VFrameFormat" BO_ 80 14;
BA_ "CANFD_BRS" BO_ 81 1;
BA_ "GenMsgCycleTime" BO_ 81 10;
BA_ "GenMsgSendType" BO_ 81 0;
BA_ "GenMsgILSupport" BO_ 81 1;
BA_ "VFrameFormat" BO_ 81 14;
BA_ "CANFD_BRS" BO_ 208 1;
BA_ "GenMsgCycleTime" BO_ 208 20;
BA_ "GenMsgSendType" BO_ 208 0;
BA_ "GenMsgILSupport" BO_ 208 1;
BA_ "VFrameFormat" BO_ 208 14;
BA_ "CANFD_BRS" BO_ 544 1;
BA_ "GenMsgCycleTime" BO_ 544 100;
BA_ "GenMsgSendType" BO_ 544 0;
BA_ "GenMsgILSupport" BO_ 544 1;
BA_ "VFrameFormat" BO_ 544 14;
BA_ "GenMsgDelayTime" BO_ 548 20;
BA_ "GenMsgNrOfRepetition" BO_ 548 3;
BA_ "GenMsgCycleTimeFast" BO_ 548 100;
BA_ "CANFD_BRS" BO_ 548 1;
BA_ "GenMsgCycleTime" BO_ 548 1000;
BA_ "GenMsgSendType" BO_ 548 10;
BA_ "GenMsgILSupport" BO_ 548 1;
BA_ "VFrameFormat" BO_ 548 14;
BA_ "CANFD_BRS" BO_ 929 1;
BA_ "GenMsgCycleTime" BO_ 929 200;
BA_ "GenMsgSendType" BO_ 929 0;
BA_ "GenMsgILSupport" BO_ 929 1;
BA_ "VFrameFormat" BO_ 929 14;
BA_ "CANFD_BRS" BO_ 82 1;
BA_ "GenMsgCycleTime" BO_ 82 10;
BA_ "GenMsgSendType" BO_ 82 0;
BA_ "GenMsgILSupport" BO_ 82 1;
BA_ "VFrameFormat" BO_ 82 14;
BA_ "CANFD_BRS" BO_ 209 1;
BA_ "GenMsgCycleTime" BO_ 209 20;
BA_ "GenMsgSendType" BO_ 209 0;
BA_ "GenMsgILSupport" BO_ 209 1;
BA_ "VFrameFormat" BO_ 209 14;
BA_ "CANFD_BRS" BO_ 402 1;
BA_ "GenMsgCycleTime" BO_ 402 50;
BA_ "GenMsgSendType" BO_ 402 0;
BA_ "GenMsgILSupport" BO_ 402 1;
BA_ "VFrameFormat" BO_ 402 14;
BA_ "GenMsgCycleTime" BO_ 1105 500;
BA_ "GenMsgSendType" BO_ 1105 0;
BA_ "NmAsrMessage" BO_ 1105 1;
BA_ "GenMsgILSupport" BO_ 1105 1;
BA_ "MessageIdType" BO_ 1105 1;
BA_ "GenMsgDelayTime" BO_ 1413 5;
BA_ "GenMsgNrOfRepetition" BO_ 1413 15;
BA_ "GenMsgCycleTimeFast" BO_ 1413 20;
BA_ "CANFD_BRS" BO_ 1413 1;
BA_ "GenMsgCycleTime" BO_ 1413 500;
BA_ "GenMsgSendType" BO_ 1413 10;
BA_ "GenMsgILSupport" BO_ 1413 1;
BA_ "VFrameFormat" BO_ 1413 14;
BA_ "CANFD_BRS" BO_ 1492 1;
BA_ "GenMsgCycleTime" BO_ 1492 1000;
BA_ "GenMsgSendType" BO_ 1492 0;
BA_ "GenMsgILSupport" BO_ 1492 1;
BA_ "VFrameFormat" BO_ 1492 14;
BA_ "GenMsgDelayTime" BO_ 546 10;
BA_ "GenMsgNrOfRepetition" BO_ 546 3;
BA_ "GenMsgCycleTimeFast" BO_ 546 10;
BA_ "CANFD_BRS" BO_ 546 1;
BA_ "GenMsgCycleTime" BO_ 546 100;
BA_ "GenMsgSendType" BO_ 546 10;
BA_ "GenMsgILSupport" BO_ 546 1;
BA_ "VFrameFormat" BO_ 546 14;
BA_ "GenMsgDelayTime" BO_ 1328 20;
BA_ "GenMsgNrOfRepetition" BO_ 1328 3;
BA_ "GenMsgCycleTimeFast" BO_ 1328 50;
BA_ "CANFD_BRS" BO_ 1328 1;
BA_ "GenMsgCycleTime" BO_ 1328 500;
BA_ "GenMsgSendType" BO_ 1328 10;
BA_ "GenMsgILSupport" BO_ 1328 1;
BA_ "VFrameFormat" BO_ 1328 14;
BA_ "CANFD_BRS" BO_ 897 1;
BA_ "GenMsgCycleTime" BO_ 897 200;
BA_ "GenMsgSendType" BO_ 897 0;
BA_ "GenMsgILSupport" BO_ 897 1;
BA_ "VFrameFormat" BO_ 897 14;
BA_ "CANFD_BRS" BO_ 1454 1;
BA_ "GenMsgCycleTime" BO_ 1454 1000;
BA_ "GenMsgSendType" BO_ 1454 0;
BA_ "GenMsgILSupport" BO_ 1454 1;
BA_ "VFrameFormat" BO_ 1454 14;
BA_ "CANFD_BRS" BO_ 256 1;
BA_ "GenMsgCycleTime" BO_ 256 20;
BA_ "GenMsgSendType" BO_ 256 0;
BA_ "GenMsgILSupport" BO_ 256 1;
BA_ "VFrameFormat" BO_ 256 14;
BA_ "GenSigSendType" SG_ 913 ZCUR_HSDPowerOff1_Req 0;
BA_ "GenSigSendType" SG_ 913 ZCUR_RRDrStpRsn_St 2;
BA_ "GenSigSendType" SG_ 913 ZCUR_FRDrLth_Err 2;
BA_ "GenSigSendType" SG_ 913 ZCUR_RExMirCtrl_Rsp 2;
BA_ "GenSigSendType" SG_ 913 ZCUR_RRDrLth_Err 2;
BA_ "GenSigSendType" SG_ 913 ZCUR_FRSeatAdj_Req 2;
BA_ "GenSigSendType" SG_ 913 ZCUR_FRSeatBackrestAdj_Req 2;
BA_ "GenSigSendType" SG_ 913 ZCUR_SFRTnLtErr_St 2;
BA_ "GenSigSendType" SG_ 913 ZCUR_FRSeatHgtAdj_Req 2;
BA_ "GenSigSendType" SG_ 913 ZCUR_FRSeatCshnAngAdj_Req 2;
BA_ "GenSigSendType" SG_ 913 ZCUR_FRHdlFrz_St 2;
BA_ "GenSigSendType" SG_ 913 ZCUR_FRWdwSw_St 2;
BA_ "GenSigSendType" SG_ 913 ZCUR_FRWdwMov_St 2;
BA_ "GenSigSendType" SG_ 913 ZCUR_RRWdwMov_St 2;
BA_ "GenSigSendType" SG_ 913 ZCUR_FRHdlStpRsn_St 2;
BA_ "GenSigSendType" SG_ 913 ZCUR_RRHdlStpRsn_St 2;
BA_ "GenSigSendType" SG_ 913 ZCUR_FRLthAjar_St 2;
BA_ "GenSigSendType" SG_ 913 ZCUR_RRLthAjar_St 2;
BA_ "GenSigSendType" SG_ 913 ZCUR_FRLthHlfLck_St 2;
BA_ "GenSigSendType" SG_ 913 ZCUR_RRLthHlfLck_St 2;
BA_ "GenSigSendType" SG_ 913 ZCUR_FRLthPawl_St 2;
BA_ "GenSigSendType" SG_ 913 ZCUR_RRLthPawl_St 2;
BA_ "GenSigSendType" SG_ 913 ZCUR_FRLthHome_St 2;
BA_ "GenSigSendType" SG_ 913 ZCUR_RRLthHome_St 2;
BA_ "GenSigSendType" SG_ 913 ZCUR_FRDrLth_St 2;
BA_ "GenSigSendType" SG_ 913 ZCUR_FRHdlClsPstSW_St 2;
BA_ "GenSigSendType" SG_ 913 ZCUR_RRDrLth_St 2;
BA_ "GenSigSendType" SG_ 913 ZCUR_RRHdlClsPstSW_St 2;
BA_ "GenSigSendType" SG_ 913 ZCUR_FRDrLthWrk_St 2;
BA_ "GenSigSendType" SG_ 913 ZCUR_FRHdlOpnPstSW_St 2;
BA_ "GenSigSendType" SG_ 913 ZCUR_RRDrLthWrk_St 2;
BA_ "GenSigSendType" SG_ 913 ZCUR_RRHdlOpnPstSW_St 2;
BA_ "GenSigSendType" SG_ 913 ZCUR_FRDrStpRsn_St 2;
BA_ "GenSigSendType" SG_ 913 ZCUR_RRHdlFrz_St 2;
BA_ "GenSigSendType" SG_ 913 ZCUR_FRSeatLegAngCshnExtAdj_Req 2;
BA_ "GenSigSendType" SG_ 913 ZCUR_RRWdwSw_St 2;
BA_ "GenSigSendType" SG_ 913 ZCUR_RRDrStpRsn2_St 2;
BA_ "GenSigSendType" SG_ 913 ZCUR_FRDrStpRsn2_St 2;
BA_ "GenSigSendType" SG_ 913 ZCUR_RRDrLthWrk2_St 2;
BA_ "GenSigSendType" SG_ 913 ZCUR_FRDrLthWrk2_St 2;
BA_ "GenSigSendType" SG_ 913 ZCUR_FRSunshadeSW_St 2;
BA_ "GenSigSendType" SG_ 913 ZCUR_FRLumbSuppFBAdj_Req 2;
BA_ "GenSigSendType" SG_ 913 ZCUR_FRLumbSuppUDAdj_Req 2;
BA_ "GenSigSendType" SG_ 913 ZCUR_FRDrLth2_Err 2;
BA_ "GenSigSendType" SG_ 913 ZCUR_RRDrLth2_Err 2;
BA_ "GenSigSendType" SG_ 913 ZCUR_RExMirLRMv_St 2;
BA_ "GenSigSendType" SG_ 913 ZCUR_RExMirUDStpRsn_St 2;
BA_ "GenSigSendType" SG_ 913 ZCUR_RExMirUDStp_Req 2;
BA_ "GenSigSendType" SG_ 913 ZCUR_RExMirLRStpRsn_St 2;
BA_ "GenSigSendType" SG_ 913 ZCUR_RExMirLRStp_Req 2;
BA_ "GenSigSendType" SG_ 913 ZCUR_RExMirUDMv_St 2;
BA_ "GenSigSendType" SG_ 913 ZCUR_FRSeatFBMv_St 2;
BA_ "GenSigSendType" SG_ 913 ZCUR_FRSeatBackrestMv_St 2;
BA_ "GenSigSendType" SG_ 913 ZCUR_FRSeatHgtMv_St 2;
BA_ "GenSigSendType" SG_ 913 ZCUR_FRSeatCshnAngMv_St 2;
BA_ "GenSigSendType" SG_ 913 ZCUR_FRLegAngCshnExtMv_St 2;
BA_ "GenSigSendType" SG_ 913 ZCUR_FRSeatFBStpRsn_St 2;
BA_ "GenSigSendType" SG_ 913 ZCUR_FRSeatFBStp_Req 2;
BA_ "GenSigSendType" SG_ 913 ZCUR_FRLegAngCshnExtStp_Req 2;
BA_ "GenSigSendType" SG_ 913 ZCUR_FRSeatBackrestStpRsn_St 2;
BA_ "GenSigSendType" SG_ 913 ZCUR_FRSeatBackrestStp_Req 2;
BA_ "GenSigSendType" SG_ 913 ZCUR_FRSeatHgtStpRsn_St 2;
BA_ "GenSigSendType" SG_ 913 ZCUR_FRSeatHgtStp_Req 2;
BA_ "GenSigSendType" SG_ 913 ZCUR_FRSeatCshnAngStpRsn_St 2;
BA_ "GenSigSendType" SG_ 913 ZCUR_FRSeatCshnAngStp_Req 2;
BA_ "GenSigSendType" SG_ 913 ZCUR_FRLegAngCshnExtStpRsn_St 2;
BA_ "GenSigSendType" SG_ 913 ZCUR_FRHdlDbOprt_St 2;
BA_ "GenSigSendType" SG_ 913 ZCUR_RRHdlDbOprt_St 2;
BA_ "GenSigSendType" SG_ 913 ZCUR_RExMirCtrlStp_Req 2;
BA_ "GenSigSendType" SG_ 913 ZCUR_RExMirCtrlMv_St 2;
BA_ "GenSigSendType" SG_ 913 ZCUR_RExMirCtrlStpRsn_St 2;
BA_ "GenSigSendType" SG_ 913 ZCUR_FRSeatBelt_St 0;
BA_ "GenSigStartValue" SG_ 96 ZCUF_ActlGearVaild_St 1;
BA_ "GenSigSendType" SG_ 96 ZCUF_ActlGearVaild_St 0;
BA_ "GenSigSendType" SG_ 96 ZCUF_ActlGear_St 0;
BA_ "GenSigSendType" SG_ 96 ZCUF_VehicleSpeed_Val 0;
BA_ "GenSigSendType" SG_ 96 ZCUF_VehicleSpeedValid_St 0;
BA_ "GenSigSendType" SG_ 96 ZCUF_FLTnLgt_St 0;
BA_ "GenSigSendType" SG_ 96 ZCUF_FRTnLgt_St 0;
BA_ "GenSigSendType" SG_ 96 ZCUF_Checksum4 7;
BA_ "GenSigSendType" SG_ 96 ZCUF_RollingCounter4 7;
BA_ "GenSigSendType" SG_ 96 ZCUF_LimpHomeRmnd_St 0;
BA_ "GenSigSendType" SG_ 1441 ZCUF_HSDPowerOff1_Req 2;
BA_ "GenSigSendType" SG_ 352 HDBI_LowSpdVoi_Req 2;
BA_ "GenSigSendType" SG_ 352 HDBI_LowSpdVoiTyp_Req 2;
BA_ "GenSigSendType" SG_ 352 HDBI_NFCLockUnlock_Req 2;
BA_ "GenSigSendType" SG_ 352 HDBI_RLDoorBtn_Req 2;
BA_ "GenSigSendType" SG_ 352 HDBI_RearFogBm_Req 2;
BA_ "GenSigSendType" SG_ 352 HDBI_EtnlLgt_Req 2;
BA_ "GenSigSendType" SG_ 352 HDBI_CheckSum1 7;
BA_ "GenSigSendType" SG_ 352 HDBI_RollingCounter1 7;
BA_ "GenSigSendType" SG_ 272 HDBM_FLDoor_St 0;
BA_ "GenSigSendType" SG_ 272 HDBM_LeftTurnLgt_Req 0;
BA_ "GenSigSendType" SG_ 272 HDBM_RgtTurnLgt_Req 0;
BA_ "GenSigStartValue" SG_ 272 HDBM_PowerMode_St 7;
BA_ "GenSigSendType" SG_ 272 HDBM_PowerMode_St 0;
BA_ "GenSigSendType" SG_ 272 HDBM_FRDoor_St 0;
BA_ "GenSigSendType" SG_ 272 HDBM_RLDoor_St 0;
BA_ "GenSigSendType" SG_ 272 HDBM_RRDoor_St 0;
BA_ "GenSigSendType" SG_ 272 HDBM_CheckSum1 7;
BA_ "GenSigSendType" SG_ 272 HDBM_RollingCounter1 7;
BA_ "GenSigStartValue" SG_ 272 HDBM_TargCoastRegen_Req 255;
BA_ "GenSigSendType" SG_ 272 HDBM_TargCoastRegen_Req 0;
BA_ "GenSigSendType" SG_ 272 HDBM_DMSPTModeChg_Req 0;
BA_ "GenSigSendType" SG_ 272 HDBM_DMSEPSModeChg_Req 0;
BA_ "GenSigSendType" SG_ 272 HDBM_DMSESCModeChg_Req 0;
BA_ "GenSigSendType" SG_ 272 HDBM_ChrgCap_St 0;
BA_ "GenSigSendType" SG_ 689 HDBM_TCMACSOV_Req 0;
BA_ "GenSigSendType" SG_ 689 HDBM_TCMHPLowPressSOV_Req 0;
BA_ "GenSigSendType" SG_ 689 HDBM_TCMHPHighPressSOV_Req 0;
BA_ "GenSigSendType" SG_ 689 HDBM_HEXVInit_Req 0;
BA_ "GenSigSendType" SG_ 689 HDBM_CHVHTrgtPwr_Req 0;
BA_ "GenSigSendType" SG_ 689 HDBM_CHVHHvCooltHeatEn_Req 0;
BA_ "GenSigSendType" SG_ 689 HDBM_HEXVSet_Req 0;
BA_ "GenSigSendType" SG_ 689 HDBM_V3WHeatEnb_Req 0;
BA_ "GenSigSendType" SG_ 689 HDBM_V3WHeatTargetPst_Req 0;
BA_ "GenSigSendType" SG_ 689 HDBM_HeatPumpEnb_Req 0;
BA_ "GenSigSendType" SG_ 689 HDBM_HeatPumpTargetSpdPct_Req 0;
BA_ "GenSigSendType" SG_ 689 HDBM_OHXEXVMoveEn_Req 0;
BA_ "GenSigSendType" SG_ 689 HDBM_CHLEXVMoveEn_Req 0;
BA_ "GenSigSendType" SG_ 689 HDBM_OHXEXVSet_Req 0;
BA_ "GenSigSendType" SG_ 689 HDBM_CHLEXVSet_Req 0;
BA_ "GenSigSendType" SG_ 689 HDBM_ComprActlPwr_Val 0;
BA_ "GenSigSendType" SG_ 689 HDBM_DMSVehMode_St 0;
BA_ "GenSigSendType" SG_ 689 HDBM_CHVHActlPwr_Val 0;
BA_ "GenSigSendType" SG_ 689 HDBM_ACSysTotPwr_Req 0;
BA_ "GenSigSendType" SG_ 689 HDBM_DMSPTMode_St 0;
BA_ "GenSigStartValue" SG_ 689 HDBM_DMSEPSModeInfo_St 1;
BA_ "GenSigSendType" SG_ 689 HDBM_DMSEPSModeInfo_St 0;
BA_ "GenSigSendType" SG_ 689 HDBM_ACHVTotoaPower_Req 0;
BA_ "GenSigSendType" SG_ 689 HDBM_SRRSBR_Req 0;
BA_ "GenSigSendType" SG_ 689 HDBM_SBRSound_Req 0;
BA_ "GenSigSendType" SG_ 689 HDBM_FLSBR_Req 0;
BA_ "GenSigSendType" SG_ 689 HDBM_FRSBR_Req 0;
BA_ "GenSigSendType" SG_ 689 HDBM_SRLSBR_Req 0;
BA_ "GenSigSendType" SG_ 689 HDBM_SRMSBR_Req 0;
BA_ "GenSigSendType" SG_ 689 HDBM_V3WHeatCalEnb_Req 0;
BA_ "GenSigSendType" SG_ 689 HDBM_OHXEXVInit_Req 0;
BA_ "GenSigSendType" SG_ 689 HDBM_CHLEXVInit_Req 0;
BA_ "GenSigSendType" SG_ 689 HDBM_CHVHTrgtTemp_Req 0;
BA_ "GenSigSendType" SG_ 689 HDBM_HEXVMoveEnb_Req 0;
BA_ "GenSigSendType" SG_ 689 HDBM_ACCMPwrLmt_Req 0;
BA_ "GenSigSendType" SG_ 689 HDBM_ACCMErrorClean_Req 0;
BA_ "GenSigSendType" SG_ 689 HDBM_ACCMEnable_Req 0;
BA_ "GenSigSendType" SG_ 689 HDBM_ACCMSpdCtrl_Req 0;
BA_ "GenSigSendType" SG_ 689 HDBM_CmpmtInAirPmDnsty_Val 0;
BA_ "GenSigSendType" SG_ 689 HDBM_CmpmtInAirPmAQI_St 0;
BA_ "GenSigStartValue" SG_ 1488 HDBM_FLTpmsPress_Val 255;
BA_ "GenSigSendType" SG_ 1488 HDBM_FLTpmsPress_Val 0;
BA_ "GenSigStartValue" SG_ 1488 HDBM_EnvirTemp_Val 126;
BA_ "GenSigSendType" SG_ 1488 HDBM_EnvirTemp_Val 0;
BA_ "GenSigSendType" SG_ 1488 HDBM_ComprWork_St 0;
BA_ "GenSigStartValue" SG_ 1488 HDBM_FragChannel3Life_Val 360;
BA_ "GenSigSendType" SG_ 1488 HDBM_FragChannel3Life_Val 0;
BA_ "GenSigStartValue" SG_ 1488 HDBM_FLTpmsTemp_Val 255;
BA_ "GenSigSendType" SG_ 1488 HDBM_FLTpmsTemp_Val 0;
BA_ "GenSigSendType" SG_ 1488 HDBM_FragCh1Type_Spec 0;
BA_ "GenSigSendType" SG_ 1488 HDBM_EnSvLtCtrl_Req 0;
BA_ "GenSigStartValue" SG_ 1488 HDBM_FragChannel2Life_Val 360;
BA_ "GenSigSendType" SG_ 1488 HDBM_FragChannel2Life_Val 0;
BA_ "GenSigStartValue" SG_ 1488 HDBM_FragChannel3Life_St 360;
BA_ "GenSigSendType" SG_ 1488 HDBM_FragChannel3Life_St 0;
BA_ "GenSigSendType" SG_ 1488 HDBM_FragCh2Type_Spec 0;
BA_ "GenSigSendType" SG_ 1488 HDBM_FragCh3Type_Spec 0;
BA_ "GenSigSendType" SG_ 1488 HDBM_RACCoolOrHeatOrVent_St 0;
BA_ "GenSigStartValue" SG_ 1488 HDBM_FRTpmsPress_Val 255;
BA_ "GenSigSendType" SG_ 1488 HDBM_FRTpmsPress_Val 0;
BA_ "GenSigStartValue" SG_ 1488 HDBM_RLTpmsPress_Val 255;
BA_ "GenSigSendType" SG_ 1488 HDBM_RLTpmsPress_Val 0;
BA_ "GenSigStartValue" SG_ 1488 HDBM_RRTpmsPress_Val 255;
BA_ "GenSigSendType" SG_ 1488 HDBM_RRTpmsPress_Val 0;
BA_ "GenSigStartValue" SG_ 1488 HDBM_FRTpmsTemp_Val 255;
BA_ "GenSigSendType" SG_ 1488 HDBM_FRTpmsTemp_Val 0;
BA_ "GenSigSendType" SG_ 1488 HDBM_InFilterLifeRemind 0;
BA_ "GenSigStartValue" SG_ 1488 HDBM_RLTpmsTemp_Val 255;
BA_ "GenSigSendType" SG_ 1488 HDBM_RLTpmsTemp_Val 0;
BA_ "GenSigStartValue" SG_ 1488 HDBM_RRTpmsTemp_Val 255;
BA_ "GenSigSendType" SG_ 1488 HDBM_RRTpmsTemp_Val 0;
BA_ "GenSigSendType" SG_ 1488 HDBM_FrtDeiceDefog_St 0;
BA_ "GenSigSendType" SG_ 1488 HDBM_CampingMode_Rsp 0;
BA_ "GenSigSendType" SG_ 1488 HDBM_CarMode_St 0;
BA_ "GenSigSendType" SG_ 1488 HDBM_CHVHWork_St 0;
BA_ "GenSigSendType" SG_ 1488 HDBM_FLHdlBrkCnt_Val 0;
BA_ "GenSigSendType" SG_ 1488 HDBM_RLHdlBrkCnt_Val 0;
BA_ "GenSigSendType" SG_ 1488 HDBM_FRHdlBrkCnt_Val 0;
BA_ "GenSigSendType" SG_ 1488 HDBM_RRHdlBrkCnt_Val 0;
BA_ "GenSigSendType" SG_ 421 HDBM_FLTpmsTempWarn_St 2;
BA_ "GenSigSendType" SG_ 421 HDBM_FRTpmsTempWarn_St 4;
BA_ "GenSigSendType" SG_ 421 HDBM_FLTpmsLeakWarn_St 2;
BA_ "GenSigSendType" SG_ 421 HDBM_FRTpmsLeakWarn_St 2;
BA_ "GenSigSendType" SG_ 421 HDBM_RLTpmsLeakWarn_St 2;
BA_ "GenSigSendType" SG_ 421 HDBM_RRTpmsLeakWarn_St 2;
BA_ "GenSigSendType" SG_ 421 HDBM_RemFDefrostTime_Rsp 2;
BA_ "GenSigSendType" SG_ 421 HDBM_RemVentilateRefine_Rsp 2;
BA_ "GenSigSendType" SG_ 421 HDBM_RemVentilateRefineTime_Rsp 2;
BA_ "GenSigSendType" SG_ 421 HDBM_RemAppointActive_Rsp 2;
BA_ "GenSigSendType" SG_ 421 HDBM_RemACUnavailRsn_Spec 2;
BA_ "GenSigSendType" SG_ 421 HDBM_RLTpmsTempWarn_St 2;
BA_ "GenSigSendType" SG_ 421 HDBM_RRTpmsTempWarn_St 2;
BA_ "GenSigSendType" SG_ 421 HDBM_RLTpmsPressWarn_St 2;
BA_ "GenSigSendType" SG_ 421 HDBM_RRTpmsPressWarn_St 2;
BA_ "GenSigSendType" SG_ 421 HDBM_FLTpmsPressWarn_St 2;
BA_ "GenSigSendType" SG_ 421 HDBM_FRTpmsPressWarn_St 2;
BA_ "GenSigSendType" SG_ 421 HDBM_CheckSum2 7;
BA_ "GenSigSendType" SG_ 421 HDBM_RollingCounter2 7;
BA_ "GenSigSendType" SG_ 421 HDBM_RRTpmsBattle_St 2;
BA_ "GenSigSendType" SG_ 421 HDBM_FLTpmsSensorFailure_St 2;
BA_ "GenSigSendType" SG_ 421 HDBM_FRTpmsSensorFailure_St 2;
BA_ "GenSigSendType" SG_ 421 HDBM_RLTpmsSensorFailure_St 2;
BA_ "GenSigSendType" SG_ 421 HDBM_RRTpmsSensorFailure_St 2;
BA_ "GenSigSendType" SG_ 421 HDBM_FLTpmsBattle_St 2;
BA_ "GenSigSendType" SG_ 421 HDBM_FRTpmsBattle_St 2;
BA_ "GenSigSendType" SG_ 421 HDBM_RLTpmsBattle_St 2;
BA_ "GenSigSendType" SG_ 816 HDBM_BckLtBrtDes_Req 2;
BA_ "GenSigSendType" SG_ 816 HDBM_FLTpLtBrtDes_Req 2;
BA_ "GenSigSendType" SG_ 816 HDBM_RLTpLtBrtDes_Req 2;
BA_ "GenSigSendType" SG_ 816 HDBM_HoodLatch_St 2;
BA_ "GenSigSendType" SG_ 816 HDBM_FRTpLtBrtDes_Req 2;
BA_ "GenSigSendType" SG_ 816 HDBM_RRTpLtBrtDes_Req 2;
BA_ "GenSigStartValue" SG_ 816 HDBM_EtnlLgt_Rsp 2;
BA_ "GenSigSendType" SG_ 816 HDBM_EtnlLgt_Rsp 2;
BA_ "GenSigSendType" SG_ 816 HDBM_CenterLock_St 2;
BA_ "GenSigSendType" SG_ 816 HDBM_LwLgt_Req 2;
BA_ "GenSigSendType" SG_ 816 HDBM_ACFaultLevel_St 2;
BA_ "GenSigSendType" SG_ 816 HDBM_FLPstnLgt_Req 2;
BA_ "GenSigSendType" SG_ 816 HDBM_FRPstnLgt_Req 2;
BA_ "GenSigSendType" SG_ 816 HDBM_HighLgt_Req 2;
BA_ "GenSigSendType" SG_ 816 HDBM_OtkLgt_Req 2;
BA_ "GenSigSendType" SG_ 816 HDBM_FLWdwCtl_Req 2;
BA_ "GenSigSendType" SG_ 816 HDBM_FRWdwCtl_Req 2;
BA_ "GenSigSendType" SG_ 816 HDBM_SteerTiltAdj_Req 2;
BA_ "GenSigSendType" SG_ 816 HDBM_RLWdwCtl_Req 2;
BA_ "GenSigSendType" SG_ 816 HDBM_SteerTeleAdj_Req 2;
BA_ "GenSigStartValue" SG_ 816 HDBM_FWiperCtrl_Req 7;
BA_ "GenSigSendType" SG_ 816 HDBM_FWiperCtrl_Req 2;
BA_ "GenSigSendType" SG_ 816 HDBM_FWiperWashCtrl_Req 2;
BA_ "GenSigSendType" SG_ 816 HDBM_FLHdlCtrl_Req 2;
BA_ "GenSigSendType" SG_ 816 HDBM_RLHdlCtrl_Req 2;
BA_ "GenSigSendType" SG_ 816 HDBM_FRHdlCtrl_Req 2;
BA_ "GenSigSendType" SG_ 816 HDBM_TpLtClrDes_Req 2;
BA_ "GenSigSendType" SG_ 816 HDBM_RRHdlCtrl_Req 2;
BA_ "GenSigSendType" SG_ 816 HDBM_RLPstnLgt_Req 2;
BA_ "GenSigSendType" SG_ 816 HDBM_RRPstnLgt_Req 2;
BA_ "GenSigSendType" SG_ 816 HDBM_RearFogBm_Req 2;
BA_ "GenSigSendType" SG_ 816 HDBM_RRWdwCtl_Req 2;
BA_ "GenSigSendType" SG_ 816 HDBM_RsLgt_Req 2;
BA_ "GenSigSendType" SG_ 816 HDBM_TrkLtCtrl_Req 2;
BA_ "GenSigSendType" SG_ 816 HDBM_RollingCounter3 7;
BA_ "GenSigSendType" SG_ 816 HDBM_CheckSum3 7;
BA_ "GenSigSendType" SG_ 816 HDBM_FRHdlLearn_Req 2;
BA_ "GenSigSendType" SG_ 816 HDBM_RRHdlLearn_Req 2;
BA_ "GenSigSendType" SG_ 816 HDBM_FLHdlLearn_Req 2;
BA_ "GenSigSendType" SG_ 816 HDBM_RLHdlLearn_Req 2;
BA_ "GenSigStartValue" SG_ 816 HDBM_FLTpLtClrDes_Req 1;
BA_ "GenSigSendType" SG_ 816 HDBM_FLTpLtClrDes_Req 2;
BA_ "GenSigStartValue" SG_ 816 HDBM_RLTpLtClrDes_Req 1;
BA_ "GenSigSendType" SG_ 816 HDBM_RLTpLtClrDes_Req 2;
BA_ "GenSigSendType" SG_ 816 HDBM_FRTpLtClrDes_Req 2;
BA_ "GenSigSendType" SG_ 816 HDBM_RRTpLtClrDes_Req 2;
BA_ "GenSigStartValue" SG_ 816 HDBM_SteerTiltSpd_Req 30;
BA_ "GenSigSendType" SG_ 816 HDBM_SteerTiltSpd_Req 2;
BA_ "GenSigStartValue" SG_ 816 HDBM_SteerTeleSpd_Req 30;
BA_ "GenSigSendType" SG_ 816 HDBM_SteerTeleSpd_Req 2;
BA_ "GenSigSendType" SG_ 816 HDBM_SteerLn_Req 2;
BA_ "GenSigSendType" SG_ 816 HDBM_ParkingSwitch_Req 2;
BA_ "GenSigSendType" SG_ 816 HDBM_EHBMBrkModeSet_Req 2;
BA_ "GenSigSendType" SG_ 816 HDBM_TCSSw_Req 2;
BA_ "GenSigSendType" SG_ 816 HDBM_AVHSw_Req 2;
BA_ "GenSigSendType" SG_ 816 HDBM_HDCSw_Req 2;
BA_ "GenSigSendType" SG_ 816 HDBM_CSTSw_Req 2;
BA_ "GenSigSendType" SG_ 816 HDBM_ESCSw_Req 2;
BA_ "GenSigSendType" SG_ 1489 HDBM_FragSwitchEn_Rsp 2;
BA_ "GenSigSendType" SG_ 1489 HDBM_FragCh1Sw_St 2;
BA_ "GenSigSendType" SG_ 1489 HDBM_FragCh2Sw_St 2;
BA_ "GenSigSendType" SG_ 1489 HDBM_FragCh3Sw_St 2;
BA_ "GenSigSendType" SG_ 1489 HDBM_FragConcLvl_Rsp 2;
BA_ "GenSigSendType" SG_ 1489 HDBM_AQSAirQuality_Val 2;
BA_ "GenSigSendType" SG_ 1489 HDBM_PM25Set_St 2;
BA_ "GenSigSendType" SG_ 1489 HDBM_PM25Trigger_St 2;
BA_ "GenSigSendType" SG_ 1489 HDBM_FDeiceDefrost_Rsp 2;
BA_ "GenSigSendType" SG_ 1489 HDBM_AutoDefogSensDectect_St 2;
BA_ "GenSigSendType" SG_ 1489 HDBM_AutoDefrostSet_St 2;
BA_ "GenSigSendType" SG_ 1489 HDBM_AutoDefrostTrigger_St 2;
BA_ "GenSigSendType" SG_ 1489 HDBM_IONSet_St 2;
BA_ "GenSigSendType" SG_ 1489 HDBM_ACSwtich_St 2;
BA_ "GenSigSendType" SG_ 1489 HDBM_FACSwitch_Rsp 2;
BA_ "GenSigSendType" SG_ 1489 HDBM_FACAirFlowLevel_St 2;
BA_ "GenSigSendType" SG_ 1489 HDBM_FAcCoolOrHeatOrVent_St 0;
BA_ "GenSigStartValue" SG_ 1489 HDBM_FLeftTempSet_St 14;
BA_ "GenSigSendType" SG_ 1489 HDBM_FLeftTempSet_St 2;
BA_ "GenSigStartValue" SG_ 1489 HDBM_FRightTempSet_St 14;
BA_ "GenSigSendType" SG_ 1489 HDBM_FRightTempSet_St 2;
BA_ "GenSigSendType" SG_ 1489 HDBM_FTempAreaSync_St 2;
BA_ "GenSigSendType" SG_ 1489 HDBM_HvOnACM_Req 2;
BA_ "GenSigSendType" SG_ 1489 HDBM_HVWork_Req 2;
BA_ "GenSigSendType" SG_ 1489 HDBM_RESSCoolFault_St 2;
BA_ "GenSigSendType" SG_ 1489 HDBM_FACAirFlowLevelAuto_St 2;
BA_ "GenSigSendType" SG_ 1489 HDBM_FACAirFlowModeAuto_St 2;
BA_ "GenSigSendType" SG_ 1489 HDBM_FACCoolOrHeatOrVentAuto_St 2;
BA_ "GenSigStartValue" SG_ 1489 HDBM_TDrDegDes_Req 254;
BA_ "GenSigSendType" SG_ 1489 HDBM_TDrDegDes_Req 2;
BA_ "GenSigSendType" SG_ 1489 HDBM_TDrDegSet_Rsp 2;
BA_ "GenSigSendType" SG_ 1489 HDBM_LDRLgt_Req 2;
BA_ "GenSigSendType" SG_ 1489 HDBM_RDRLgt_Req 2;
BA_ "GenSigSendType" SG_ 1489 HDBM_FLDrPdlLtCtrl_Req 2;
BA_ "GenSigSendType" SG_ 1489 HDBM_FRDrPdlLtCtrl_Req 2;
BA_ "GenSigSendType" SG_ 1489 HDBM_RLDrPdlLtCtrl_Req 2;
BA_ "GenSigSendType" SG_ 1489 HDBM_RRDrPdlLtCtrl_Req 2;
BA_ "GenSigSendType" SG_ 1489 HDBM_FLDrCtrl_Req 2;
BA_ "GenSigSendType" SG_ 1489 HDBM_FRDrCtrl_Req 2;
BA_ "GenSigSendType" SG_ 1489 HDBM_RLDrCtrl_Req 2;
BA_ "GenSigSendType" SG_ 1489 HDBM_RRDrCtrl_Req 2;
BA_ "GenSigSendType" SG_ 1489 HDBM_FLDrLthCinch_Req 2;
BA_ "GenSigSendType" SG_ 1489 HDBM_TDrSpdDes_Req 2;
BA_ "GenSigSendType" SG_ 1489 HDBM_TDrCtrl_Req 2;
BA_ "GenSigSendType" SG_ 1489 HDBM_TDrLthCinch_Req 2;
BA_ "GenSigSendType" SG_ 1489 HDBM_RLDrLthCinch_Req 2;
BA_ "GenSigSendType" SG_ 1489 HDBM_FRDrLthCinch_Req 2;
BA_ "GenSigSendType" SG_ 1489 HDBM_RRDrLthCinch_Req 2;
BA_ "GenSigSendType" SG_ 1489 HDBM_RLDrLthRls_Req 2;
BA_ "GenSigSendType" SG_ 1489 HDBM_FRDrLthRls_Req 2;
BA_ "GenSigSendType" SG_ 1489 HDBM_RRDrLthRls_Req 2;
BA_ "GenSigSendType" SG_ 1489 HDBM_FLDrLthRls_Req 2;
BA_ "GenSigSendType" SG_ 1489 HDBM_RESSCoolPwrLim_St 2;
BA_ "GenSigSendType" SG_ 1489 HDBM_RESSHeatFault_St 2;
BA_ "GenSigSendType" SG_ 1489 HDBM_ACMWork_St 0;
BA_ "GenSigSendType" SG_ 1489 HDBM_HeatRecycle_Req 2;
BA_ "GenSigSendType" SG_ 1489 HDBM_DeiceDefog_Req 2;
BA_ "GenSigSendType" SG_ 1489 HDBM_HeatRecycleDisable_St 2;
BA_ "GenSigSendType" SG_ 1489 HDBM_ChrgCapCtrl_Req 2;
BA_ "GenSigSendType" SG_ 1489 HDBM_TDrLthRls_Req 2;
BA_ "GenSigSendType" SG_ 1489 HDBM_RRDrLthCinchFbd_Req 2;
BA_ "GenSigSendType" SG_ 1489 HDBM_FLDrLthCinchFbd_Req 2;
BA_ "GenSigSendType" SG_ 1489 HDBM_RLDrLthCinchFbd_Req 2;
BA_ "GenSigSendType" SG_ 1489 HDBM_FRDrLthCinchFbd_Req 2;
BA_ "GenSigSendType" SG_ 1489 HDBM_ChrgCapLearn_Req 2;
BA_ "GenSigSendType" SG_ 1489 HDBM_IONSwitch_Req 2;
BA_ "GenSigSendType" SG_ 1489 HDBM_InPm25SnsrActn_Req 0;
BA_ "GenSigSendType" SG_ 1489 HDBM_TDrLthCinchFbd_Req 2;
BA_ "GenSigSendType" SG_ 1500 HDBM_VB1_NetworkReqCondition0 0;
BA_ "GenSigSendType" SG_ 1500 HDBM_VB1_NetworkReqCondition1 0;
BA_ "GenSigSendType" SG_ 1500 HDBM_VB1_NetworkReqCondition2 0;
BA_ "GenSigSendType" SG_ 1500 HDBM_VB1_NetworkReqCondition3 0;
BA_ "GenSigSendType" SG_ 1500 HDBM_VB1_NetworkReqCondition4 0;
BA_ "GenSigSendType" SG_ 1500 HDBM_VB1_NetworkReqCondition5 0;
BA_ "GenSigSendType" SG_ 1500 HDBM_VB1_NetworkReqCondition6 0;
BA_ "GenSigSendType" SG_ 1500 HDBM_VB1_NetworkReqCondition7 0;
BA_ "GenSigSendType" SG_ 1500 HDBM_VB1_NetworkReqCondition8 0;
BA_ "GenSigSendType" SG_ 1500 HDBM_VB1_NetworkReqCondition9 0;
BA_ "GenSigSendType" SG_ 1500 HDBM_VB1_NetworkReqCondition10 0;
BA_ "GenSigSendType" SG_ 1500 HDBM_VB1_NetworkReqCondition11 0;
BA_ "GenSigSendType" SG_ 1500 HDBM_VB1_NetworkReqCondition12 0;
BA_ "GenSigSendType" SG_ 1500 HDBM_VB1_NetworkReqCondition13 0;
BA_ "GenSigSendType" SG_ 1500 HDBM_VB1_NetworkReqCondition14 0;
BA_ "GenSigSendType" SG_ 1500 HDBM_VB1_NetworkReqCondition15 0;
BA_ "GenSigSendType" SG_ 1500 HDBM_VB1_NetworkReqCondition16 0;
BA_ "GenSigSendType" SG_ 1500 HDBM_VB1_NetworkReqCondition17 0;
BA_ "GenSigSendType" SG_ 1500 HDBM_VB1_NetworkReqCondition18 0;
BA_ "GenSigSendType" SG_ 1500 HDBM_VB1_NetworkReqCondition19 0;
BA_ "GenSigSendType" SG_ 1500 HDBM_VB1_NetworkReqCondition20 0;
BA_ "GenSigSendType" SG_ 1500 HDBM_VB1_NetworkReqCondition21 0;
BA_ "GenSigSendType" SG_ 1500 HDBM_VB1_NetworkReqCondition22 0;
BA_ "GenSigSendType" SG_ 1500 HDBM_VB1_NetworkReqCondition23 0;
BA_ "GenSigSendType" SG_ 1500 HDBM_VB1_NetworkReqCondition24 0;
BA_ "GenSigSendType" SG_ 1500 HDBM_VB1_NetworkReqCondition25 0;
BA_ "GenSigSendType" SG_ 1500 HDBM_VB1_NetworkReqCondition26 0;
BA_ "GenSigSendType" SG_ 1500 HDBM_VB1_NetworkReqCondition27 0;
BA_ "GenSigSendType" SG_ 1500 HDBM_VB1_NetworkReqCondition28 0;
BA_ "GenSigSendType" SG_ 1500 HDBM_VB1_NetworkReqCondition29 0;
BA_ "GenSigSendType" SG_ 1500 HDBM_VB1_NetworkReqCondition30 0;
BA_ "GenSigSendType" SG_ 1500 HDBM_VB1_NetworkReqCondition31 0;
BA_ "GenSigSendType" SG_ 1409 HDBM_WakeupReq_HDBT 2;
BA_ "GenSigSendType" SG_ 1409 HDBM_WakeupReq_HDBI 2;
BA_ "GenSigSendType" SG_ 1409 HDBM_WakeupReq_HDBA 2;
BA_ "GenSigSendType" SG_ 1409 HDBM_WakeupReq_HDBM 2;
BA_ "GenSigSendType" SG_ 1409 HDBM_WakeupReq_ZCUF 2;
BA_ "GenSigSendType" SG_ 1409 HDBM_WakeupReq_ZCUL 2;
BA_ "GenSigSendType" SG_ 1409 HDBM_WakeupReq_ZCUR 2;
BA_ "GenSigSendType" SG_ 1409 HDBM_WakeupReq_ZCUT 2;
BA_ "GenSigSendType" SG_ 1025 HDBM_NodeAddress_VB1 0;
BA_ "GenSigSendType" SG_ 1025 HDBM_RepeatMsgReq_VB1 0;
BA_ "GenSigSendType" SG_ 1025 HDBM_ActiveWakeup_VB1 0;
BA_ "GenSigSendType" SG_ 1025 HDBM_PartialNetworkInfo_VB1 0;
BA_ "GenSigSendType" SG_ 1025 HDBM_RepeatMsgSt_VB1 0;
BA_ "GenSigSendType" SG_ 1025 HDBM_PN_HDBT_VB1 0;
BA_ "GenSigSendType" SG_ 1025 HDBM_PN_HDBI_VB1 0;
BA_ "GenSigSendType" SG_ 1025 HDBM_PN_HDBA_VB1 0;
BA_ "GenSigSendType" SG_ 1025 HDBM_PN_HDBM_VB1 0;
BA_ "GenSigSendType" SG_ 1025 HDBM_PN_ZCUF_VB1 0;
BA_ "GenSigSendType" SG_ 1025 HDBM_PN_ZCUL_VB1 0;
BA_ "GenSigSendType" SG_ 1025 HDBM_PN_ZCUR_VB1 0;
BA_ "GenSigSendType" SG_ 1025 HDBM_PN_ZCUT_VB1 0;
BA_ "GenSigSendType" SG_ 690 HDBM_BrkLgt_Req 2;
BA_ "GenSigSendType" SG_ 690 HDBM_Horn_Req 2;
BA_ "GenSigSendType" SG_ 690 HDBM_KeyResearch_Req 2;
BA_ "GenSigSendType" SG_ 690 HDBM_HHChrgPileRecognize_St 2;
BA_ "GenSigSendType" SG_ 690 HDBM_AGSEn_Req 2;
BA_ "GenSigSendType" SG_ 690 HDBM_AGSPosition_Req 0;
BA_ "GenSigSendType" SG_ 690 HDBM_ECFEn_Req 2;
BA_ "GenSigSendType" SG_ 690 HDBM_ECFSpdPercent_Req 0;
BA_ "GenSigSendType" SG_ 690 HDBM_FHVACLeftMixPos_Req 0;
BA_ "GenSigSendType" SG_ 690 HDBM_FHVACRigtMixPos_Req 0;
BA_ "GenSigSendType" SG_ 690 HDBM_FHVACModePos_Req 0;
BA_ "GenSigSendType" SG_ 690 HDBM_FHVACCyclePos_Req 0;
BA_ "GenSigSendType" SG_ 690 HDBM_FHVACBypassPos_Req 0;
BA_ "GenSigSendType" SG_ 690 HDBM_FHVACDefrostPos_Req 0;
BA_ "GenSigSendType" SG_ 690 HDBM_FHVACBLWPWM_Req 0;
BA_ "GenSigSendType" SG_ 690 HDBM_FHVACBLWRelay_Req 0;
BA_ "GenSigSendType" SG_ 690 HDBM_OTAMode_St 0;
BA_ "GenSigSendType" SG_ 422 HDBM_FRSeatMsgStrth_Req 2;
BA_ "GenSigSendType" SG_ 422 HDBM_SRLSeatHt_Req 2;
BA_ "GenSigSendType" SG_ 422 HDBM_SRLSeatVtlt_Req 2;
BA_ "GenSigSendType" SG_ 422 HDBM_SRRSeatHt_Req 2;
BA_ "GenSigSendType" SG_ 422 HDBM_SRRSeatVtlt_Req 2;
BA_ "GenSigSendType" SG_ 422 HDBM_SteerHt_Req 2;
BA_ "GenSigSendType" SG_ 422 HDBM_ExMirHt_Req 2;
BA_ "GenSigSendType" SG_ 422 HDBM_FLSeatHt_Req 2;
BA_ "GenSigSendType" SG_ 422 HDBM_FLSeatVtlt_Req 2;
BA_ "GenSigSendType" SG_ 422 HDBM_FLSeatMsg_Req 2;
BA_ "GenSigSendType" SG_ 422 HDBM_FLSeatMsgMode_Req 2;
BA_ "GenSigSendType" SG_ 422 HDBM_FLSeatMsgStrth_Req 2;
BA_ "GenSigSendType" SG_ 422 HDBM_FRSeatHt_Req 2;
BA_ "GenSigSendType" SG_ 422 HDBM_FRSeatVtlt_Req 4;
BA_ "GenSigSendType" SG_ 422 HDBM_FRSeatMsg_Req 2;
BA_ "GenSigSendType" SG_ 422 HDBM_FRSeatMsgMode_Req 2;
BA_ "GenSigSendType" SG_ 423 HDBM_FLSeatHgtAdj_Req 2;
BA_ "GenSigSendType" SG_ 423 HDBM_FRLegAngCshnExtAdj_Req 2;
BA_ "GenSigStartValue" SG_ 423 HDBM_FLSeatFBAdjSpd_Req 30;
BA_ "GenSigSendType" SG_ 423 HDBM_FLSeatFBAdjSpd_Req 2;
BA_ "GenSigSendType" SG_ 423 HDBM_FLLegAngCshnExtAdj_Req 2;
BA_ "GenSigStartValue" SG_ 423 HDBM_FLSeatBackrestAdjSpd_Req 30;
BA_ "GenSigSendType" SG_ 423 HDBM_FLSeatBackrestAdjSpd_Req 2;
BA_ "GenSigStartValue" SG_ 423 HDBM_FLSeatHgtAdjSpd_Req 30;
BA_ "GenSigSendType" SG_ 423 HDBM_FLSeatHgtAdjSpd_Req 2;
BA_ "GenSigStartValue" SG_ 423 HDBM_FLSeatCshnAngAdjSpd_Req 30;
BA_ "GenSigSendType" SG_ 423 HDBM_FLSeatCshnAngAdjSpd_Req 2;
BA_ "GenSigStartValue" SG_ 423 HDBM_FLLegAngCshnExtAdjSpd_Req 30;
BA_ "GenSigSendType" SG_ 423 HDBM_FLLegAngCshnExtAdjSpd_Req 2;
BA_ "GenSigStartValue" SG_ 423 HDBM_FRSeatFBAdjSpd_Req 30;
BA_ "GenSigSendType" SG_ 423 HDBM_FRSeatFBAdjSpd_Req 2;
BA_ "GenSigStartValue" SG_ 423 HDBM_FRSeatBackrestAdjSpd_Req 30;
BA_ "GenSigSendType" SG_ 423 HDBM_FRSeatBackrestAdjSpd_Req 2;
BA_ "GenSigStartValue" SG_ 423 HDBM_FRSeatHgtAdjSpd_Req 30;
BA_ "GenSigSendType" SG_ 423 HDBM_FRSeatHgtAdjSpd_Req 2;
BA_ "GenSigStartValue" SG_ 423 HDBM_FRSeatCshnAngAdjSpd_Req 30;
BA_ "GenSigSendType" SG_ 423 HDBM_FRSeatCshnAngAdjSpd_Req 2;
BA_ "GenSigStartValue" SG_ 423 HDBM_FRLegAngCshnExtAdjSpd_Req 30;
BA_ "GenSigSendType" SG_ 423 HDBM_FRLegAngCshnExtAdjSpd_Req 2;
BA_ "GenSigSendType" SG_ 423 HDBM_FLLumbSuppFBAdj_Req 2;
BA_ "GenSigSendType" SG_ 423 HDBM_FLLumbSuppUDAdj_Req 2;
BA_ "GenSigSendType" SG_ 423 HDBM_FRLumbSuppFBAdj_Req 2;
BA_ "GenSigSendType" SG_ 423 HDBM_FRLumbSuppUDAdj_Req 2;
BA_ "GenSigSendType" SG_ 423 HDBM_FLSeatCshnAngAdj_Req 2;
BA_ "GenSigSendType" SG_ 423 HDBM_FLSeatFBAdj_Req 2;
BA_ "GenSigSendType" SG_ 423 HDBM_FLSeatBackrestAdj_Req 2;
BA_ "GenSigSendType" SG_ 423 HDBM_FRSeatHgtAdj_Req 2;
BA_ "GenSigSendType" SG_ 423 HDBM_FRSeatFBAdj_Req 2;
BA_ "GenSigSendType" SG_ 423 HDBM_FRSeatBackrestAdj_Req 2;
BA_ "GenSigSendType" SG_ 423 HDBM_FRSeatCshnAngAdj_Req 2;
BA_ "GenSigSendType" SG_ 423 HDBM_RExMirUDAdj_Req 2;
BA_ "GenSigSendType" SG_ 423 HDBM_RExMirLRAdj_Req 2;
BA_ "GenSigSendType" SG_ 423 HDBM_LExMirUDAdj_Req 2;
BA_ "GenSigSendType" SG_ 423 HDBM_LExMirLRAdj_Req 2;
BA_ "GenSigSendType" SG_ 423 HDBM_RollingCounter4 7;
BA_ "GenSigSendType" SG_ 423 HDBM_CheckSum4 7;
BA_ "GenSigStartValue" SG_ 423 HDBM_LExMirCtrl_Req 3;
BA_ "GenSigSendType" SG_ 423 HDBM_LExMirCtrl_Req 2;
BA_ "GenSigStartValue" SG_ 423 HDBM_RExMirCtrl_Req 3;
BA_ "GenSigSendType" SG_ 423 HDBM_RExMirCtrl_Req 2;
BA_ "GenSigStartValue" SG_ 423 HDBM_LExMirCtrlSpd_Req 30;
BA_ "GenSigSendType" SG_ 423 HDBM_LExMirCtrlSpd_Req 2;
BA_ "GenSigStartValue" SG_ 423 HDBM_RExMirCtrlSpd_Req 30;
BA_ "GenSigSendType" SG_ 423 HDBM_RExMirCtrlSpd_Req 2;
BA_ "GenSigStartValue" SG_ 423 HDBM_RExMirLRAdjSpd_Req 30;
BA_ "GenSigSendType" SG_ 423 HDBM_RExMirLRAdjSpd_Req 2;
BA_ "GenSigStartValue" SG_ 423 HDBM_LExMirUDAdjSpd_Req 30;
BA_ "GenSigSendType" SG_ 423 HDBM_LExMirUDAdjSpd_Req 2;
BA_ "GenSigStartValue" SG_ 423 HDBM_LExMirLRAdjSpd_Req 30;
BA_ "GenSigSendType" SG_ 423 HDBM_LExMirLRAdjSpd_Req 2;
BA_ "GenSigStartValue" SG_ 423 HDBM_RExMirUDAdjSpd_Req 30;
BA_ "GenSigSendType" SG_ 423 HDBM_RExMirUDAdjSpd_Req 2;
BA_ "GenSigStartValue" SG_ 1490 HDBM_AbsoluteTimeSecond_Val 63;
BA_ "GenSigSendType" SG_ 1490 HDBM_AbsoluteTimeSecond_Val 0;
BA_ "GenSigStartValue" SG_ 1490 HDBM_AbsoluteTimeMinute_Val 63;
BA_ "GenSigSendType" SG_ 1490 HDBM_AbsoluteTimeMinute_Val 0;
BA_ "GenSigStartValue" SG_ 1490 HDBM_AbsoluteTimeHour_Val 31;
BA_ "GenSigSendType" SG_ 1490 HDBM_AbsoluteTimeHour_Val 0;
BA_ "GenSigStartValue" SG_ 1490 HDBM_AbsoluteTimeDay_Val 63;
BA_ "GenSigSendType" SG_ 1490 HDBM_AbsoluteTimeDay_Val 0;
BA_ "GenSigStartValue" SG_ 1490 HDBM_AbsoluteTimeMonth_Val 15;
BA_ "GenSigSendType" SG_ 1490 HDBM_AbsoluteTimeMonth_Val 0;
BA_ "GenSigStartValue" SG_ 1490 HDBM_AbsoluteTimeYear_Val 255;
BA_ "GenSigSendType" SG_ 1490 HDBM_AbsoluteTimeYear_Val 0;
BA_ "GenSigStartValue" SG_ 817 HDBM_RemCtrlACDuration_Req 63;
BA_ "GenSigSendType" SG_ 817 HDBM_RemCtrlACDuration_Req 2;
BA_ "GenSigSendType" SG_ 817 HDBM_RemCtrlACRevnActive_Req 2;
BA_ "GenSigSendType" SG_ 817 HDBM_RemCtrlThmlMag_Req 2;
BA_ "GenSigSendType" SG_ 817 HDBM_RemCtrlFACAuto_Req 2;
BA_ "GenSigStartValue" SG_ 817 HDBM_RemCtrlThmlMagDurn_Req 1023;
BA_ "GenSigSendType" SG_ 817 HDBM_RemCtrlThmlMagDurn_Req 2;
BA_ "GenSigSendType" SG_ 817 HDBM_RemCtrlFACDfrDef_Req 2;
BA_ "GenSigSendType" SG_ 817 HDBM_RemCtrlAirClean_Req 2;
BA_ "GenSigStartValue" SG_ 817 HDBM_RemCtrlAirCleanDurn_Req 63;
BA_ "GenSigSendType" SG_ 817 HDBM_RemCtrlAirCleanDurn_Req 2;
BA_ "GenSigSendType" SG_ 817 HDBM_FLBckupDoorCtrl_Req 2;
BA_ "GenSigSendType" SG_ 817 HDBM_FRBckupDoorCtrl_Req 2;
BA_ "GenSigSendType" SG_ 817 HDBM_RLBckupDoorCtrl_Req 2;
BA_ "GenSigSendType" SG_ 817 HDBM_RRBckupDoorCtrl_Req 2;
BA_ "GenSigSendType" SG_ 817 HDBM_Whitelistsync_Req 2;
BA_ "GenSigSendType" SG_ 817 HDBM_RollingCounter6 7;
BA_ "GenSigSendType" SG_ 817 HDBM_CheckSum6 7;
BA_ "GenSigSendType" SG_ 353 HDBM_PowertrainRestrict_Req 2;
BA_ "GenSigStartValue" SG_ 353 HDBM_ChargeCutOffSOC_Req 255;
BA_ "GenSigSendType" SG_ 353 HDBM_ChargeCutOffSOC_Req 2;
BA_ "GenSigSendType" SG_ 128 HDBM_AmLtTarget1_Req 0;
BA_ "GenSigSendType" SG_ 128 HDBM_AmLtTarget2_Req 0;
BA_ "GenSigSendType" SG_ 128 HDBM_AmLtTarget3_Req 0;
BA_ "GenSigSendType" SG_ 128 HDBM_AmLtBrt_Req 0;
BA_ "GenSigSendType" SG_ 128 HDBM_AmLtRedVal_Req 0;
BA_ "GenSigSendType" SG_ 128 HDBM_AmLtGreenVal_Req 0;
BA_ "GenSigSendType" SG_ 128 HDBM_AmLtBlueVal_Req 0;
BA_ "GenSigSendType" SG_ 128 HDBM_AmLtSpd_Req 0;
BA_ "GenSigSendType" SG_ 128 HDBM_AmLtHornClrMd_Req 0;
BA_ "GenSigSendType" SG_ 128 HDBM_AmLtHornWrkMd_Req 0;
BA_ "GenSigStartValue" SG_ 80 ZCUT_BatteryVolt_Val 4094;
BA_ "GenSigSendType" SG_ 80 ZCUT_BatteryVolt_Val 0;
BA_ "GenSigSendType" SG_ 81 ZCUT_DCCharge_St 0;
BA_ "GenSigSendType" SG_ 81 ZCUT_ACCharge_St 0;
BA_ "GenSigSendType" SG_ 81 ZCUT_CellOverTemp_St 0;
BA_ "GenSigSendType" SG_ 81 ZCUT_RLBrkLgt_St 0;
BA_ "GenSigSendType" SG_ 81 ZCUT_HighBrkLgt_St 0;
BA_ "GenSigSendType" SG_ 81 ZCUT_RRBrkLgt_St 0;
BA_ "GenSigStartValue" SG_ 81 ZCUT_State_St 1;
BA_ "GenSigSendType" SG_ 81 ZCUT_State_St 0;
BA_ "GenSigSendType" SG_ 81 ZCUT_FastChrgCnctor_St 0;
BA_ "GenSigStartValue" SG_ 81 ZCUT_Current_Val 65534;
BA_ "GenSigSendType" SG_ 81 ZCUT_Current_Val 0;
BA_ "GenSigStartValue" SG_ 81 ZCUT_SOCDisplay_Val 500;
BA_ "GenSigSendType" SG_ 81 ZCUT_SOCDisplay_Val 0;
BA_ "GenSigSendType" SG_ 81 ZCUT_FaultLevel_Err 0;
BA_ "GenSigSendType" SG_ 208 ZCUT_RLTnLgt_St 0;
BA_ "GenSigSendType" SG_ 208 ZCUT_RRTnLgt_St 0;
BA_ "GenSigSendType" SG_ 208 ZCUT_ChrgCapSW_St 0;
BA_ "GenSigSendType" SG_ 544 ZCUT_ChrgDischrgCnct_St 0;
BA_ "GenSigSendType" SG_ 544 ZCUT_TrkLtWrk_St 0;
BA_ "GenSigSendType" SG_ 544 ZCUT_RLPstnLgt_St 0;
BA_ "GenSigSendType" SG_ 544 ZCUT_RRPstnLgt_St 0;
BA_ "GenSigSendType" SG_ 544 ZCUT_RLTnLgtErr_St 0;
BA_ "GenSigSendType" SG_ 544 ZCUT_RRTnLgtErr_St 0;
BA_ "GenSigSendType" SG_ 544 ZCUT_SRLSeatOcp_St 0;
BA_ "GenSigSendType" SG_ 544 ZCUT_SRRSeatOcp_St 0;
BA_ "GenSigSendType" SG_ 544 ZCUT_SRMSeatOcp_St 0;
BA_ "GenSigSendType" SG_ 544 ZCUT_TempModuMax_Val 0;
BA_ "GenSigSendType" SG_ 544 ZCUT_TRLSeatOcp_St 0;
BA_ "GenSigSendType" SG_ 544 ZCUT_TRRSeatOcp_St 0;
BA_ "GenSigSendType" SG_ 544 ZCUT_TempModuMin_Val 0;
BA_ "GenSigStartValue" SG_ 544 ZCUT_SOCReal_Val 500;
BA_ "GenSigSendType" SG_ 544 ZCUT_SOCReal_Val 0;
BA_ "GenSigSendType" SG_ 544 ZCUT_Checksum4 7;
BA_ "GenSigSendType" SG_ 544 ZCUT_RollingCounter4 7;
BA_ "GenSigSendType" SG_ 544 ZCUT_RearMirLtWrk_St 0;
BA_ "GenSigSendType" SG_ 544 ZCUT_RLRsLgt_St 0;
BA_ "GenSigSendType" SG_ 544 ZCUT_RRRsLgt_St 0;
BA_ "GenSigStartValue" SG_ 544 ZCUT_ChrgCutOffSOCSetVal_Rsp 255;
BA_ "GenSigSendType" SG_ 544 ZCUT_ChrgCutOffSOCSetVal_Rsp 0;
BA_ "GenSigSendType" SG_ 544 ZCUT_HHchrgPileCnct_St 0;
BA_ "GenSigSendType" SG_ 544 ZCUT_TRLSeatBelt_St 0;
BA_ "GenSigSendType" SG_ 544 ZCUT_TRRSeatBelt_St 0;
BA_ "GenSigSendType" SG_ 544 ZCUT_SRLSeatBelt_St 0;
BA_ "GenSigSendType" SG_ 544 ZCUT_SRMSeatBelt_St 0;
BA_ "GenSigSendType" SG_ 544 ZCUT_SRRSeatBelt_St 0;
BA_ "GenSigSendType" SG_ 544 ZCUT_DisplayCharge_St 0;
BA_ "GenSigSendType" SG_ 548 ZCUT_HSDLVPower_St 2;
BA_ "GenSigSendType" SG_ 548 ZCUT_PERMLVPower_St 2;
BA_ "GenSigSendType" SG_ 548 ZCUT_HSDLVPower_Err 2;
BA_ "GenSigSendType" SG_ 548 ZCUT_PERMLVPower_Err 2;
BA_ "GenSigSendType" SG_ 929 ZCUT_TempModuMaxID_Dat 0;
BA_ "GenSigSendType" SG_ 929 ZCUT_TempModuMinID_Dat 0;
BA_ "GenSigSendType" SG_ 929 ZCUT_OverCharge_St 0;
BA_ "GenSigSendType" SG_ 929 ZCUT_TempProbeNum_Val 0;
BA_ "GenSigSendType" SG_ 929 ZCUT_VoltCellMaxID_Dat 0;
BA_ "GenSigSendType" SG_ 929 ZCUT_SubTempHighID_Dat 0;
BA_ "GenSigStartValue" SG_ 929 ZCUT_VoltCellMax_Val 65534;
BA_ "GenSigSendType" SG_ 929 ZCUT_VoltCellMax_Val 0;
BA_ "GenSigSendType" SG_ 929 ZCUT_SubTempLowID_Dat 0;
BA_ "GenSigSendType" SG_ 929 ZCUT_VoltCellMinID_Dat 0;
BA_ "GenSigSendType" SG_ 929 ZCUT_SubRESSNum_Val 0;
BA_ "GenSigStartValue" SG_ 929 ZCUT_VoltCellMin_Val 65534;
BA_ "GenSigSendType" SG_ 929 ZCUT_VoltCellMin_Val 0;
BA_ "GenSigSendType" SG_ 929 ZCUT_SubRESSID_Dat 0;
BA_ "GenSigSendType" SG_ 929 ZCUT_SOE_Val 0;
BA_ "GenSigSendType" SG_ 929 ZCUT_CellUnderVolt_St 0;
BA_ "GenSigSendType" SG_ 929 ZCUT_PackOverVolt_St 0;
BA_ "GenSigSendType" SG_ 929 ZCUT_PackUnderVolt_St 0;
BA_ "GenSigSendType" SG_ 929 ZCUT_CellOverVolt_St 0;
BA_ "GenSigSendType" SG_ 929 ZCUT_SOCLow_St 0;
BA_ "GenSigSendType" SG_ 929 ZCUT_SOCHigh_St 0;
BA_ "GenSigSendType" SG_ 929 ZCUT_SOCSkip_St 0;
BA_ "GenSigSendType" SG_ 929 ZCUT_Mismatch_St 0;
BA_ "GenSigSendType" SG_ 929 ZCUT_CellVoltDeviation_St 0;
BA_ "GenSigSendType" SG_ 929 ZCUT_CellTempDeviation_St 0;
BA_ "GenSigSendType" SG_ 929 ZCUT_BatVolHighID_Dat 0;
BA_ "GenSigSendType" SG_ 929 ZCUT_BatVolLowID_Dat 0;
BA_ "GenSigSendType" SG_ 82 PCU_DCDCMode_St 0;
BA_ "GenSigSendType" SG_ 209 PCU_OBCACChrgCnctor_St 0;
BA_ "GenSigStartValue" SG_ 402 CCM_ChrgCapPst_St 255;
BA_ "GenSigSendType" SG_ 402 CCM_ChrgCapPst_St 0;
BA_ "GenSigSendType" SG_ 402 CCM_ChrgCapMv_St 0;
BA_ "GenSigStartValue" SG_ 402 ZCUT_FD_RT_1_CCMAvailable_St 1;
BA_ "GenSigSendType" SG_ 402 ZCUT_FD_RT_1_CCMAvailable_St 0;
BA_ "GenSigSendType" SG_ 402 CCM_ChrgCapLearn_St 0;
BA_ "GenSigSendType" SG_ 402 CCM_ChrgCapStpRsn_St 0;
BA_ "GenSigSendType" SG_ 402 CCM_ChrgCapStp_Req 0;
BA_ "GenSigSendType" SG_ 1105 ZCUT_NodeAddress_VB1 0;
BA_ "GenSigSendType" SG_ 1105 ZCUT_RepeatMsgReq_VB1 0;
BA_ "GenSigSendType" SG_ 1105 ZCUT_ActiveWakeup_VB1 0;
BA_ "GenSigSendType" SG_ 1105 ZCUT_PartialNetworkInfo_VB1 0;
BA_ "GenSigSendType" SG_ 1105 ZCUT_RepeatMsgSt_VB1 0;
BA_ "GenSigSendType" SG_ 1105 ZCUT_PN_HDBT_VB1 0;
BA_ "GenSigSendType" SG_ 1105 ZCUT_PN_HDBI_VB1 0;
BA_ "GenSigSendType" SG_ 1105 ZCUT_PN_HDBA_VB1 0;
BA_ "GenSigSendType" SG_ 1105 ZCUT_PN_HDBM_VB1 0;
BA_ "GenSigSendType" SG_ 1105 ZCUT_PN_ZCUF_VB1 0;
BA_ "GenSigSendType" SG_ 1105 ZCUT_PN_ZCUL_VB1 0;
BA_ "GenSigSendType" SG_ 1105 ZCUT_PN_ZCUR_VB1 0;
BA_ "GenSigSendType" SG_ 1105 ZCUT_PN_ZCUT_VB1 0;
BA_ "GenSigSendType" SG_ 1413 ZCUT_WakeupReq_HDBT 2;
BA_ "GenSigSendType" SG_ 1413 ZCUT_WakeupReq_HDBI 2;
BA_ "GenSigSendType" SG_ 1413 ZCUT_WakeupReq_HDBA 2;
BA_ "GenSigSendType" SG_ 1413 ZCUT_WakeupReq_HDBM 2;
BA_ "GenSigSendType" SG_ 1413 ZCUT_WakeupReq_ZCUF 2;
BA_ "GenSigSendType" SG_ 1413 ZCUT_WakeupReq_ZCUL 2;
BA_ "GenSigSendType" SG_ 1413 ZCUT_WakeupReq_ZCUR 2;
BA_ "GenSigSendType" SG_ 1413 ZCUT_WakeupReq_ZCUT 2;
BA_ "GenSigSendType" SG_ 1492 ZCUT_VB1_NetworkReqCondition0 0;
BA_ "GenSigSendType" SG_ 1492 ZCUT_VB1_NetworkReqCondition1 0;
BA_ "GenSigSendType" SG_ 1492 ZCUT_VB1_NetworkReqCondition2 0;
BA_ "GenSigSendType" SG_ 1492 ZCUT_VB1_NetworkReqCondition3 0;
BA_ "GenSigSendType" SG_ 1492 ZCUT_VB1_NetworkReqCondition4 0;
BA_ "GenSigSendType" SG_ 1492 ZCUT_VB1_NetworkReqCondition5 0;
BA_ "GenSigSendType" SG_ 1492 ZCUT_VB1_NetworkReqCondition6 0;
BA_ "GenSigSendType" SG_ 1492 ZCUT_VB1_NetworkReqCondition7 0;
BA_ "GenSigSendType" SG_ 1492 ZCUT_VB1_NetworkReqCondition8 0;
BA_ "GenSigSendType" SG_ 1492 ZCUT_VB1_NetworkReqCondition9 0;
BA_ "GenSigSendType" SG_ 1492 ZCUT_VB1_NetworkReqCondition10 0;
BA_ "GenSigSendType" SG_ 1492 ZCUT_VB1_NetworkReqCondition11 0;
BA_ "GenSigSendType" SG_ 1492 ZCUT_VB1_NetworkReqCondition12 0;
BA_ "GenSigSendType" SG_ 1492 ZCUT_VB1_NetworkReqCondition13 0;
BA_ "GenSigSendType" SG_ 1492 ZCUT_VB1_NetworkReqCondition14 0;
BA_ "GenSigSendType" SG_ 1492 ZCUT_VB1_NetworkReqCondition15 0;
BA_ "GenSigSendType" SG_ 1492 ZCUT_VB1_NetworkReqCondition16 0;
BA_ "GenSigSendType" SG_ 1492 ZCUT_VB1_NetworkReqCondition17 0;
BA_ "GenSigSendType" SG_ 1492 ZCUT_VB1_NetworkReqCondition18 0;
BA_ "GenSigSendType" SG_ 1492 ZCUT_VB1_NetworkReqCondition19 0;
BA_ "GenSigSendType" SG_ 1492 ZCUT_VB1_NetworkReqCondition20 0;
BA_ "GenSigSendType" SG_ 1492 ZCUT_VB1_NetworkReqCondition21 0;
BA_ "GenSigSendType" SG_ 1492 ZCUT_VB1_NetworkReqCondition22 0;
BA_ "GenSigSendType" SG_ 1492 ZCUT_VB1_NetworkReqCondition23 0;
BA_ "GenSigSendType" SG_ 1492 ZCUT_VB1_NetworkReqCondition24 0;
BA_ "GenSigSendType" SG_ 1492 ZCUT_VB1_NetworkReqCondition25 0;
BA_ "GenSigSendType" SG_ 1492 ZCUT_VB1_NetworkReqCondition26 0;
BA_ "GenSigSendType" SG_ 1492 ZCUT_VB1_NetworkReqCondition27 0;
BA_ "GenSigSendType" SG_ 1492 ZCUT_VB1_NetworkReqCondition28 0;
BA_ "GenSigSendType" SG_ 1492 ZCUT_VB1_NetworkReqCondition29 0;
BA_ "GenSigSendType" SG_ 1492 ZCUT_VB1_NetworkReqCondition30 0;
BA_ "GenSigSendType" SG_ 1492 ZCUT_VB1_NetworkReqCondition31 0;
BA_ "GenSigSendType" SG_ 546 PCU_OBCACSocketLock_St 2;
BA_ "GenSigSendType" SG_ 1328 PLGM_TLthNeutral_St 2;
BA_ "GenSigSendType" SG_ 1328 PLGM_TLthHlfLck_St 2;
BA_ "GenSigSendType" SG_ 1328 PLGM_TLthAjar_St 2;
BA_ "GenSigSendType" SG_ 1328 PLGM_TDrWrk_St 2;
BA_ "GenSigStartValue" SG_ 1328 PLGM_TDrTripPst_Val 255;
BA_ "GenSigSendType" SG_ 1328 PLGM_TDrTripPst_Val 2;
BA_ "GenSigSendType" SG_ 1328 PLGM_TDrTchpadSW_St 2;
BA_ "GenSigSendType" SG_ 1328 PLGM_TDrStpRsn_St 2;
BA_ "GenSigSendType" SG_ 1328 PLGM_TDrLthWrk_St 2;
BA_ "GenSigSendType" SG_ 1328 PLGM_TDrLth_St 2;
BA_ "GenSigSendType" SG_ 1328 PLGM_TDrLth_Err 2;
BA_ "GenSigSendType" SG_ 1328 PLGM_TDrIntSW_St 2;
BA_ "GenSigSendType" SG_ 1328 PLGM_SpdlStallEvt_St 2;
BA_ "GenSigSendType" SG_ 1328 PLGM_PinchEvt_St 2;
BA_ "GenSigSendType" SG_ 1328 PLGM_Followup_Req 2;
BA_ "GenSigSendType" SG_ 1328 PLGM_TDrLSpdl_Err 2;
BA_ "GenSigSendType" SG_ 1328 PLGM_TDrRSpdl_Err 2;
BA_ "GenSigSendType" SG_ 1328 PLGM_InitLearn_St 2;
BA_ "GenSigSendType" SG_ 1328 PLGM_MaxPstLn_St 2;
BA_ "GenSigSendType" SG_ 897 ZCUT_ChargeHVPower_Val 0;
BA_ "GenSigSendType" SG_ 897 ZCUT_RemainChrgTime_Val 0;
BA_ "GenSigSendType" SG_ 897 ZCUT_SRRSeatVtlt_Rsp 0;
BA_ "GenSigSendType" SG_ 897 ZCUT_SRRSeatVtltStpRsn_St 0;
BA_ "GenSigSendType" SG_ 897 ZCUT_SRLSeatHt_Rsp 0;
BA_ "GenSigSendType" SG_ 897 ZCUT_SRLSeatHtStpRsn_St 0;
BA_ "GenSigSendType" SG_ 897 ZCUT_SRLSeatVtlt_Rsp 0;
BA_ "GenSigSendType" SG_ 897 ZCUT_SRLSeatVtltStpRsn_St 0;
BA_ "GenSigSendType" SG_ 897 ZCUT_SRRSeatHt_Rsp 0;
BA_ "GenSigSendType" SG_ 897 ZCUT_SRRSeatHtStpRsn_St 0;
BA_ "GenSigSendType" SG_ 1454 ZCUT_BattSerialNum_Dat 0;
BA_ "GenSigSendType" SG_ 1454 ZCUT_BattManuYear_Val 0;
BA_ "GenSigStartValue" SG_ 1454 ZCUT_BattManuMonth_Val 1;
BA_ "GenSigSendType" SG_ 1454 ZCUT_BattManuMonth_Val 0;
BA_ "GenSigStartValue" SG_ 1454 ZCUT_BattManuDay_Val 1;
BA_ "GenSigSendType" SG_ 1454 ZCUT_BattManuDay_Val 0;
BA_ "GenSigSendType" SG_ 1454 ZCUT_PackageTotalNum_Val 0;
BA_ "GenSigSendType" SG_ 1454 ZCUT_CellTotalNum_Val 0;
BA_ "GenSigSendType" SG_ 256 ZCUR_FRHdlOprt_St 0;
BA_ "GenSigSendType" SG_ 256 ZCUR_RRHdlOprt_St 0;
BA_ "GenSigSendType" SG_ 256 ZCUR_FRDrIntSW_St 0;
BA_ "GenSigSendType" SG_ 256 ZCUR_RRDrIntSW_St 0;
BA_ "GenSigSendType" SG_ 256 ZCUR_SFRTnLt_St 0;
BA_ "GenSigSendType" SG_ 256 ZCUR_Checksum1 7;
BA_ "GenSigSendType" SG_ 256 ZCUR_RollingCounter1 7;
BA_ "GenSigSendType" SG_ 256 ZCUR_FRSeatOcp_St 0;
BA_ "GenSigSendType" SG_ 256 ZCUR_FRWinPst_Rsp 0;
BA_ "GenSigSendType" SG_ 256 ZCUR_RRWinPst_Rsp 0;
VAL_ 913 ZCUR_RRDrStpRsn_St 0 "inactive" 1 "expected work end" 2 "latch fault" 3 "drive time out" 4 "heat protect" 5 "command conflict" 6 "stall occured" 7 "manual release" 8 "reserved" 9 "reserved" 10 "reserved" 11 "reserved" 12 "reserved" 13 "reserved" 14 "reserved" 15 "reserved" ;
VAL_ 913 ZCUR_FRDrLth_Err 0 "normal" 1 "short to battery" 2 "short to ground" 3 "open load" 4 "reserved" 5 "reserved" 6 "reserved" 7 "reserved" ;
VAL_ 913 ZCUR_RExMirCtrl_Rsp 0 "unfold" 1 "fold" ;
VAL_ 913 ZCUR_RRDrLth_Err 0 "normal" 1 "short to battery" 2 "short to ground" 3 "open load" 4 "reserved" 5 "reserved" 6 "reserved" 7 "reserved" ;
VAL_ 913 ZCUR_FRSeatAdj_Req 0 "No Request" 1 "Front" 2 "Rear" 3 "Invalid" ;
VAL_ 913 ZCUR_FRSeatBackrestAdj_Req 0 "No Request" 1 "Front" 2 "Rear" 3 "Invalid" ;
VAL_ 913 ZCUR_SFRTnLtErr_St 0 "No Error" 1 "Error" ;
VAL_ 913 ZCUR_FRSeatHgtAdj_Req 0 "No Request" 1 "Up" 2 "Down" 3 "Invalid" ;
VAL_ 913 ZCUR_FRSeatCshnAngAdj_Req 0 "No Request" 1 "Up" 2 "Down" 3 "Invalid" ;
VAL_ 913 ZCUR_FRHdlFrz_St 0 "freeze not occur" 1 "freeze occur" ;
VAL_ 913 ZCUR_FRWdwSw_St 0 "No Request" 1 "Manual Up" 2 "Manual Down" 3 "Auto Up" 4 "Auto Down" 5 "Reserved" 6 "Reserved" 7 "Invalid" ;
VAL_ 913 ZCUR_FRWdwMov_St 0 "stop" 1 "closing" 2 "opening" 3 "invalid" ;
VAL_ 913 ZCUR_RRWdwMov_St 0 "stop" 1 "closing" 2 "opening" 3 "invalid" ;
VAL_ 913 ZCUR_FRHdlStpRsn_St 0 "inactive" 1 "move to open position" 2 "pinch occuered" 3 "break freeze fail" 4 "handle fault" 5 "drive time out" 6 "heat protected" 7 "power status abnormal" 8 "command conflict" 9 "move to close position" 10 "reserved" 11 "reserved" 12 "reserved" 13 "reserved" 14 "reserved" 15 "reserved" ;
VAL_ 913 ZCUR_RRHdlStpRsn_St 0 "inactive" 1 "move to open position" 2 "pinch occuered" 3 "break freeze fail" 4 "handle fault" 5 "drive time out" 6 "heat protected" 7 "power status abnormal" 8 "command conflict" 9 "move to close position" 10 "reserved" 11 "reserved" 12 "reserved" 13 "reserved" 14 "reserved" 15 "reserved" ;
VAL_ 913 ZCUR_FRLthAjar_St 0 "off" 1 "on" ;
VAL_ 913 ZCUR_RRLthAjar_St 0 "off" 1 "on" ;
VAL_ 913 ZCUR_FRLthHlfLck_St 0 "off" 1 "on" ;
VAL_ 913 ZCUR_RRLthHlfLck_St 0 "off" 1 "on" ;
VAL_ 913 ZCUR_FRLthPawl_St 0 "off" 1 "on" ;
VAL_ 913 ZCUR_RRLthPawl_St 0 "off" 1 "on" ;
VAL_ 913 ZCUR_FRLthHome_St 0 "off" 1 "on" ;
VAL_ 913 ZCUR_RRLthHome_St 0 "off" 1 "on" ;
VAL_ 913 ZCUR_FRDrLth_St 0 "unlatched" 1 "half latched" 2 "full latched" 3 "medium" 4 "reserved" 5 "reserved" 6 "reserved" 7 "reserved" ;
VAL_ 913 ZCUR_FRHdlClsPstSW_St 0 "off" 1 "on" ;
VAL_ 913 ZCUR_RRDrLth_St 0 "unlatched" 1 "half latched" 2 "full latched" 3 "medium" 4 "reserved" 5 "reserved" 6 "reserved" 7 "reserved" ;
VAL_ 913 ZCUR_RRHdlClsPstSW_St 0 "off" 1 "on" ;
VAL_ 913 ZCUR_FRDrLthWrk_St 0 "stop" 1 "cinching" 2 "releasing" 3 "resuming after cinch" 4 "resuming after release" 5 "initialing" 6 "brake" 7 "reserved" ;
VAL_ 913 ZCUR_FRHdlOpnPstSW_St 0 "off" 1 "on" ;
VAL_ 913 ZCUR_RRDrLthWrk_St 0 "stop" 1 "cinching" 2 "releasing" 3 "resuming after cinch" 4 "resuming after release" 5 "initialing" 6 "brake" 7 "reserved" ;
VAL_ 913 ZCUR_RRHdlOpnPstSW_St 0 "off" 1 "on" ;
VAL_ 913 ZCUR_FRDrStpRsn_St 0 "inactive" 1 "expected work end" 2 "latch fault" 3 "drive time out" 4 "heat protect" 5 "command conflict" 6 "stall occured" 7 "manual release" 8 "reserved" 9 "reserved" 10 "reserved" 11 "reserved" 12 "reserved" 13 "reserved" 14 "reserved" 15 "reserved" ;
VAL_ 913 ZCUR_RRHdlFrz_St 0 "freeze not occur" 1 "freeze occur" ;
VAL_ 913 ZCUR_FRSeatLegAngCshnExtAdj_Req 0 "No Request" 1 "Up" 2 "Down" 3 "Invalid" ;
VAL_ 913 ZCUR_RRWdwSw_St 0 "No Request" 1 "Manual Up" 2 "Manual Down" 3 "Auto Up" 4 "Auto Down" 5 "Reserved" 6 "Reserved" 7 "Invalid" ;
VAL_ 913 ZCUR_RRDrStpRsn2_St 0 "inactive" 1 "expected work end" 2 "latch fault" 3 "drive time out" 4 "heat protect" 5 "command conflict" 6 "stall occured" 7 "manual release" 8 "reserved" 9 "reserved" 10 "reserved" 11 "reserved" 12 "reserved" 13 "reserved" 14 "reserved" 15 "reserved" ;
VAL_ 913 ZCUR_FRDrStpRsn2_St 0 "inactive" 1 "expected work end" 2 "latch fault" 3 "drive time out" 4 "heat protect" 5 "command conflict" 6 "stall occured" 7 "manual release" 8 "reserved" 9 "reserved" 10 "reserved" 11 "reserved" 12 "reserved" 13 "reserved" 14 "reserved" 15 "reserved" ;
VAL_ 913 ZCUR_RRDrLthWrk2_St 0 "stop" 1 "cinching" 2 "releasing" 3 "resuming after cinch" 4 "resuming after release" 5 "initialing" 6 "brake" 7 "reserved" ;
VAL_ 913 ZCUR_FRDrLthWrk2_St 0 "stop" 1 "cinching" 2 "releasing" 3 "resuming after cinch" 4 "resuming after release" 5 "initialing" 6 "brake" 7 "reserved" ;
VAL_ 913 ZCUR_FRSunshadeSW_St 0 "closed" 1 "opened" ;
VAL_ 913 ZCUR_FRLumbSuppFBAdj_Req 0 "No Request" 1 "Front" 2 "Back" 3 "Invalid" ;
VAL_ 913 ZCUR_FRLumbSuppUDAdj_Req 0 "No Request" 1 "Up" 2 "Down" 3 "Invalid" ;
VAL_ 913 ZCUR_FRDrLth2_Err 0 "normal" 1 "short to battery" 2 "short to ground" 3 "open load" 4 "reserved" 5 "reserved" 6 "reserved" 7 "reserved" ;
VAL_ 913 ZCUR_RRDrLth2_Err 0 "normal" 1 "short to battery" 2 "short to ground" 3 "open load" 4 "reserved" 5 "reserved" 6 "reserved" 7 "reserved" ;
VAL_ 913 ZCUR_RExMirLRMv_St 0 "Stop" 1 "Left" 2 "Right" 3 "Invalid" ;
VAL_ 913 ZCUR_RExMirUDStpRsn_St 0 "Default" 1 "Stop Command" 2 "Open Circuit" 3 "Short Circuit" 4 "Stall occurred" 5 "Over Current" 6 "Drive Timeout" 7 "reserved" 8 "reserved" 9 "reserved" 10 "reserved" 11 "reserved" 12 "reserved" 13 "reserved" 14 "reserved" 15 "reserved" ;
VAL_ 913 ZCUR_RExMirUDStp_Req 0 "No Request" 1 "Heat Protect" 2 "Over Voltage" 3 "Under Voltage" 4 "Reserved" 5 "Reserved" 6 "Reserved" 7 "Reserved" ;
VAL_ 913 ZCUR_RExMirLRStpRsn_St 0 "Default" 1 "Stop Command" 2 "Open Circuit" 3 "Short Circuit" 4 "Stall occurred" 5 "Over Current" 6 "Drive Timeout" 7 "reserved" 8 "reserved" 9 "reserved" 10 "reserved" 11 "reserved" 12 "reserved" 13 "reserved" 14 "reserved" 15 "reserved" ;
VAL_ 913 ZCUR_RExMirLRStp_Req 0 "No Request" 1 "Heat Protect" 2 "Over Voltage" 3 "Under Voltage" 4 "Reserved" 5 "Reserved" 6 "Reserved" 7 "Reserved" ;
VAL_ 913 ZCUR_RExMirUDMv_St 0 "Stop" 1 "Up" 2 "Down" 3 "Invalid" ;
VAL_ 913 ZCUR_FRSeatFBMv_St 0 "Stop" 1 "Front" 2 "Rear" 3 "Invalid" ;
VAL_ 913 ZCUR_FRSeatBackrestMv_St 0 "Stop" 1 "Front" 2 "Rear" 3 "Invalid" ;
VAL_ 913 ZCUR_FRSeatHgtMv_St 0 "Stop" 1 "Up" 2 "Down" 3 "Invalid" ;
VAL_ 913 ZCUR_FRSeatCshnAngMv_St 0 "Stop" 1 "Up" 2 "Down" 3 "Invalid" ;
VAL_ 913 ZCUR_FRLegAngCshnExtMv_St 0 "Stop" 1 "Up" 2 "Down" 3 "Invalid" ;
VAL_ 913 ZCUR_FRSeatFBStpRsn_St 0 "Default" 1 "Stop Command" 2 "Open Circuit" 3 "Short Circuit" 4 "Stall occurred" 5 "Over Current" 6 "Drive Timeout" 7 "Anti-pinch" 8 "Hall Fault" 9 "reserved" 10 "reserved" 11 "reserved" 12 "reserved" 13 "reserved" 14 "reserved" 15 "reserved" ;
VAL_ 913 ZCUR_FRSeatFBStp_Req 0 "No Request" 1 "Heat Protect" 2 "Over Voltage" 3 "Under Voltage" 4 "Reserved" 5 "Reserved" 6 "Reserved" 7 "Reserved" ;
VAL_ 913 ZCUR_FRLegAngCshnExtStp_Req 0 "No Request" 1 "Heat Protect" 2 "Over Voltage" 3 "Under Voltage" 4 "Reserved" 5 "Reserved" 6 "Reserved" 7 "Reserved" ;
VAL_ 913 ZCUR_FRSeatBackrestStpRsn_St 0 "Default" 1 "Stop Command" 2 "Open Circuit" 3 "Short Circuit" 4 "Stall occurred" 5 "Over Current" 6 "Drive Timeout" 7 "Anti-pinch" 8 "Hall Fault" 9 "reserved" 10 "reserved" 11 "reserved" 12 "reserved" 13 "reserved" 14 "reserved" 15 "reserved" ;
VAL_ 913 ZCUR_FRSeatBackrestStp_Req 0 "No Request" 1 "Heat Protect" 2 "Over Voltage" 3 "Under Voltage" 4 "Reserved" 5 "Reserved" 6 "Reserved" 7 "Reserved" ;
VAL_ 913 ZCUR_FRSeatHgtStpRsn_St 0 "Default" 1 "Stop Command" 2 "Open Circuit" 3 "Short Circuit" 4 "Stall occurred" 5 "Over Current" 6 "Drive Timeout" 7 "Reserved" 8 "Hall Fault" 9 "reserved" 10 "reserved" 11 "reserved" 12 "reserved" 13 "reserved" 14 "reserved" 15 "reserved" ;
VAL_ 913 ZCUR_FRSeatHgtStp_Req 0 "No Request" 1 "Heat Protect" 2 "Over Voltage" 3 "Under Voltage" 4 "Reserved" 5 "Reserved" 6 "Reserved" 7 "Reserved" ;
VAL_ 913 ZCUR_FRSeatCshnAngStpRsn_St 0 "Default" 1 "Stop Command" 2 "Open Circuit" 3 "Short Circuit" 4 "Stall occurred" 5 "Over Current" 6 "Drive Timeout" 7 "Reserved" 8 "Hall Fault" 9 "reserved" 10 "reserved" 11 "reserved" 12 "reserved" 13 "reserved" 14 "reserved" 15 "reserved" ;
VAL_ 913 ZCUR_FRSeatCshnAngStp_Req 0 "No Request" 1 "Heat Protect" 2 "Over Voltage" 3 "Under Voltage" 4 "Reserved" 5 "Reserved" 6 "Reserved" 7 "Reserved" ;
VAL_ 913 ZCUR_FRLegAngCshnExtStpRsn_St 0 "Default" 1 "Stop Command" 2 "Open Circuit" 3 "Short Circuit" 4 "Stall occurred" 5 "Over Current" 6 "Drive Timeout" 7 "Reserved" 8 "Hall Fault" 9 "reserved" 10 "reserved" 11 "reserved" 12 "reserved" 13 "reserved" 14 "reserved" 15 "reserved" ;
VAL_ 913 ZCUR_FRHdlDbOprt_St 0 "not double operate" 1 "double operate" 2 "reserved" 3 "invalid" ;
VAL_ 913 ZCUR_RRHdlDbOprt_St 0 "not double operate" 1 "double operate" 2 "reserved" 3 "invalid" ;
VAL_ 913 ZCUR_RExMirCtrlStp_Req 0 "No Request" 1 "Heat Protect" 2 "Over Voltage" 3 "Under Voltage" 4 "Reserved" 5 "Reserved" 6 "Reserved" 7 "Reserved" ;
VAL_ 913 ZCUR_RExMirCtrlMv_St 0 "Stop" 1 "Unfold" 2 "Fold" 3 "Reserved" ;
VAL_ 913 ZCUR_RExMirCtrlStpRsn_St 0 "Default" 1 "Stop Command" 2 "Open Circuit" 3 "Short Circuit" 4 "Stall occurred" 5 "Over Current" 6 "Drive Timeout" 7 "reserved" 8 "reserved" 9 "reserved" 10 "reserved" 11 "reserved" 12 "reserved" 13 "reserved" 14 "reserved" 15 "reserved" ;
VAL_ 913 ZCUR_FRSeatBelt_St 0 "Not Tied" 1 "Tied" ;
VAL_ 96 ZCUF_ActlGearVaild_St 0 "Invalid" 1 "Valid" ;
VAL_ 96 ZCUF_ActlGear_St 0 "P" 1 "R" 2 "N" 3 "D" 4 "Reserved" 5 "Reserved" 6 "Reserved" 7 "Reserved" ;
VAL_ 96 ZCUF_VehicleSpeed_Val 8191 "Invalid" ;
VAL_ 96 ZCUF_VehicleSpeedValid_St 0 "Invalid" 1 "Valid" ;
VAL_ 96 ZCUF_FLTnLgt_St 0 "OFF" 1 "ON" ;
VAL_ 96 ZCUF_FRTnLgt_St 0 "OFF" 1 "ON" ;
VAL_ 96 ZCUF_LimpHomeRmnd_St 0 "Normal" 1 "Limp Home" ;
VAL_ 352 HDBI_LowSpdVoi_Req 0 "No Request" 1 "off" 2 "on" 3 "invalid" ;
VAL_ 352 HDBI_LowSpdVoiTyp_Req 0 "No Request" 1 "Type1" 2 "Type2" 3 "Type3" 4 "Reserved" 5 "Reserved" 6 "Reserved" 7 "Invalid" ;
VAL_ 352 HDBI_NFCLockUnlock_Req 0 "No request;" 1 "Unlock;" 2 "Lock;" 3 "Reserved;" ;
VAL_ 352 HDBI_RLDoorBtn_Req 0 "no request" 1 "close" 2 "open" 3 "reserved" ;
VAL_ 352 HDBI_RearFogBm_Req 0 "No Request" 1 "OFF" 2 "ON" 3 "invalid" ;
VAL_ 352 HDBI_EtnlLgt_Req 0 "No Request" 1 "Postion" 2 "Low Beam" 3 "Auto" 4 "OFF" 5 "Reserved" 6 "Reserved" 7 "Invalid" ;
VAL_ 272 HDBM_FLDoor_St 0 "close" 1 "open" 2 "reserved" 3 "Invalid" ;
VAL_ 272 HDBM_LeftTurnLgt_Req 0 "Off" 1 "On" ;
VAL_ 272 HDBM_RgtTurnLgt_Req 0 "Off" 1 "On" ;
VAL_ 272 HDBM_PowerMode_St 0 "OFF" 1 "Parked" 2 "Comfort" 3 "Driving" 7 "Invalid" ;
VAL_ 272 HDBM_FRDoor_St 0 "Close" 1 "Open" 2 "Reserved" 3 "Invalid" ;
VAL_ 272 HDBM_RLDoor_St 0 "Close" 1 "Open" 2 "Reserved" 3 "Invalid" ;
VAL_ 272 HDBM_RRDoor_St 0 "Close" 1 "Open" 2 "Reserved" 3 "Invalid" ;
VAL_ 272 HDBM_TargCoastRegen_Req 255 "Invalid" ;
VAL_ 272 HDBM_DMSPTModeChg_Req 0 "Standard" 1 "Comfort" 2 "Sport" 3 "LowConsum" 4 "Winter" 5 "One Pedal" 6 "Reserved" 7 "Reserved" 8 "Reserved" 9 "Reserved" 10 "Reserved" 11 "Reserved" 12 "Reserved" 13 "Reserved" 14 "Reserved" 15 "Invalid" ;
VAL_ 272 HDBM_DMSEPSModeChg_Req 0 "Heavy" 1 "Mid" 2 "Light" 3 "Reserved" 4 "Reserved" 5 "Reserved" 6 "Reserved" 7 "Invalid" ;
VAL_ 272 HDBM_DMSESCModeChg_Req 0 "Standard" 1 "Comfort" 2 "Sport" 3 "One Pedal" 4 "winter" 5 "Reserved" 6 "Reserved" 7 "Reserved" 8 "Reserved" 9 "Reserved" 10 "Reserved" 11 "Reserved" 12 "Reserved" 13 "Reserved" 14 "Reserved" 15 "Invalid" ;
VAL_ 272 HDBM_ChrgCap_St 0 "close" 1 "open" 2 "reserved" 3 "Invalid" ;
VAL_ 689 HDBM_TCMACSOV_Req 0 "Default" 1 "Close" 2 "Open" 3 "Reserved" ;
VAL_ 689 HDBM_TCMHPLowPressSOV_Req 0 "Default" 1 "Close" 2 "Open" 3 "Reserved" ;
VAL_ 689 HDBM_TCMHPHighPressSOV_Req 0 "Default" 1 "Close" 2 "Open" 3 "Reserved" ;
VAL_ 689 HDBM_HEXVInit_Req 0 "No  requested" 1 "Requested" ;
VAL_ 689 HDBM_CHVHTrgtPwr_Req 0 "PowerLimited" 1 "PowerLimited" 2 "PowerLimited" 3 "PowerLimited" 4 "PowerLimited" 5 "PowerLimited" 6 "PowerLimited" 7 "PowerLimited" 8 "PowerLimited" 9 "PowerLimited" 10 "PowerLimited" 11 "PowerLimited" 12 "PowerLimited" 13 "PowerLimited" 14 "PowerLimited" 15 "PowerLimited" 16 "PowerLimited" 17 "PowerLimited" 18 "PowerLimited" 19 "PowerLimited" 20 "PowerLimited" 21 "PowerLimited" 22 "PowerLimited" 23 "PowerLimited" 24 "PowerLimited" 25 "PowerLimited" 26 "PowerLimited" 27 "PowerLimited" 28 "PowerLimited" 29 "PowerLimited" 30 "PowerLimited" 31 "PowerLimited" 32 "PowerLimited" 33 "PowerLimited" 34 "PowerLimited" 35 "PowerLimited" 36 "PowerLimited" 37 "PowerLimited" 38 "PowerLimited" 39 "PowerLimited" 40 "PowerLimited" 41 "PowerLimited" 42 "PowerLimited" 43 "PowerLimited" 44 "PowerLimited" 45 "PowerLimited" 46 "PowerLimited" 47 "PowerLimited" 48 "PowerLimited" 49 "PowerLimited" 50 "PowerLimited" 51 "PowerLimited" 52 "PowerLimited" 53 "PowerLimited" 54 "PowerLimited" 55 "PowerLimited" 56 "PowerLimited" 57 "PowerLimited" 58 "PowerLimited" 59 "PowerLimited" 60 "PowerLimited" 61 "PowerLimited" 62 "PowerLimited" 63 "PowerLimited" 64 "PowerLimited" 65 "PowerLimited" 66 "PowerLimited" 67 "PowerLimited" 68 "PowerLimited" 69 "PowerLimited" 70 "PowerLimited" 71 "PowerLimited" 72 "PowerLimited" 73 "PowerLimited" 74 "PowerLimited" 75 "PowerLimited" 76 "PowerLimited" 77 "PowerLimited" 78 "PowerLimited" 79 "PowerLimited" 80 "PowerLimited" 81 "PowerLimited" 82 "PowerLimited" 83 "PowerLimited" 84 "PowerLimited" 85 "PowerLimited" 86 "PowerLimited" 87 "PowerLimited" 88 "PowerLimited" 89 "PowerLimited" 90 "PowerLimited" 91 "PowerLimited" 92 "PowerLimited" 93 "PowerLimited" 94 "PowerLimited" 95 "PowerLimited" 96 "PowerLimited" 97 "PowerLimited" 98 "PowerLimited" 99 "PowerLimited" 100 "PowerLimited" 101 "PowerLimited" 102 "PowerLimited" 103 "PowerLimited" 104 "PowerLimited" 105 "PowerLimited" 106 "PowerLimited" 107 "PowerLimited" 108 "PowerLimited" 109 "PowerLimited" 110 "PowerLimited" 111 "PowerLimited" 112 "PowerLimited" 113 "PowerLimited" 114 "PowerLimited" 115 "PowerLimited" 116 "PowerLimited" 117 "PowerLimited" 118 "PowerLimited" 119 "PowerLimited" 120 "PowerLimited" 121 "PowerLimited" 122 "PowerLimited" 123 "PowerLimited" 124 "PowerLimited" 125 "PowerLimited" 126 "PowerLimited" 127 "PowerLimited" 128 "PowerLimited" 129 "PowerLimited" 130 "PowerLimited" 131 "PowerLimited" 132 "PowerLimited" 133 "PowerLimited" 134 "PowerLimited" 135 "PowerLimited" 136 "PowerLimited" 137 "PowerLimited" 138 "PowerLimited" 139 "PowerLimited" 140 "PowerLimited" 141 "PowerLimited" 142 "PowerLimited" 143 "PowerLimited" 144 "PowerLimited" 145 "PowerLimited" 146 "PowerLimited" 147 "PowerLimited" 148 "PowerLimited" 149 "PowerLimited" 150 "PowerLimited" 151 "PowerLimited" 152 "PowerLimited" 153 "PowerLimited" 154 "PowerLimited" 155 "PowerLimited" 156 "PowerLimited" 157 "PowerLimited" 158 "PowerLimited" 159 "PowerLimited" 160 "PowerLimited" 161 "PowerLimited" 162 "PowerLimited" 163 "PowerLimited" 164 "PowerLimited" 165 "PowerLimited" 166 "PowerLimited" 167 "PowerLimited" 168 "PowerLimited" 169 "PowerLimited" 170 "PowerLimited" 171 "PowerLimited" 172 "PowerLimited" 173 "PowerLimited" 174 "PowerLimited" 175 "PowerLimited" 176 "PowerLimited" 177 "PowerLimited" 178 "PowerLimited" 179 "PowerLimited" 180 "PowerLimited" 181 "PowerLimited" 182 "PowerLimited" 183 "PowerLimited" 184 "PowerLimited" 185 "PowerLimited" 186 "PowerLimited" 187 "PowerLimited" 188 "PowerLimited" 189 "PowerLimited" 190 "PowerLimited" 191 "PowerLimited" 192 "PowerLimited" 193 "PowerLimited" 194 "PowerLimited" 195 "PowerLimited" 196 "PowerLimited" 197 "PowerLimited" 198 "PowerLimited" 199 "PowerLimited" 200 "PowerLimited" 201 "PowerLimited" 202 "PowerLimited" 203 "PowerLimited" 204 "PowerLimited" 205 "PowerLimited" 206 "PowerLimited" 207 "PowerLimited" 208 "PowerLimited" 209 "PowerLimited" 210 "PowerLimited" 211 "PowerLimited" 212 "PowerLimited" 213 "PowerLimited" 214 "PowerLimited" 215 "PowerLimited" 216 "PowerLimited" 217 "PowerLimited" 218 "PowerLimited" 219 "PowerLimited" 220 "PowerLimited" 221 "PowerLimited" 222 "PowerLimited" 223 "PowerLimited" 224 "PowerLimited" 225 "PowerLimited" 226 "PowerLimited" 227 "PowerLimited" 228 "PowerLimited" 229 "PowerLimited" 230 "PowerLimited" 231 "PowerLimited" 232 "PowerLimited" 233 "PowerLimited" 234 "PowerLimited" 235 "PowerLimited" 236 "PowerLimited" 237 "PowerLimited" 238 "PowerLimited" 239 "PowerLimited" 240 "PowerLimited" 241 "PowerUnlimited" 242 "PowerUnlimited" 243 "PowerUnlimited" 244 "PowerUnlimited" 245 "PowerUnlimited" 246 "PowerUnlimited" 247 "PowerUnlimited" 248 "PowerUnlimited" 249 "PowerUnlimited" 250 "PowerUnlimited" 251 "PowerUnlimited" 252 "PowerUnlimited" 253 "PowerUnlimited" 254 "PowerUnlimited" 255 "PowerUnlimited" ;
VAL_ 689 HDBM_CHVHHvCooltHeatEn_Req 0 "Disable" 1 "Enable" ;
VAL_ 689 HDBM_V3WHeatEnb_Req 0 "No Request" 1 "Request" ;
VAL_ 689 HDBM_HeatPumpEnb_Req 0 "No Request" 1 "Request" ;
VAL_ 689 HDBM_OHXEXVMoveEn_Req 0 "Ignore Commanded Position" 1 "Move to Commanded Position" ;
VAL_ 689 HDBM_CHLEXVMoveEn_Req 0 "Ignore Commanded Position" 1 "Move to Commanded Position" ;
VAL_ 689 HDBM_OHXEXVSet_Req 0 "Position" 1 "Position" 2 "Position" 3 "Position" 4 "Position" 5 "Position" 6 "Position" 7 "Position" 8 "Position" 9 "Position" 10 "Position" 11 "Position" 12 "Position" 13 "Position" 14 "Position" 15 "Position" 16 "Position" 17 "Position" 18 "Position" 19 "Position" 20 "Position" 21 "Position" 22 "Position" 23 "Position" 24 "Position" 25 "Position" 26 "Position" 27 "Position" 28 "Position" 29 "Position" 30 "Position" 31 "Position" 32 "Position" 33 "Position" 34 "Position" 35 "Position" 36 "Position" 37 "Position" 38 "Position" 39 "Position" 40 "Position" 41 "Position" 42 "Position" 43 "Position" 44 "Position" 45 "Position" 46 "Position" 47 "Position" 48 "Position" 49 "Position" 50 "Position" 51 "Position" 52 "Position" 53 "Position" 54 "Position" 55 "Position" 56 "Position" 57 "Position" 58 "Position" 59 "Position" 60 "Position" 61 "Position" 62 "Position" 63 "Position" 64 "Position" 65 "Position" 66 "Position" 67 "Position" 68 "Position" 69 "Position" 70 "Position" 71 "Position" 72 "Position" 73 "Position" 74 "Position" 75 "Position" 76 "Position" 77 "Position" 78 "Position" 79 "Position" 80 "Position" 81 "Position" 82 "Position" 83 "Position" 84 "Position" 85 "Position" 86 "Position" 87 "Position" 88 "Position" 89 "Position" 90 "Position" 91 "Position" 92 "Position" 93 "Position" 94 "Position" 95 "Position" 96 "Position" 97 "Position" 98 "Position" 99 "Position" 100 "Position" 101 "Position" 102 "Position" 103 "Position" 104 "Position" 105 "Position" 106 "Position" 107 "Position" 108 "Position" 109 "Position" 110 "Position" 111 "Position" 112 "Position" 113 "Position" 114 "Position" 115 "Position" 116 "Position" 117 "Position" 118 "Position" 119 "Position" 120 "Position" 121 "Position" 122 "Position" 123 "Position" 124 "Position" 125 "Position" 126 "Position" 127 "Position" 128 "Position" 129 "Position" 130 "Position" 131 "Position" 132 "Position" 133 "Position" 134 "Position" 135 "Position" 136 "Position" 137 "Position" 138 "Position" 139 "Position" 140 "Position" 141 "Position" 142 "Position" 143 "Position" 144 "Position" 145 "Position" 146 "Position" 147 "Position" 148 "Position" 149 "Position" 150 "Position" 151 "Position" 152 "Position" 153 "Position" 154 "Position" 155 "Position" 156 "Position" 157 "Position" 158 "Position" 159 "Position" 160 "Position" 161 "Position" 162 "Position" 163 "Position" 164 "Position" 165 "Position" 166 "Position" 167 "Position" 168 "Position" 169 "Position" 170 "Position" 171 "Position" 172 "Position" 173 "Position" 174 "Position" 175 "Position" 176 "Position" 177 "Position" 178 "Position" 179 "Position" 180 "Position" 181 "Position" 182 "Position" 183 "Position" 184 "Position" 185 "Position" 186 "Position" 187 "Position" 188 "Position" 189 "Position" 190 "Position" 191 "Position" 192 "Position" 193 "Position" 194 "Position" 195 "Position" 196 "Position" 197 "Position" 198 "Position" 199 "Position" 200 "Position" 201 "Position" 202 "Position" 203 "Position" 204 "Position" 205 "Position" 206 "Position" 207 "Position" 208 "Position" 209 "Position" 210 "Position" 211 "Position" 212 "Position" 213 "Position" 214 "Position" 215 "Position" 216 "Position" 217 "Position" 218 "Position" 219 "Position" 220 "Position" 221 "Position" 222 "Position" 223 "Position" 224 "Position" 225 "Position" 226 "Position" 227 "Position" 228 "Position" 229 "Position" 230 "Position" 231 "Position" 232 "Position" 233 "Position" 234 "Position" 235 "Position" 236 "Position" 237 "Position" 238 "Position" 239 "Position" 240 "Position" 241 "Position" 242 "Position" 243 "Position" 244 "Position" 245 "Position" 246 "Position" 247 "Position" 248 "Position" 249 "Position" 250 "Position" 251 "Position" 252 "Position" 253 "Position" 254 "Position" 255 "Position" 256 "Position" 257 "Position" 258 "Position" 259 "Position" 260 "Position" 261 "Position" 262 "Position" 263 "Position" 264 "Position" 265 "Position" 266 "Position" 267 "Position" 268 "Position" 269 "Position" 270 "Position" 271 "Position" 272 "Position" 273 "Position" 274 "Position" 275 "Position" 276 "Position" 277 "Position" 278 "Position" 279 "Position" 280 "Position" 281 "Position" 282 "Position" 283 "Position" 284 "Position" 285 "Position" 286 "Position" 287 "Position" 288 "Position" 289 "Position" 290 "Position" 291 "Position" 292 "Position" 293 "Position" 294 "Position" 295 "Position" 296 "Position" 297 "Position" 298 "Position" 299 "Position" 300 "Position" 301 "Position" 302 "Position" 303 "Position" 304 "Position" 305 "Position" 306 "Position" 307 "Position" 308 "Position" 309 "Position" 310 "Position" 311 "Position" 312 "Position" 313 "Position" 314 "Position" 315 "Position" 316 "Position" 317 "Position" 318 "Position" 319 "Position" 320 "Position" 321 "Position" 322 "Position" 323 "Position" 324 "Position" 325 "Position" 326 "Position" 327 "Position" 328 "Position" 329 "Position" 330 "Position" 331 "Position" 332 "Position" 333 "Position" 334 "Position" 335 "Position" 336 "Position" 337 "Position" 338 "Position" 339 "Position" 340 "Position" 341 "Position" 342 "Position" 343 "Position" 344 "Position" 345 "Position" 346 "Position" 347 "Position" 348 "Position" 349 "Position" 350 "Position" 351 "Position" 352 "Position" 353 "Position" 354 "Position" 355 "Position" 356 "Position" 357 "Position" 358 "Position" 359 "Position" 360 "Position" 361 "Position" 362 "Position" 363 "Position" 364 "Position" 365 "Position" 366 "Position" 367 "Position" 368 "Position" 369 "Position" 370 "Position" 371 "Position" 372 "Position" 373 "Position" 374 "Position" 375 "Position" 376 "Position" 377 "Position" 378 "Position" 379 "Position" 380 "Position" 381 "Position" 382 "Position" 383 "Position" 384 "Position" 385 "Position" 386 "Position" 387 "Position" 388 "Position" 389 "Position" 390 "Position" 391 "Position" 392 "Position" 393 "Position" 394 "Position" 395 "Position" 396 "Position" 397 "Position" 398 "Position" 399 "Position" 400 "Position" 401 "Position" 402 "Position" 403 "Position" 404 "Position" 405 "Position" 406 "Position" 407 "Position" 408 "Position" 409 "Position" 410 "Position" 411 "Position" 412 "Position" 413 "Position" 414 "Position" 415 "Position" 416 "Position" 417 "Position" 418 "Position" 419 "Position" 420 "Position" 421 "Position" 422 "Position" 423 "Position" 424 "Position" 425 "Position" 426 "Position" 427 "Position" 428 "Position" 429 "Position" 430 "Position" 431 "Position" 432 "Position" 433 "Position" 434 "Position" 435 "Position" 436 "Position" 437 "Position" 438 "Position" 439 "Position" 440 "Position" 441 "Position" 442 "Position" 443 "Position" 444 "Position" 445 "Position" 446 "Position" 447 "Position" 448 "Position" 449 "Position" 450 "Position" 451 "Position" 452 "Position" 453 "Position" 454 "Position" 455 "Position" 456 "Position" 457 "Position" 458 "Position" 459 "Position" 460 "Position" 461 "Position" 462 "Position" 463 "Position" 464 "Position" 465 "Position" 466 "Position" 467 "Position" 468 "Position" 469 "Position" 470 "Position" 471 "Position" 472 "Position" 473 "Position" 474 "Position" 475 "Position" 476 "Position" 477 "Position" 478 "Position" 479 "Position" 480 "Position" 481 "Position" 482 "Position" 483 "Position" 484 "Position" 485 "Position" 486 "Position" 487 "Position" 488 "Position" 489 "Position" 490 "Position" 491 "Position" 492 "Position" 493 "Position" 494 "Position" 495 "Position" 496 "Position" 497 "Position" 498 "Position" 499 "Position" 500 "Position" 501 "Position" 502 "Position" 503 "Position" 504 "Position" 505 "Position" 506 "Position" 507 "Position" 508 "Position" 509 "Position" 510 "Position" 511 "Position" 512 "Position" 513 "Position" 514 "Position" 515 "Position" 516 "Position" 517 "Position" 518 "Position" 519 "Position" 520 "Position" 521 "Position" 522 "Position" 523 "Position" 524 "Position" 525 "Position" 526 "Position" 527 "Position" 528 "Position" 529 "Position" 530 "Position" 531 "Position" 532 "Position" 533 "Position" 534 "Position" 535 "Position" 536 "Position" 537 "Position" 538 "Position" 539 "Position" 540 "Position" 541 "Position" 542 "Position" 543 "Position" 544 "Position" 545 "Position" 546 "Position" 547 "Position" 548 "Position" 549 "Position" 550 "Position" 551 "Position" 552 "Position" 553 "Position" 554 "Position" 555 "Position" 556 "Position" 557 "Position" 558 "Position" 559 "Position" 560 "Position" 561 "Position" 562 "Position" 563 "Position" 564 "Position" 565 "Position" 566 "Position" 567 "Position" 568 "Position" 569 "Position" 570 "Position" 571 "Position" 572 "Position" 573 "Position" 574 "Position" 575 "Position" 576 "Position" ;
VAL_ 689 HDBM_DMSVehMode_St 0 "ECO" 1 "Comfort" 2 "Sport" 3 "Individual" 4 "winter" 5 "Reserved" 6 "Reserved" 7 "Reserved" 8 "Reserved" 9 "Reserved" 10 "Reserved" 11 "Reserved" 12 "Reserved" 13 "Reserved" 14 "Reserved" 15 "Invalid" ;
VAL_ 689 HDBM_DMSPTMode_St 0 "Standard" 1 "Comfort" 2 "Sport" 3 "Reserved" 4 "Reserved" 5 "Reserved" 6 "Reserved" 7 "Invalid" ;
VAL_ 689 HDBM_DMSEPSModeInfo_St 0 "Heavy" 1 "Mid" 2 "Light" 3 "Reserved" 4 "Reserved" 5 "Reserved" 6 "Reserved" 7 "Invalid" ;
VAL_ 689 HDBM_SRRSBR_Req 0 "Lamp Off" 1 "Lamp ON" ;
VAL_ 689 HDBM_SBRSound_Req 0 "Gong OFF" 1 "Gong ON" ;
VAL_ 689 HDBM_FLSBR_Req 0 "Lamp Off" 1 "Lamp ON" ;
VAL_ 689 HDBM_FRSBR_Req 0 "Lamp Off" 1 "Lamp ON" ;
VAL_ 689 HDBM_SRLSBR_Req 0 "Lamp Off" 1 "Lamp ON" ;
VAL_ 689 HDBM_SRMSBR_Req 0 "Lamp Off" 1 "Lamp ON" ;
VAL_ 689 HDBM_V3WHeatCalEnb_Req 0 "Disable" 1 "Enable" ;
VAL_ 689 HDBM_OHXEXVInit_Req 0 "No Request" 1 "Start Init-Sequence" 2 "waiting for Sequence to finish" 3 "not defined" 4 "not defined" 5 "not defined" 6 "not defined" 7 "not defined" ;
VAL_ 689 HDBM_CHLEXVInit_Req 0 "No Request" 1 "Start Init-Sequence" 2 "waiting for Sequence to finish" 3 "not defined" 4 "not defined" 5 "not defined" 6 "not defined" 7 "not defined" ;
VAL_ 689 HDBM_HEXVMoveEnb_Req 0 "Ignore Commanded Position" 1 "Move to Commanded Position" ;
VAL_ 689 HDBM_ACCMErrorClean_Req 0 "Clear Off" 1 "Clear On" ;
VAL_ 689 HDBM_ACCMEnable_Req 0 "Comp off" 1 "Comp On" ;
VAL_ 689 HDBM_CmpmtInAirPmAQI_St 0 "Level1" 1 "Level2" 2 "Level3" 3 "Level4" 4 "Level5" 5 "Level6" 6 "Reserved" 7 "Invalid" ;
VAL_ 1488 HDBM_FLTpmsPress_Val 255 "Invalid" ;
VAL_ 1488 HDBM_EnvirTemp_Val 255 "Invalid" ;
VAL_ 1488 HDBM_ComprWork_St 0 "Off" 1 "On" 2 "Reserved" 3 "Reserved" ;
VAL_ 1488 HDBM_FragChannel3Life_Val 511 "Invalid" ;
VAL_ 1488 HDBM_FLTpmsTemp_Val 255 "Invalid" ;
VAL_ 1488 HDBM_FragCh1Type_Spec 0 "Flavour1" 1 "Flavour2" 2 "Flavour3" 3 "Flavour4" 4 "Flavour5" 5 "Flavour6" 6 "Flavour7" 7 "Flavour8" 8 "Flavour9" 9 "Flavour10" 10 "Flavour11" 11 "Flavour12" 12 "Flavour13" 13 "Flavour14" 14 "Flavour15" 15 "Invalid" ;
VAL_ 1488 HDBM_EnSvLtCtrl_Req 0 "off" 1 "on" 2 "reserved" 3 "reserved" ;
VAL_ 1488 HDBM_FragChannel2Life_Val 511 "Invalid" ;
VAL_ 1488 HDBM_FragChannel3Life_St 511 "Invalid" ;
VAL_ 1488 HDBM_FragCh2Type_Spec 0 "Flavour1" 1 "Flavour2" 2 "Flavour3" 3 "Flavour4" 4 "Flavour5" 5 "Flavour6" 6 "Flavour7" 7 "Flavour8" 8 "Flavour9" 9 "Flavour10" 10 "Flavour11" 11 "Flavour12" 12 "Flavour13" 13 "Flavour14" 14 "Flavour15" 15 "Invalid" ;
VAL_ 1488 HDBM_FragCh3Type_Spec 0 "Flavour1" 1 "Flavour2" 2 "Flavour3" 3 "Flavour4" 4 "Flavour5" 5 "Flavour6" 6 "Flavour7" 7 "Flavour8" 8 "Flavour9" 9 "Flavour10" 10 "Flavour11" 11 "Flavour12" 12 "Flavour13" 13 "Flavour14" 14 "Flavour15" 15 "Invalid" ;
VAL_ 1488 HDBM_RACCoolOrHeatOrVent_St 0 "Default" 1 "Cool" 2 "Heat" 3 "Vent" ;
VAL_ 1488 HDBM_FRTpmsPress_Val 255 "Invalid" ;
VAL_ 1488 HDBM_RLTpmsPress_Val 255 "Invalid" ;
VAL_ 1488 HDBM_RRTpmsPress_Val 255 "Invalid" ;
VAL_ 1488 HDBM_FRTpmsTemp_Val 255 "Invalid" ;
VAL_ 1488 HDBM_InFilterLifeRemind 0 "Default" 1 "0day" 2 "1day" 3 "2day" 4 "3day" 5 "5day" 6 "10day" 7 "20day" 8 "30day" 9 "Reserved" 10 "Reserved" 11 "Reserved" 12 "Reserved" 13 "Reserved" 14 "Reserved" 15 "Reserved" ;
VAL_ 1488 HDBM_RLTpmsTemp_Val 255 "Invalid" ;
VAL_ 1488 HDBM_RRTpmsTemp_Val 255 "Invalid" ;
VAL_ 1488 HDBM_FrtDeiceDefog_St 0 "None" 1 "Deice Mode" 2 "Defog Mode" 3 "Reserved" ;
VAL_ 1488 HDBM_CampingMode_Rsp 0 "No Request" 1 "OFF" 2 "ON" 3 "Invalid" ;
VAL_ 1488 HDBM_CarMode_St 0 "Normal" 1 "Factory" 2 "Transport" 3 "Dyno" 4 "Reserved" 5 "Reserved" 6 "Reserved" 7 "Reserved" ;
VAL_ 1488 HDBM_CHVHWork_St 0 "Off" 1 "On" 2 "Reserved" 3 "Reserved" ;
VAL_ 421 HDBM_FLTpmsTempWarn_St 0 "normal temperature" 1 "hight temperature" ;
VAL_ 421 HDBM_FRTpmsTempWarn_St 0 "normal temperature" 1 "hight temperature" ;
VAL_ 421 HDBM_FLTpmsLeakWarn_St 0 "No warning" 1 "Warning" ;
VAL_ 421 HDBM_FRTpmsLeakWarn_St 0 "No warning" 1 "Warning" ;
VAL_ 421 HDBM_RLTpmsLeakWarn_St 0 "No warning" 1 "Warning" ;
VAL_ 421 HDBM_RRTpmsLeakWarn_St 0 "No warning" 1 "Warning" ;
VAL_ 421 HDBM_RemFDefrostTime_Rsp 63 "Invalid" ;
VAL_ 421 HDBM_RemVentilateRefine_Rsp 0 "Default" 1 "Close" 2 "Open" 3 "Reserved" ;
VAL_ 421 HDBM_RemVentilateRefineTime_Rsp 63 "Invalid" ;
VAL_ 421 HDBM_RemAppointActive_Rsp 0 "Default" 1 "Deactive" 2 "Active" 3 "Reserved" ;
VAL_ 421 HDBM_RemACUnavailRsn_Spec 0 "None" 1 "Low SOC" 2 "Reserved" 3 "Reserved" 4 "Reserved" 5 "Reserved" 6 "Reserved" 7 "Reserved" ;
VAL_ 421 HDBM_RLTpmsTempWarn_St 0 "normal temperature" 1 "hight temperature" ;
VAL_ 421 HDBM_RRTpmsTempWarn_St 0 "normal temperature" 1 "hight temperature" ;
VAL_ 421 HDBM_RLTpmsPressWarn_St 0 "Normal pressure" 1 "Low pressure" 2 "High pressure" 3 "Reserved" ;
VAL_ 421 HDBM_RRTpmsPressWarn_St 0 "Normal pressure" 1 "Low pressure" 2 "High pressure" 3 "Reserved" ;
VAL_ 421 HDBM_FLTpmsPressWarn_St 0 "Normal pressure" 1 "Low pressure" 2 "High pressure" 3 "Reserved" ;
VAL_ 421 HDBM_FRTpmsPressWarn_St 0 "Normal pressure" 1 "Low pressure" 2 "High pressure" 3 "Reserved" ;
VAL_ 421 HDBM_RRTpmsBattle_St 0 "Normal voltage" 1 "Low voltage" ;
VAL_ 421 HDBM_FLTpmsSensorFailure_St 0 "No failure" 1 "Failure" ;
VAL_ 421 HDBM_FRTpmsSensorFailure_St 0 "No failure" 1 "Failure" ;
VAL_ 421 HDBM_RLTpmsSensorFailure_St 0 "No failure" 1 "Failure" ;
VAL_ 421 HDBM_RRTpmsSensorFailure_St 0 "No failure" 1 "Failure" ;
VAL_ 421 HDBM_FLTpmsBattle_St 0 "Normal voltage" 1 "Low voltage" ;
VAL_ 421 HDBM_FRTpmsBattle_St 0 "Normal voltage" 1 "Low voltage" ;
VAL_ 421 HDBM_RLTpmsBattle_St 0 "Normal voltage" 1 "Low voltage" ;
VAL_ 816 HDBM_BckLtBrtDes_Req 0 "off" 1 "LV1" 2 "LV2" 3 "LV3" 4 "LV4" 5 "LV5" 6 "LV6" 7 "LV7" 8 "LV8" 9 "LV9" 10 "LV10" 11 "reserved" 12 "reserved" 13 "reserved" 14 "reserved" 15 "reserved" ;
VAL_ 816 HDBM_FLTpLtBrtDes_Req 0 "off" 1 "LV1" 2 "LV2" 3 "LV3" 4 "LV4" 5 "LV5" 6 "LV6" 7 "LV7" 8 "LV8" 9 "LV9" 10 "LV10" 11 "reserved" 12 "reserved" 13 "reserved" 14 "reserved" 15 "reserved" ;
VAL_ 816 HDBM_RLTpLtBrtDes_Req 0 "off" 1 "LV1" 2 "LV2" 3 "LV3" 4 "LV4" 5 "LV5" 6 "LV6" 7 "LV7" 8 "LV8" 9 "LV9" 10 "LV10" 11 "reserved" 12 "reserved" 13 "reserved" 14 "reserved" 15 "reserved" ;
VAL_ 816 HDBM_HoodLatch_St 0 "Close" 1 "Open" 2 "Resevered" 3 "Invalid" ;
VAL_ 816 HDBM_FRTpLtBrtDes_Req 0 "off" 1 "LV1" 2 "LV2" 3 "LV3" 4 "LV4" 5 "LV5" 6 "LV6" 7 "LV7" 8 "LV8" 9 "LV9" 10 "LV10" 11 "reserved" 12 "reserved" 13 "reserved" 14 "reserved" 15 "reserved" ;
VAL_ 816 HDBM_RRTpLtBrtDes_Req 0 "off" 1 "LV1" 2 "LV2" 3 "LV3" 4 "LV4" 5 "LV5" 6 "LV6" 7 "LV7" 8 "LV8" 9 "LV9" 10 "LV10" 11 "reserved" 12 "reserved" 13 "reserved" 14 "reserved" 15 "reserved" ;
VAL_ 816 HDBM_EtnlLgt_Rsp 0 "Position" 1 "Low Beam" 2 "Auto" 3 "OFF" ;
VAL_ 816 HDBM_CenterLock_St 0 "AllUnlock," 1 "DriverUnlock" 2 "Lock," 3 "reserved" ;
VAL_ 816 HDBM_LwLgt_Req 0 "OFF" 1 "ON" ;
VAL_ 816 HDBM_ACFaultLevel_St 0 "No Fault" 1 "Fault Level 1" 2 "Fault Level 2" 3 "Fault Level 3" 4 "Fault Level 4" 5 "Reserved" 6 "Reserved" 7 "Reserved" ;
VAL_ 816 HDBM_FLPstnLgt_Req 0 "Off" 1 "On" ;
VAL_ 816 HDBM_FRPstnLgt_Req 0 "Off" 1 "On" ;
VAL_ 816 HDBM_HighLgt_Req 0 "Off" 1 "On" ;
VAL_ 816 HDBM_OtkLgt_Req 0 "Off" 1 "On" ;
VAL_ 816 HDBM_FLWdwCtl_Req 0 "No Request" 1 "Manual Up" 2 "Manual Down" 3 "Auto Up" 4 "Auto Down" 5 "Stop" 6 "Reserved" 7 "Invalid" ;
VAL_ 816 HDBM_FRWdwCtl_Req 0 "No Request" 1 "Manual Up" 2 "Manual Down" 3 "Auto Up" 4 "Auto Down" 5 "Stop" 6 "Reserved" 7 "Invalid" ;
VAL_ 816 HDBM_SteerTiltAdj_Req 0 "Stop" 1 "Up" 2 "Down" 3 "Invalid" ;
VAL_ 816 HDBM_RLWdwCtl_Req 0 "No Request" 1 "Manual Up" 2 "Manual Down" 3 "Auto Up" 4 "Auto Down" 5 "Stop" 6 "Reserved" 7 "Invalid" ;
VAL_ 816 HDBM_SteerTeleAdj_Req 0 "Stop" 1 "Stretch" 2 "Shrink" 3 "Invalid" ;
VAL_ 816 HDBM_FWiperCtrl_Req 0 "OFF" 1 "Low wipes" 2 "High wipes" 3 "Service" 4 "int1(预留)" 5 "in2（预留）" 6 "stop（预留)" 7 "Invalid" ;
VAL_ 816 HDBM_FWiperWashCtrl_Req 0 "Inactive" 1 "Active" ;
VAL_ 816 HDBM_FLHdlCtrl_Req 0 "no request" 1 "close" 2 "open" 3 "stop" 4 "break freeze" 5 "crash open" 6 "reserved" 7 "reserved" ;
VAL_ 816 HDBM_RLHdlCtrl_Req 0 "no request" 1 "close" 2 "open" 3 "stop" 4 "break freeze" 5 "crash open" 6 "reserved" 7 "reserved" ;
VAL_ 816 HDBM_FRHdlCtrl_Req 0 "no request" 1 "close" 2 "open" 3 "stop" 4 "break freeze" 5 "crash open" 6 "reserved" 7 "reserved" ;
VAL_ 816 HDBM_TpLtClrDes_Req 0 "cold" 1 "warm" 2 "reserved" 3 "reserved" ;
VAL_ 816 HDBM_RRHdlCtrl_Req 0 "no request" 1 "close" 2 "open" 3 "stop" 4 "break freeze" 5 "crash open" 6 "reserved" 7 "reserved" ;
VAL_ 816 HDBM_RLPstnLgt_Req 0 "OFF" 1 "ON" ;
VAL_ 816 HDBM_RRPstnLgt_Req 0 "OFF" 1 "ON" ;
VAL_ 816 HDBM_RearFogBm_Req 0 "OFF" 1 "ON" ;
VAL_ 816 HDBM_RRWdwCtl_Req 0 "No Request" 1 "Manual Up" 2 "Manual Down" 3 "Auto Up" 4 "Auto Down" 5 "Stop" 6 "Reserved" 7 "Invalid" ;
VAL_ 816 HDBM_RsLgt_Req 0 "OFF" 1 "ON" ;
VAL_ 816 HDBM_TrkLtCtrl_Req 0 "off" 1 "on" 2 "reserved" 3 "reserved" ;
VAL_ 816 HDBM_FRHdlLearn_Req 0 "no request" 1 "learn open" 2 "learn close" 3 "reserved" ;
VAL_ 816 HDBM_RRHdlLearn_Req 0 "no request" 1 "learn open" 2 "learn close" 3 "reserved" ;
VAL_ 816 HDBM_FLHdlLearn_Req 0 "no request" 1 "learn open" 2 "learn close" 3 "reserved" ;
VAL_ 816 HDBM_RLHdlLearn_Req 0 "no request" 1 "learn open" 2 "learn close" 3 "reserved" ;
VAL_ 816 HDBM_FLTpLtClrDes_Req 0 "cold" 1 "warm" 2 "reserved" 3 "Invalid" ;
VAL_ 816 HDBM_RLTpLtClrDes_Req 0 "cold" 1 "warm" 2 "reserved" 3 "Invalid" ;
VAL_ 816 HDBM_FRTpLtClrDes_Req 0 "cold" 1 "warm" 2 "reserved" 3 "Invalid" ;
VAL_ 816 HDBM_RRTpLtClrDes_Req 0 "cold" 1 "warm" 2 "reserved" 3 "Invalid" ;
VAL_ 816 HDBM_SteerTiltSpd_Req 30 "No Request" 31 "Invalid" ;
VAL_ 816 HDBM_SteerTeleSpd_Req 30 "No Request" 31 "Invalid" ;
VAL_ 816 HDBM_SteerLn_Req 0 "No Request" 1 "Request" ;
VAL_ 816 HDBM_ParkingSwitch_Req 0 "No Request" 1 "APPLY" 2 "RELEASE" 3 "Reserved" ;
VAL_ 816 HDBM_EHBMBrkModeSet_Req 0 "default" 1 "standard" 2 "reserved" 3 "sport" 4 "reserved" 5 "reserved" 6 "reserved" 7 "Invalid" ;
VAL_ 816 HDBM_TCSSw_Req 0 "No Request" 1 "OFF" 2 "ON" 3 "Reserved" ;
VAL_ 816 HDBM_AVHSw_Req 0 "No Request" 1 "OFF" 2 "ON" 3 "Reserved" ;
VAL_ 816 HDBM_HDCSw_Req 0 "No Request" 1 "OFF" 2 "ON" 3 "Reserved" ;
VAL_ 816 HDBM_CSTSw_Req 0 "No Request" 1 "OFF" 2 "ON" 3 "Reserved" ;
VAL_ 816 HDBM_ESCSw_Req 0 "No Request" 1 "OFF" 2 "ON" 3 "Reserved" ;
VAL_ 1489 HDBM_FragSwitchEn_Rsp 0 "Default" 1 "Disable" 2 "Enable" 3 "Reserved" ;
VAL_ 1489 HDBM_FragCh1Sw_St 0 "Default" 1 "Close" 2 "Open" 3 "Invalid" ;
VAL_ 1489 HDBM_FragCh2Sw_St 0 "Default" 1 "Close" 2 "Open" 3 "Invalid" ;
VAL_ 1489 HDBM_FragCh3Sw_St 0 "Default" 1 "Close" 2 "Open" 3 "Invalid" ;
VAL_ 1489 HDBM_FragConcLvl_Rsp 0 "Default" 1 "Density1" 2 "Density2" 3 "Density3" 4 "Reserved" 5 "Reserved" 6 "Reserved" 7 "Reserved" ;
VAL_ 1489 HDBM_AQSAirQuality_Val 0 "Default" 1 "Luftguete 10%" 2 "Luftguete 20%" 3 "Luftguete 30%" 4 "Luftguete 40%" 5 "Luftguete 50%" 6 "Luftguete 60%" 7 "Luftguete 70%" 8 "Luftguete 80%" 9 "Luftguete 90%" 10 "Luft Stark" 11 "Reserved" 12 "Reserved" 13 "Reserved" 14 "Reserved" 15 "Reserved" ;
VAL_ 1489 HDBM_PM25Set_St 0 "Default" 1 "Deactive" 2 "Active" 3 "Reserved" ;
VAL_ 1489 HDBM_PM25Trigger_St 0 "Default" 1 "Close" 2 "Open" 3 "Reserved" ;
VAL_ 1489 HDBM_FDeiceDefrost_Rsp 0 "Default" 1 "Close" 2 "Open" 3 "Reserved" ;
VAL_ 1489 HDBM_AutoDefogSensDectect_St 0 "No Defog" 1 "Meet Defog Condition" 2 "Reserved" 3 "Invalid" ;
VAL_ 1489 HDBM_AutoDefrostSet_St 0 "Default" 1 "Deactive" 2 "Active" 3 "Reserved" ;
VAL_ 1489 HDBM_AutoDefrostTrigger_St 0 "Default" 1 "Close" 2 "Open" 3 "Reserved" ;
VAL_ 1489 HDBM_IONSet_St 0 "Default" 1 "Deactive" 2 "Active" 3 "Reserved" ;
VAL_ 1489 HDBM_ACSwtich_St 0 "Default" 1 "Deactive" 2 "Active" 3 "Reserved" ;
VAL_ 1489 HDBM_FACSwitch_Rsp 0 "Default" 1 "Close" 2 "Open" 3 "Reserved" ;
VAL_ 1489 HDBM_FACAirFlowLevel_St 0 "Default" 1 "Level_1" 2 "Level_2" 3 "Level_3" 4 "Level_4" 5 "Level_5" 6 "Level_6" 7 "Level_7" 8 "Level_8" 9 "Level_9" 10 "Level_10" 11 "Reserved" 12 "Reserved" 13 "Reserved" 14 "Reserved" 15 "Reserved" ;
VAL_ 1489 HDBM_FAcCoolOrHeatOrVent_St 0 "Default" 1 "Cool" 2 "Heat" 3 "Vent" ;
VAL_ 1489 HDBM_FLeftTempSet_St 0 "Deafult" 1 "Low" 2 "16℃" 3 "16.5℃" 4 "17℃" 5 "17.5℃" 6 "18℃" 7 "18.5℃" 8 "19℃" 9 "19.5℃" 10 "20℃" 11 "20.5℃" 12 "21℃" 13 "21.5℃" 14 "22℃" 15 "22.5℃" 16 "23℃" 17 "23.5℃" 18 "24℃" 19 "24.5℃" 20 "25℃" 21 "25.5℃" 22 "26℃" 23 "26.5℃" 24 "27℃" 25 "27.5℃" 26 "28℃" 27 "28.5℃" 28 "29℃" 29 "29.5℃" 30 "30℃" 31 "30.5℃" 32 "31℃" 33 "High" ;
VAL_ 1489 HDBM_FRightTempSet_St 0 "Deafult" 1 "Low" 2 "16℃" 3 "16.5℃" 4 "17℃" 5 "17.5℃" 6 "18℃" 7 "18.5℃" 8 "19℃" 9 "19.5℃" 10 "20℃" 11 "20.5℃" 12 "21℃" 13 "21.5℃" 14 "22℃" 15 "22.5℃" 16 "23℃" 17 "23.5℃" 18 "24℃" 19 "24.5℃" 20 "25℃" 21 "25.5℃" 22 "26℃" 23 "26.5℃" 24 "27℃" 25 "27.5℃" 26 "28℃" 27 "28.5℃" 28 "29℃" 29 "29.5℃" 30 "30℃" 31 "30.5℃" 32 "31℃" 33 "High" ;
VAL_ 1489 HDBM_FTempAreaSync_St 0 "Default" 1 "Deactive" 2 "Active" 3 "Reserved" ;
VAL_ 1489 HDBM_HvOnACM_Req 0 "No Request" 1 "Request" ;
VAL_ 1489 HDBM_HVWork_Req 0 "No Request" 1 "Request" ;
VAL_ 1489 HDBM_RESSCoolFault_St 0 "正常" 1 "限功率运行" 2 "无法运行" 3 "Invalid" ;
VAL_ 1489 HDBM_FACAirFlowLevelAuto_St 0 "Default" 1 "Auto" 2 "Manual" 3 "Reserved" ;
VAL_ 1489 HDBM_FACAirFlowModeAuto_St 0 "Default" 1 "Auto" 2 "Manual" 3 "Reserved" ;
VAL_ 1489 HDBM_FACCoolOrHeatOrVentAuto_St 0 "Default" 1 "Auto" 2 "Manual" 3 "Reserved" ;
VAL_ 1489 HDBM_TDrDegDes_Req 254 "no request" 255 "Invalid" ;
VAL_ 1489 HDBM_TDrDegSet_Rsp 255 "Invalid" ;
VAL_ 1489 HDBM_LDRLgt_Req 0 "OFF" 1 "ON" ;
VAL_ 1489 HDBM_RDRLgt_Req 0 "OFF" 1 "ON" ;
VAL_ 1489 HDBM_FLDrPdlLtCtrl_Req 0 "off" 1 "on" 2 "reserved" 3 "reserved" ;
VAL_ 1489 HDBM_FRDrPdlLtCtrl_Req 0 "off" 1 "on" 2 "reserved" 3 "reserved" ;
VAL_ 1489 HDBM_RLDrPdlLtCtrl_Req 0 "off" 1 "on" 2 "reserved" 3 "reserved" ;
VAL_ 1489 HDBM_RRDrPdlLtCtrl_Req 0 "off" 1 "on" 2 "reserved" 3 "reserved" ;
VAL_ 1489 HDBM_FLDrCtrl_Req 0 "no request" 1 "close" 2 "open" 3 "reserved" ;
VAL_ 1489 HDBM_FRDrCtrl_Req 0 "no request" 1 "close" 2 "open" 3 "reserved" ;
VAL_ 1489 HDBM_RLDrCtrl_Req 0 "no request" 1 "close" 2 "open" 3 "reserved" ;
VAL_ 1489 HDBM_RRDrCtrl_Req 0 "no request" 1 "close" 2 "open" 3 "reserved" ;
VAL_ 1489 HDBM_FLDrLthCinch_Req 0 "no request" 1 "cinch" 2 "resume from cinch" 3 "stop" 4 "reserved" 5 "reserved" 6 "reserved" 7 "reserved" ;
VAL_ 1489 HDBM_TDrSpdDes_Req 0 "no request" 1 "slow" 2 "standard" 3 "fast" 4 "reserved" 5 "reserved" 6 "reserved" 7 "reserved" ;
VAL_ 1489 HDBM_TDrCtrl_Req 0 "no request" 1 "close" 2 "open" 3 "stop" 4 "reserved" 5 "reserved" 6 "reserved" 7 "reserved" ;
VAL_ 1489 HDBM_TDrLthCinch_Req 0 "no request" 1 "cinch" 2 "resume from cinch" 3 "stop" 4 "reserved" 5 "reserved" 6 "reserved" 7 "reserved" ;
VAL_ 1489 HDBM_RLDrLthCinch_Req 0 "no request" 1 "cinch" 2 "resume from cinch" 3 "stop" 4 "reserved" 5 "reserved" 6 "reserved" 7 "reserved" ;
VAL_ 1489 HDBM_FRDrLthCinch_Req 0 "no request" 1 "cinch" 2 "resume from cinch" 3 "stop" 4 "reserved" 5 "reserved" 6 "reserved" 7 "reserved" ;
VAL_ 1489 HDBM_RRDrLthCinch_Req 0 "no request" 1 "cinch" 2 "resume from cinch" 3 "stop" 4 "reserved" 5 "reserved" 6 "reserved" 7 "reserved" ;
VAL_ 1489 HDBM_RLDrLthRls_Req 0 "no request" 1 "release" 2 "resume from release" 3 "stop" 4 "reserved" 5 "reserved" 6 "reserved" 7 "reserved" ;
VAL_ 1489 HDBM_FRDrLthRls_Req 0 "no request" 1 "release" 2 "resume from release" 3 "stop" 4 "reserved" 5 "reserved" 6 "reserved" 7 "reserved" ;
VAL_ 1489 HDBM_RRDrLthRls_Req 0 "no request" 1 "release" 2 "resume from release" 3 "stop" 4 "reserved" 5 "reserved" 6 "reserved" 7 "reserved" ;
VAL_ 1489 HDBM_FLDrLthRls_Req 0 "no request" 1 "release" 2 "resume from release" 3 "stop" 4 "reserved" 5 "reserved" 6 "reserved" 7 "reserved" ;
VAL_ 1489 HDBM_RESSCoolPwrLim_St 0 "Not Limit" 1 "Limit" ;
VAL_ 1489 HDBM_RESSHeatFault_St 0 "正常" 1 "限功率运行" 2 "无法运行" 3 "Invalid" ;
VAL_ 1489 HDBM_ACMWork_St 0 "休眠" 1 "正常运行" 2 "异常运行" 3 "Reserved" ;
VAL_ 1489 HDBM_HeatRecycle_Req 0 "No _Req" 1 "_Req" ;
VAL_ 1489 HDBM_DeiceDefog_Req 0 "No _Req" 1 "Deice Mode" 2 "Defog Mode" ;
VAL_ 1489 HDBM_HeatRecycleDisable_St 0 "Allow" 1 "No Heat Recycle" ;
VAL_ 1489 HDBM_ChrgCapCtrl_Req 0 "NoRequest" 1 "Open" 2 "Close" 3 "Stop" ;
VAL_ 1489 HDBM_TDrLthRls_Req 0 "no request" 1 "release" 2 "resume from release" 3 "stop" 4 "reserved" 5 "reserved" 6 "reserved" 7 "reserved" ;
VAL_ 1489 HDBM_RRDrLthCinchFbd_Req 0 "not forbid" 1 "forbid" 2 "reserved" 3 "Invalid" ;
VAL_ 1489 HDBM_FLDrLthCinchFbd_Req 0 "not forbid" 1 "forbid" 2 "reserved" 3 "Invalid" ;
VAL_ 1489 HDBM_RLDrLthCinchFbd_Req 0 "not forbid" 1 "forbid" 2 "reserved" 3 "Invalid" ;
VAL_ 1489 HDBM_FRDrLthCinchFbd_Req 0 "not forbid" 1 "forbid" 2 "reserved" 3 "Invalid" ;
VAL_ 1489 HDBM_ChrgCapLearn_Req 0 "NoRequest" 1 "Learn" 2 "Stop" 3 "Invalid" ;
VAL_ 1489 HDBM_IONSwitch_Req 0 "Default" 1 "Close" 2 "Open" 3 "Reserved" ;
VAL_ 1489 HDBM_InPm25SnsrActn_Req 0 "Default" 1 "Close" 2 "Open" 3 "Reserved" ;
VAL_ 1489 HDBM_TDrLthCinchFbd_Req 0 "not forbid" 1 "forbid" 2 "reserved" 3 "Invalid" ;
VAL_ 1025 HDBM_RepeatMsgReq_VB1 0 "Repeat Message State not requested" 1 "Repeat Message State requested" ;
VAL_ 1025 HDBM_ActiveWakeup_VB1 0 "passive Wakeup" 1 "active Wakeup" ;
VAL_ 1025 HDBM_PartialNetworkInfo_VB1 0 "NM PDU contains no Partial Network request information" 1 "NM PDU contains Partial Network request information" ;
VAL_ 1025 HDBM_RepeatMsgSt_VB1 0 "Not in Repeat Message State" 1 "In Repeat Message State" ;
VAL_ 1025 HDBM_PN_HDBT_VB1 0 "No Request" 1 "Request" ;
VAL_ 1025 HDBM_PN_HDBI_VB1 0 "No Request" 1 "Request" ;
VAL_ 1025 HDBM_PN_HDBA_VB1 0 "No Request" 1 "Request" ;
VAL_ 1025 HDBM_PN_HDBM_VB1 0 "No Request" 1 "Request" ;
VAL_ 1025 HDBM_PN_ZCUF_VB1 0 "No Request" 1 "Request" ;
VAL_ 1025 HDBM_PN_ZCUL_VB1 0 "No Request" 1 "Request" ;
VAL_ 1025 HDBM_PN_ZCUR_VB1 0 "No Request" 1 "Request" ;
VAL_ 1025 HDBM_PN_ZCUT_VB1 0 "No Request" 1 "Request" ;
VAL_ 690 HDBM_BrkLgt_Req 0 "OFF" 1 "ON" ;
VAL_ 690 HDBM_Horn_Req 0 "inActive" 1 "Active" ;
VAL_ 690 HDBM_KeyResearch_Req 0 "No Request" 1 "Request" ;
VAL_ 690 HDBM_HHChrgPileRecognize_St 0 "None" 1 "HH Charger Recognized" ;
VAL_ 690 HDBM_AGSEn_Req 0 "No _Req" 1 "_Req" ;
VAL_ 690 HDBM_AGSPosition_Req 0 "全关" 90 "水平全开" ;
VAL_ 690 HDBM_ECFEn_Req 0 "No _Req" 1 "_Req" ;
VAL_ 690 HDBM_FHVACLeftMixPos_Req 1023 "Invalid" ;
VAL_ 690 HDBM_FHVACRigtMixPos_Req 1023 "Invalid" ;
VAL_ 690 HDBM_FHVACModePos_Req 1023 "Invalid" ;
VAL_ 690 HDBM_FHVACCyclePos_Req 1023 "Invalid" ;
VAL_ 690 HDBM_FHVACBypassPos_Req 1023 "Invalid" ;
VAL_ 690 HDBM_FHVACDefrostPos_Req 1023 "Invalid" ;
VAL_ 690 HDBM_FHVACBLWPWM_Req 1023 "Invalid" ;
VAL_ 690 HDBM_FHVACBLWRelay_Req 0 "Default" 1 "Close" 2 "Open" 3 "Reserved" ;
VAL_ 690 HDBM_OTAMode_St 0 "Normal" 1 "Download" 2 "Door And Lock Upgrading" 3 "High Voltage Upgrading" 4 "Embed ECU Upgrading" 5 "Ethernet ECU Upgrading" ;
VAL_ 422 HDBM_FRSeatMsgStrth_Req 0 "NoRequest" 1 "Strength1" 2 "Strength2" 3 "Strength3" 4 "Strength4" 5 "Strength5" 6 "Strength6" 7 "Invalid" ;
VAL_ 422 HDBM_FLSeatMsg_Req 0 "No Request" 1 "OFF" 2 "ON" 3 "Reserved" ;
VAL_ 422 HDBM_FLSeatMsgMode_Req 0 "NoRequest" 1 "Mode1" 2 "Mode2" 3 "Mode3" 4 "Mode4" 5 "Mode5" 6 "Mode6" 15 "Reserved" ;
VAL_ 422 HDBM_FLSeatMsgStrth_Req 0 "NoRequest" 1 "Strength1" 2 "Strength2" 3 "Strength3" 4 "Strength4" 5 "Strength5" 6 "Strength6" 7 "Invalid" ;
VAL_ 422 HDBM_FRSeatMsg_Req 0 "No Request" 1 "OFF" 2 "ON" 3 "Reserved" ;
VAL_ 422 HDBM_FRSeatMsgMode_Req 0 "NoRequest" 1 "Mode1" 2 "Mode2" 3 "Mode3" 4 "Mode4" 5 "Mode5" 6 "Mode6" 15 "Reserved" ;
VAL_ 423 HDBM_FLSeatHgtAdj_Req 0 "Stop" 1 "Up" 2 "Down" 3 "Invalid" ;
VAL_ 423 HDBM_FRLegAngCshnExtAdj_Req 0 "Stop" 1 "Up" 2 "Down" 3 "Invalid" ;
VAL_ 423 HDBM_FLSeatFBAdjSpd_Req 30 "No Request" 31 "Invalid" ;
VAL_ 423 HDBM_FLLegAngCshnExtAdj_Req 0 "Stop" 1 "Up" 2 "Down" 3 "Invalid" ;
VAL_ 423 HDBM_FLSeatBackrestAdjSpd_Req 30 "No Request" 31 "Invalid" ;
VAL_ 423 HDBM_FLSeatHgtAdjSpd_Req 30 "No Request" 31 "Invalid" ;
VAL_ 423 HDBM_FLSeatCshnAngAdjSpd_Req 30 "No Request" 31 "Invalid" ;
VAL_ 423 HDBM_FLLegAngCshnExtAdjSpd_Req 30 "No Request" 31 "Invalid" ;
VAL_ 423 HDBM_FRSeatFBAdjSpd_Req 30 "No Request" 31 "Invalid" ;
VAL_ 423 HDBM_FRSeatBackrestAdjSpd_Req 30 "No Request" 31 "Invalid" ;
VAL_ 423 HDBM_FRSeatHgtAdjSpd_Req 30 "No Request" 31 "Invalid" ;
VAL_ 423 HDBM_FRSeatCshnAngAdjSpd_Req 30 "No Request" 31 "Invalid" ;
VAL_ 423 HDBM_FRLegAngCshnExtAdjSpd_Req 30 "No Request" 31 "Invalid" ;
VAL_ 423 HDBM_FLLumbSuppFBAdj_Req 0 "No Request" 1 "Front" 2 "Back" 3 "Invalid" ;
VAL_ 423 HDBM_FLLumbSuppUDAdj_Req 0 "No Request" 1 "Up" 2 "Down" 3 "Invalid" ;
VAL_ 423 HDBM_FRLumbSuppFBAdj_Req 0 "No Request" 1 "Front" 2 "Back" 3 "Invalid" ;
VAL_ 423 HDBM_FRLumbSuppUDAdj_Req 0 "No Request" 1 "Up" 2 "Down" 3 "Invalid" ;
VAL_ 423 HDBM_FLSeatCshnAngAdj_Req 0 "Stop" 1 "Up" 2 "Down" 3 "Invalid" ;
VAL_ 423 HDBM_FLSeatFBAdj_Req 0 "Stop" 1 "Front" 2 "Rear" 3 "Invalid" ;
VAL_ 423 HDBM_FLSeatBackrestAdj_Req 0 "Stop" 1 "Front" 2 "Rear" 3 "Invalid" ;
VAL_ 423 HDBM_FRSeatHgtAdj_Req 0 "Stop" 1 "Up" 2 "Down" 3 "Invalid" ;
VAL_ 423 HDBM_FRSeatFBAdj_Req 0 "Stop" 1 "Front" 2 "Rear" 3 "Invalid" ;
VAL_ 423 HDBM_FRSeatBackrestAdj_Req 0 "Stop" 1 "Front" 2 "Rear" 3 "Invalid" ;
VAL_ 423 HDBM_FRSeatCshnAngAdj_Req 0 "Stop" 1 "Up" 2 "Down" 3 "Invalid" ;
VAL_ 423 HDBM_RExMirUDAdj_Req 0 "Stop" 1 "Up" 2 "Down" 3 "Invalid" ;
VAL_ 423 HDBM_RExMirLRAdj_Req 0 "Stop" 1 "Left" 2 "Right" 3 "Invalid" ;
VAL_ 423 HDBM_LExMirUDAdj_Req 0 "Stop" 1 "Up" 2 "Down" 3 "Invalid" ;
VAL_ 423 HDBM_LExMirLRAdj_Req 0 "Stop" 1 "Left" 2 "Right" 3 "Invalid" ;
VAL_ 423 HDBM_LExMirCtrl_Req 0 "Stop" 1 "fold" 2 "unfold" 3 "invalid" ;
VAL_ 423 HDBM_RExMirCtrl_Req 0 "Stop" 1 "fold" 2 "unfold" 3 "invalid" ;
VAL_ 423 HDBM_LExMirCtrlSpd_Req 30 "No Request" 31 "Invalid" ;
VAL_ 423 HDBM_RExMirCtrlSpd_Req 30 "No Request" 31 "Invalid" ;
VAL_ 423 HDBM_RExMirLRAdjSpd_Req 30 "No Request" 31 "Invalid" ;
VAL_ 423 HDBM_LExMirUDAdjSpd_Req 30 "No Request" 31 "Invalid" ;
VAL_ 423 HDBM_LExMirLRAdjSpd_Req 30 "No Request" 31 "Invalid" ;
VAL_ 423 HDBM_RExMirUDAdjSpd_Req 30 "No Request" 31 "Invalid" ;
VAL_ 1490 HDBM_AbsoluteTimeSecond_Val 63 "Invalid" ;
VAL_ 1490 HDBM_AbsoluteTimeMinute_Val 63 "Invalid" ;
VAL_ 1490 HDBM_AbsoluteTimeHour_Val 31 "Invalid" ;
VAL_ 1490 HDBM_AbsoluteTimeDay_Val 63 "Invalid" ;
VAL_ 1490 HDBM_AbsoluteTimeMonth_Val 15 "Invalid" ;
VAL_ 1490 HDBM_AbsoluteTimeYear_Val 255 "Invalid" ;
VAL_ 817 HDBM_RemCtrlACDuration_Req 63 "Invalid" ;
VAL_ 817 HDBM_RemCtrlThmlMagDurn_Req 1023 "Invalid" ;
VAL_ 817 HDBM_RemCtrlAirCleanDurn_Req 63 "Invalid" ;
VAL_ 817 HDBM_FLBckupDoorCtrl_Req 0 "no request" 1 "back up open" 2 "reserved" 3 "reserved" ;
VAL_ 817 HDBM_FRBckupDoorCtrl_Req 0 "no request" 1 "back up open" 2 "reserved" 3 "reserved" ;
VAL_ 817 HDBM_RLBckupDoorCtrl_Req 0 "no request" 1 "back up open" 2 "reserved" 3 "reserved" ;
VAL_ 817 HDBM_RRBckupDoorCtrl_Req 0 "no request" 1 "back up open" 2 "reserved" 3 "reserved" ;
VAL_ 817 HDBM_Whitelistsync_Req 0 "No request" 1 "sharing process" 2 "freezing process" 3 "unfreeze process" 4 "delete  process" 5 "Owneractivation process" 6 "NFC Key Freeze;" 7 "~" 15 "Reserved" ;
VAL_ 353 HDBM_PowertrainRestrict_Req 0 "No request" 1 "Inactive" 2 "Active" 3 "Reserved" ;
VAL_ 353 HDBM_ChargeCutOffSOC_Req 255 "Invalid" ;
VAL_ 128 HDBM_AmLtTarget1_Req 0 "none" 1 "ALM-LIP1" 2 "ALM-LIP2" 4 "ALM-DFL1" 8 "ALM-DFL2" 16 "ALM-MFL" 32 "ALM-MRL" 64 "ALM-DFLH" 128 "ALM-DRLH" 255 "all" ;
VAL_ 128 HDBM_AmLtTarget2_Req 0 "none" 1 "ALM-RIP1" 2 "ALM-RIP2" 4 "ALM-DFR1" 8 "ALM-DFR2" 16 "ALM-MFR" 32 "ALM-MRR" 64 "ALM-DFRH" 128 "ALM-DRRH" 255 "all" ;
VAL_ 128 HDBM_AmLtTarget3_Req 0 "none" 1 "ALM-DRL" 2 "ALM-DRR" 4 "ALM-FFL" 8 "ALM-FFR" 16 "ALM-CSL" 255 "all" ;
VAL_ 128 HDBM_AmLtBrt_Req 255 "Invalid" ;
VAL_ 128 HDBM_AmLtHornClrMd_Req 0 "normal" 1 "mix 1" 2 "mix 2" 3 "mix 3" ;
VAL_ 128 HDBM_AmLtHornWrkMd_Req 0 "static" 1 "breath" 2 "flow" 3 "groove" ;
VAL_ 80 ZCUT_BatteryVolt_Val 4095 "Invalid" ;
VAL_ 81 ZCUT_DCCharge_St 0 "Not Charge" 1 "Charging" 2 "Charge Completed" 3 "Charge Fault" 4 "Charge preparing" 5 "ChgPilePowSupply_preHeating" 6 "ChgPilePowSupply_preCooling" 7 "ChgPilePowSupply_Accessories" 8 "ChgPilePowSupply_Completed" 9 "Reserved" 10 "Reserved" 11 "Reserved" 12 "Reserved" 13 "Reserved" 14 "Reserved" 15 "Reserved" ;
VAL_ 81 ZCUT_ACCharge_St 0 "Not Charge" 1 "Charging" 2 "Charge Completed" 3 "Charge Fault" 4 "Charge preparing" 5 "ChgPilePowSupply_preHeating" 6 "ChgPilePowSupply_preCooling" 7 "ChgPilePowSupply_Accessories" 8 "ChgPilePowSupply_Completed" 9 "Reserved" 10 "Reserved" 11 "Reserved" 12 "Reserved" 13 "Reserved" 14 "Reserved" 15 "Reserved" ;
VAL_ 81 ZCUT_CellOverTemp_St 0 "Not fault" 1 "Fault" ;
VAL_ 81 ZCUT_RLBrkLgt_St 0 "OFF" 1 "ON" ;
VAL_ 81 ZCUT_HighBrkLgt_St 0 "OFF" 1 "ON" ;
VAL_ 81 ZCUT_RRBrkLgt_St 0 "OFF" 1 "ON" ;
VAL_ 81 ZCUT_State_St 0 "Sleep" 1 "Init" 2 "Standby" 3 "Drive" 4 "DC charge" 5 "AC charge" 6 "Reseved" 7 "Afterrun" 8 "Error" 9 "Reserved" 10 "Service" 11 "Reserved" 12 "Reserved" 13 "Reserved" 14 "Reserved" 15 "Invalid" ;
VAL_ 81 ZCUT_FastChrgCnctor_St 0 "No Connected" 1 "Connected" 2 "Abnormal" 3 "Reserved" ;
VAL_ 81 ZCUT_Current_Val 65535 "Invalid" ;
VAL_ 81 ZCUT_SOCDisplay_Val 1023 "Invalid" ;
VAL_ 81 ZCUT_FaultLevel_Err 0 "No Fault" 1 "Fault Level 1" 2 "Fault Level 2" 3 "Fault Level 3" 4 "Fault Level 4" 5 "Reserved" 6 "Reserved" 7 "Reserved" 8 "Reserved" 9 "Reserved" 10 "Reserved" 11 "Reserved" 12 "Reserved" 13 "Reserved" 14 "Reserved" 15 "Reserved" ;
VAL_ 208 ZCUT_RLTnLgt_St 0 "OFF" 1 "ON" ;
VAL_ 208 ZCUT_RRTnLgt_St 0 "OFF" 1 "ON" ;
VAL_ 208 ZCUT_ChrgCapSW_St 0 "NoRequest" 1 "0-3s之内" 2 "3-6s之内" 3 "6s以上" 4 "Reserved" 5 "Reserved" 6 "Reserved" 7 "Reserved" ;
VAL_ 544 ZCUT_ChrgDischrgCnct_St 0 "No Connect" 1 "Connected" 2 "Connect Abnormal" 3 "Invalid" 4 "Reserved" 5 "Reserved" 6 "Reserved" 7 "Reserved" ;
VAL_ 544 ZCUT_TrkLtWrk_St 0 "OFF" 1 "ON" 2 "reserved" 3 "reserved" ;
VAL_ 544 ZCUT_RLPstnLgt_St 0 "OFF" 1 "ON" ;
VAL_ 544 ZCUT_RRPstnLgt_St 0 "OFF" 1 "ON" ;
VAL_ 544 ZCUT_RLTnLgtErr_St 0 "No Error" 1 "Error" ;
VAL_ 544 ZCUT_RRTnLgtErr_St 0 "No Error" 1 "Error" ;
VAL_ 544 ZCUT_SRLSeatOcp_St 0 "Unoccupied" 1 "Occupied" 2 "Reserved" 3 "Reserved" ;
VAL_ 544 ZCUT_SRRSeatOcp_St 0 "Unoccupied" 1 "Occupied" 2 "Reserved" 3 "Reserved" ;
VAL_ 544 ZCUT_SRMSeatOcp_St 0 "Unoccupied" 1 "Occupied" 2 "Reserved" 3 "Reserved" ;
VAL_ 544 ZCUT_TempModuMax_Val 255 "Invalid" ;
VAL_ 544 ZCUT_TRLSeatOcp_St 0 "Unoccupied" 1 "Occupied" 2 "Reserved" 3 "Reserved" ;
VAL_ 544 ZCUT_TRRSeatOcp_St 0 "Unoccupied" 1 "Occupied" 2 "Reserved" 3 "Reserved" ;
VAL_ 544 ZCUT_TempModuMin_Val 255 "Invalid" ;
VAL_ 544 ZCUT_SOCReal_Val 1023 "Invalid" ;
VAL_ 544 ZCUT_RLRsLgt_St 0 "OFF" 1 "ON" ;
VAL_ 544 ZCUT_RRRsLgt_St 0 "OFF" 1 "ON" ;
VAL_ 544 ZCUT_ChrgCutOffSOCSetVal_Rsp 254 "Invalid" ;
VAL_ 544 ZCUT_HHchrgPileCnct_St 0 "Not connected" 1 "Connected" ;
VAL_ 544 ZCUT_TRLSeatBelt_St 0 "Not Tied" 1 "Tied" ;
VAL_ 544 ZCUT_TRRSeatBelt_St 0 "Not Tied" 1 "Tied" ;
VAL_ 544 ZCUT_SRLSeatBelt_St 0 "Not Tied" 1 "Tied" ;
VAL_ 544 ZCUT_SRMSeatBelt_St 0 "Not Tied" 1 "Tied" ;
VAL_ 544 ZCUT_SRRSeatBelt_St 0 "Not Tied" 1 "Tied" ;
VAL_ 544 ZCUT_DisplayCharge_St 0 "Not Charge" 1 "Wait to Charge" 2 "Charging" 3 "Charge Completed" 4 "Accessories" 5 "Preheating" 6 "Precooling" 7 "Charge Fault" 8 "Reserve" 9 "Reserve" 10 "Reserve" 11 "Reserve" 12 "Reserve" 13 "Reserve" 14 "Reserve" 15 "Reserve" ;
VAL_ 929 ZCUT_TempModuMaxID_Dat 255 "Invalid" ;
VAL_ 929 ZCUT_TempModuMinID_Dat 255 "Invalid" ;
VAL_ 929 ZCUT_OverCharge_St 0 "正常" 1 "动力电池过充" ;
VAL_ 929 ZCUT_VoltCellMaxID_Dat 255 "Invalid" ;
VAL_ 929 ZCUT_SubTempHighID_Dat 255 "Invalid" ;
VAL_ 929 ZCUT_VoltCellMax_Val 65535 "Invalid" ;
VAL_ 929 ZCUT_SubTempLowID_Dat 255 "Invalid" ;
VAL_ 929 ZCUT_VoltCellMinID_Dat 255 "Invalid" ;
VAL_ 929 ZCUT_SubRESSNum_Val 255 "Invalid" ;
VAL_ 929 ZCUT_VoltCellMin_Val 65535 "Invalid" ;
VAL_ 929 ZCUT_SubRESSID_Dat 255 "Invalid" ;
VAL_ 929 ZCUT_SOE_Val 4095 "Invalid" ;
VAL_ 929 ZCUT_CellUnderVolt_St 0 "Not fault" 1 "Fault" ;
VAL_ 929 ZCUT_PackOverVolt_St 0 "No Fault" 1 "Fault" ;
VAL_ 929 ZCUT_PackUnderVolt_St 0 "No Fault" 1 "Fault" ;
VAL_ 929 ZCUT_CellOverVolt_St 0 "Not fault" 1 "Fault" ;
VAL_ 929 ZCUT_SOCLow_St 0 "No Fault" 1 "Fault" ;
VAL_ 929 ZCUT_SOCHigh_St 0 "No Fault" 1 "Fault" ;
VAL_ 929 ZCUT_SOCSkip_St 0 "正常" 1 "SOC跳变报警" ;
VAL_ 929 ZCUT_Mismatch_St 0 "Match" 1 "Mismatch" ;
VAL_ 929 ZCUT_CellVoltDeviation_St 0 "单体一致性正常" 1 "单体一致性差" ;
VAL_ 929 ZCUT_CellTempDeviation_St 0 "单体一致性正常" 1 "单体一致性差" ;
VAL_ 929 ZCUT_BatVolHighID_Dat 255 "Invalid" ;
VAL_ 929 ZCUT_BatVolLowID_Dat 255 "Invalid" ;
VAL_ 82 PCU_DCDCMode_St 0 "Init" 1 "Standby" 2 "Buck" 3 "UdcLnkDischarge" 4 "Boost" 5 "Failure" 6 "Shutdown" 7 "Derating" ;
VAL_ 209 PCU_OBCACChrgCnctor_St 0 "No Connected" 1 "Connected" 2 "Abnormal" 3 "Half Connected" ;
VAL_ 402 CCM_ChrgCapPst_St 255 "Invalid" ;
VAL_ 402 CCM_ChrgCapMv_St 0 "stop" 1 "opening" 2 "closeing" 3 "Reserved" ;
VAL_ 402 ZCUT_FD_RT_1_CCMAvailable_St 0 "Available" 1 "Not available" 2 "Reserved" 3 "Reserved" ;
VAL_ 402 CCM_ChrgCapLearn_St 0 "Invalid" 1 "not learnt" 2 "learnt" 3 "learning" ;
VAL_ 402 CCM_ChrgCapStpRsn_St 0 "invalid" 1 "undervoltage error" 2 "overvoltage error" 3 "overtemprature error" 4 "Mechanical jamming" 5 "mechanical break" 6 "electrical error" 7 "reserved" 8 "reserved" 9 "reserved" 10 "reserved" 11 "reserved" 12 "reserved" 13 "reserved" 14 "reserved" 15 "reserved" ;
VAL_ 402 CCM_ChrgCapStp_Req 0 "No Request" 1 "Heat Protect" 2 "Voltage abnormal （预留）" 3 "Reserved" ;
VAL_ 1105 ZCUT_RepeatMsgReq_VB1 0 "Repeat Message State not requested" 1 "Repeat Message State requested" ;
VAL_ 1105 ZCUT_ActiveWakeup_VB1 0 "passive Wakeup" 1 "active Wakeup" ;
VAL_ 1105 ZCUT_PartialNetworkInfo_VB1 0 "NM PDU contains no Partial Network request information" 1 "NM PDU contains Partial Network request information" ;
VAL_ 1105 ZCUT_RepeatMsgSt_VB1 0 "Not in Repeat Message State" 1 "In Repeat Message State" ;
VAL_ 1105 ZCUT_PN_HDBT_VB1 0 "No Request" 1 "Request" ;
VAL_ 1105 ZCUT_PN_HDBI_VB1 0 "No Request" 1 "Request" ;
VAL_ 1105 ZCUT_PN_HDBA_VB1 0 "No Request" 1 "Request" ;
VAL_ 1105 ZCUT_PN_HDBM_VB1 0 "No Request" 1 "Request" ;
VAL_ 1105 ZCUT_PN_ZCUF_VB1 0 "No Request" 1 "Request" ;
VAL_ 1105 ZCUT_PN_ZCUL_VB1 0 "No Request" 1 "Request" ;
VAL_ 1105 ZCUT_PN_ZCUR_VB1 0 "No Request" 1 "Request" ;
VAL_ 1105 ZCUT_PN_ZCUT_VB1 0 "No Request" 1 "Request" ;
VAL_ 546 PCU_OBCACSocketLock_St 0 "Default" 1 "Unlocked" 2 "Reserved" 3 "Locked" 4 "Unlock Fault" 5 "Lock Fault" 6 "Reserved" 7 "Reserved" ;
VAL_ 1328 PLGM_TLthNeutral_St 0 "off" 1 "on" ;
VAL_ 1328 PLGM_TLthHlfLck_St 0 "off" 1 "on" ;
VAL_ 1328 PLGM_TLthAjar_St 0 "off" 1 "on" ;
VAL_ 1328 PLGM_TDrWrk_St 0 "stop" 1 "closing" 2 "opening" 3 "manual closing" 4 "manual opening" 5 "reserved" 6 "reserved" 7 "reserved" ;
VAL_ 1328 PLGM_TDrTripPst_Val 255 "Invalid" ;
VAL_ 1328 PLGM_TDrTchpadSW_St 0 "not press" 1 "press" 2 "reserved" 3 "invalid" ;
VAL_ 1328 PLGM_TDrStpRsn_St 0 "inactive" 1 "move to expected position" 2 "pinch or stall occured" 3 "spindle fault" 4 "spindle sensor fault" 5 "drive timeout" 6 "heat protected" 7 "pinch protected" 8 "power status abnormal" 9 "latch release/cinch fail" 10 "over max open angle" 11 "command conflict" 12 "reserved" 13 "reserved" 14 "reserved" 15 "reserved" 16 "reserved" 17 "reserved" 18 "reserved" 19 "reserved" 20 "reserved" 21 "reserved" 22 "reserved" 23 "reserved" 24 "reserved" 25 "reserved" 26 "reserved" 27 "reserved" 28 "reserved" 29 "reserved" 30 "reserved" 31 "reserved" ;
VAL_ 1328 PLGM_TDrLthWrk_St 0 "stop" 1 "cinching" 2 "releasing" 3 "resuming after cinch" 4 "resuming after release" 5 "initialing" 6 "brake" 7 "reserved" ;
VAL_ 1328 PLGM_TDrLth_St 0 "unlatched" 1 "half latched" 2 "full latched" 3 "medium" 4 "reserved" 5 "reserved" 6 "reserved" 7 "reserved" ;
VAL_ 1328 PLGM_TDrLth_Err 0 "normal" 1 "short to battery" 2 "short to ground" 3 "open load" 4 "reserved" 5 "reserved" 6 "reserved" 7 "reserved" ;
VAL_ 1328 PLGM_TDrIntSW_St 0 "not press" 1 "press" 2 "reserved" 3 "Invalid" ;
VAL_ 1328 PLGM_SpdlStallEvt_St 0 "not stall" 1 "stall" ;
VAL_ 1328 PLGM_PinchEvt_St 0 "not pinch" 1 "LAPS pinch" 2 "RAPS pinch" 3 "both APS pinch" 4 "reserved" 5 "reserved" 6 "reserved" 7 "reserved" ;
VAL_ 1328 PLGM_Followup_Req 0 "no request" 1 "close" 2 "open" 3 "reserved" ;
VAL_ 1328 PLGM_TDrLSpdl_Err 0 "normal" 1 "short to battery" 2 "short to ground" 3 "open load" 4 "reserved" 5 "reserved" 6 "reserved" 7 "reserved" ;
VAL_ 1328 PLGM_TDrRSpdl_Err 0 "normal" 1 "short to battery" 2 "short to ground" 3 "open load" 4 "reserved" 5 "reserved" 6 "reserved" 7 "reserved" ;
VAL_ 1328 PLGM_InitLearn_St 0 "not learnt" 1 "learnt" 2 "reserved" 3 "reserved" ;
VAL_ 1328 PLGM_MaxPstLn_St 0 "not learnt" 1 "learnt" 2 "reserved" 3 "Invalid" ;
VAL_ 897 ZCUT_ChargeHVPower_Val 16383 "Invalid" ;
VAL_ 897 ZCUT_RemainChrgTime_Val 4095 "Invalid" ;
VAL_ 897 ZCUT_SRRSeatVtltStpRsn_St 0 "Default" 1 "Stop Command" 2 "Open Circuit" 3 "Short Circuit" 4 "Reserved" 5 "Over Current" 6 "Drive Timeout" 7 "reserved" 8 "reserved" 9 "reserved" 10 "reserved" 11 "reserved" 12 "reserved" 13 "reserved" 14 "reserved" 15 "reserved" ;
VAL_ 897 ZCUT_SRLSeatHtStpRsn_St 0 "Default" 1 "Stop Command" 2 "Open Circuit" 3 "Short Circuit" 4 "Reserved" 5 "Over Current" 6 "Drive Timeout" 7 "reserved" 8 "reserved" 9 "reserved" 10 "reserved" 11 "reserved" 12 "reserved" 13 "reserved" 14 "reserved" 15 "reserved" ;
VAL_ 897 ZCUT_SRLSeatVtltStpRsn_St 0 "Default" 1 "Stop Command" 2 "Open Circuit" 3 "Short Circuit" 4 "Reserved" 5 "Over Current" 6 "Drive Timeout" 7 "reserved" 8 "reserved" 9 "reserved" 10 "reserved" 11 "reserved" 12 "reserved" 13 "reserved" 14 "reserved" 15 "reserved" ;
VAL_ 897 ZCUT_SRRSeatHtStpRsn_St 0 "Default" 1 "Stop Command" 2 "Open Circuit" 3 "Short Circuit" 4 "Reserved" 5 "Over Current" 6 "Drive Timeout" 7 "reserved" 8 "reserved" 9 "reserved" 10 "reserved" 11 "reserved" 12 "reserved" 13 "reserved" 14 "reserved" 15 "reserved" ;
VAL_ 256 ZCUR_FRHdlOprt_St 0 "inactive" 1 "active" 2 "reserved" 3 "Invalid" ;
VAL_ 256 ZCUR_RRHdlOprt_St 0 "inactive" 1 "active" 2 "reserved" 3 "Invalid" ;
VAL_ 256 ZCUR_FRDrIntSW_St 0 "not press" 1 "press" 2 "reserved" 3 "invalid" ;
VAL_ 256 ZCUR_RRDrIntSW_St 0 "not press" 1 "press" 2 "reserved" 3 "Invalid" ;
VAL_ 256 ZCUR_SFRTnLt_St 0 "OFF" 1 "ON" ;
VAL_ 256 ZCUR_FRSeatOcp_St 0 "Unoccupied" 1 "Occupied" 2 "Reserved" 3 "Invalid" ;
VAL_ 256 ZCUR_FRWinPst_Rsp 255 "Invalid" ;
VAL_ 256 ZCUR_RRWinPst_Rsp 255 "Invalid" ;
